VERSION ""

NS_ :

BS_:

BU_: FICM_FD Vector__XXX

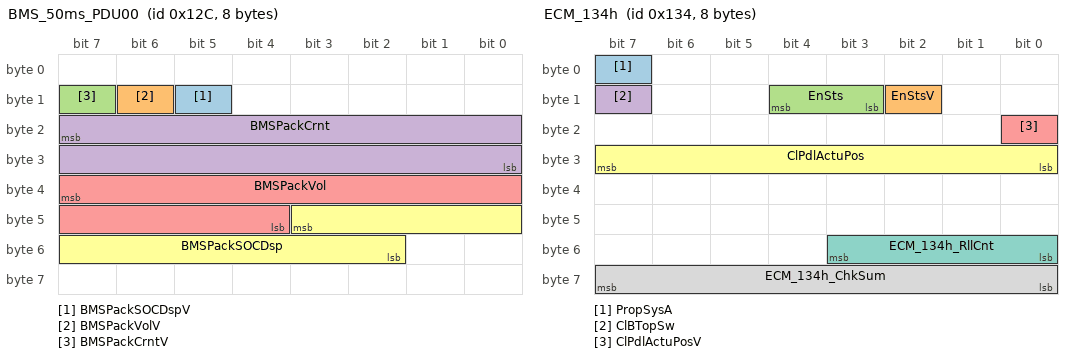
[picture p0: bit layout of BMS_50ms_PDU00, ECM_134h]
BO_ 300 BMS_50ms_PDU00: 8 Vector__XXX
 SG_ BMSPackSOCDspV : 13|1@0+ (1,0) [0|1] ""  FICM_FD
 SG_ BMSPackVolV : 14|1@0+ (1,0) [0|1] ""  FICM_FD
 SG_ BMSPackCrntV : 15|1@0+ (1,0) [0|1] ""  FICM_FD
 SG_ BMSPackCrnt : 23|16@0+ (0.05,-1000) [-1000|2276.75] "A"  FICM_FD
 SG_ BMSPackVol : 39|12@0+ (0.25,0) [0|1023.75] "V"  FICM_FD
 SG_ BMSPackSOCDsp : 43|10@0+ (0.1,0) [0|102.3] "%"  FICM_FD

BO_ 308 ECM_134h: 8 Vector__XXX
 SG_ PropSysA : 7|1@0+ (1,0) [0|1] ""  FICM_FD
 SG_ EnStsV : 10|1@0+ (1,0) [0|1] ""  FICM_FD
 SG_ EnSts : 12|2@0+ (1,0) [0|3] ""  FICM_FD
 SG_ ClBTopSw : 15|1@0+ (1,0) [0|1] ""  FICM_FD
 SG_ ClPdlActuPosV : 16|1@0+ (1,0) [0|1] ""  FICM_FD
 SG_ ClPdlActuPos : 31|8@0+ (0.4,0) [0|100] "%"  FICM_FD
 SG_ ECM_134h_RllCnt : 51|4@0+ (1,0) [0|15] ""  FICM_FD
 SG_ ECM_134h_ChkSum : 63|8@0+ (1,0) [0|255] ""  FICM_FD

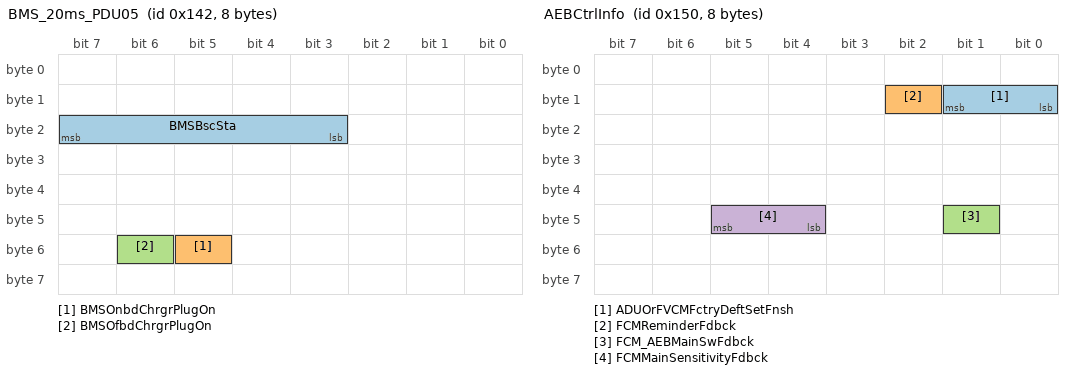
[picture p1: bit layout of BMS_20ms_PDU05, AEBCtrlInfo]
BO_ 322 BMS_20ms_PDU05: 8 Vector__XXX
 SG_ BMSBscSta : 23|5@0+ (1,0) [0|31] ""  FICM_FD
 SG_ BMSOnbdChrgrPlugOn : 53|1@0+ (1,0) [0|1] ""  FICM_FD
 SG_ BMSOfbdChrgrPlugOn : 54|1@0+ (1,0) [0|1] ""  FICM_FD

BO_ 336 AEBCtrlInfo: 8 Vector__XXX
 SG_ ADUOrFVCMFctryDeftSetFnsh : 9|2@0+ (1,0) [0|3] ""  FICM_FD
 SG_ FCMReminderFdbck : 10|1@0+ (1,0) [0|1] ""  FICM_FD
 SG_ FCM_AEBMainSwFdbck : 41|1@0+ (1,0) [0|1] ""  FICM_FD
 SG_ FCMMainSensitivityFdbck : 45|2@0+ (1,0) [0|3] ""  FICM_FD

BO_ 338 ACCCtrlInfo: 8 Vector__XXX
 SG_ ICA_ALCAMainSwFdbck : 5|1@0+ (1,0) [0|1] ""  FICM_FD

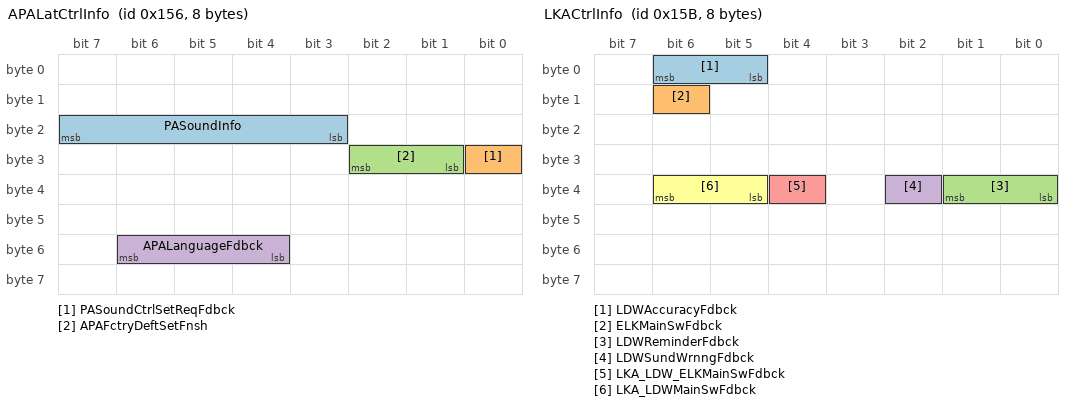
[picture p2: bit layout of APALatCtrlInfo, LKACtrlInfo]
BO_ 342 APALatCtrlInfo: 8 Vector__XXX
 SG_ PASoundInfo : 23|5@0+ (1,0) [0|31] ""  FICM_FD
 SG_ PASoundCtrlSetReqFdbck : 24|1@0+ (1,0) [0|1] ""  FICM_FD
 SG_ APAFctryDeftSetFnsh : 26|2@0+ (1,0) [0|3] ""  FICM_FD
 SG_ APALanguageFdbck : 54|3@0+ (1,0) [0|7] ""  FICM_FD

BO_ 343 APALngtCtrlInfo: 8 Vector__XXX
 SG_ RPASts : 44|3@0+ (1,0) [0|7] ""  FICM_FD
 SG_ APASts : 47|3@0+ (1,0) [0|7] ""  FICM_FD

BO_ 345 AESCtrlInfo: 8 Vector__XXX
 SG_ AESMainSwFdbck : 22|1@0+ (1,0) [0|1] ""  FICM_FD

BO_ 347 LKACtrlInfo: 8 Vector__XXX
 SG_ LDWAccuracyFdbck : 6|2@0+ (1,0) [0|3] ""  FICM_FD
 SG_ ELKMainSwFdbck : 14|1@0+ (1,0) [0|1] ""  FICM_FD
 SG_ LDWReminderFdbck : 33|2@0+ (1,0) [0|3] ""  FICM_FD
 SG_ LDWSundWrnngFdbck : 34|1@0+ (1,0) [0|1] ""  FICM_FD
 SG_ LKA_LDW_ELKMainSwFdbck : 36|1@0+ (1,0) [0|1] ""  FICM_FD
 SG_ LKA_LDWMainSwFdbck : 38|2@0+ (1,0) [0|3] ""  FICM_FD

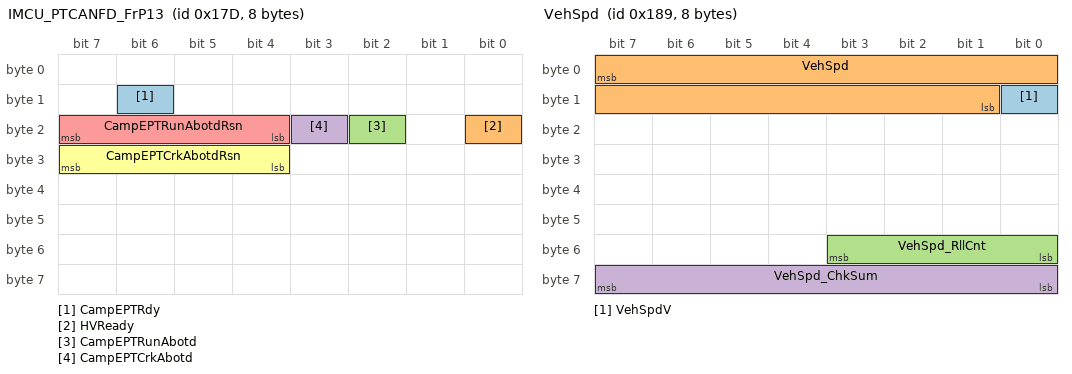
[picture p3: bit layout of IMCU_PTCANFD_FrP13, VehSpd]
BO_ 381 IMCU_PTCANFD_FrP13: 8 Vector__XXX
 SG_ CampEPTRdy : 14|1@0+ (1,0) [0|1] ""  FICM_FD
 SG_ HVReady : 16|1@0+ (1,0) [0|1] ""  FICM_FD
 SG_ CampEPTRunAbotd : 18|1@0+ (1,0) [0|1] ""  FICM_FD
 SG_ CampEPTCrkAbotd : 19|1@0+ (1,0) [0|1] ""  FICM_FD
 SG_ CampEPTRunAbotdRsn : 23|4@0+ (1,0) [0|15] ""  FICM_FD
 SG_ CampEPTCrkAbotdRsn : 31|4@0+ (1,0) [0|15] ""  FICM_FD

BO_ 393 VehSpd: 8 Vector__XXX
 SG_ VehSpdV : 8|1@0+ (1,0) [0|1] ""  FICM_FD
 SG_ VehSpd : 7|15@0+ (0.015625,0) [0|511.98] "km/h"  FICM_FD
 SG_ VehSpd_RllCnt : 51|4@0+ (1,0) [0|15] ""  FICM_FD
 SG_ VehSpd_ChkSum : 63|8@0+ (1,0) [0|255] ""  FICM_FD

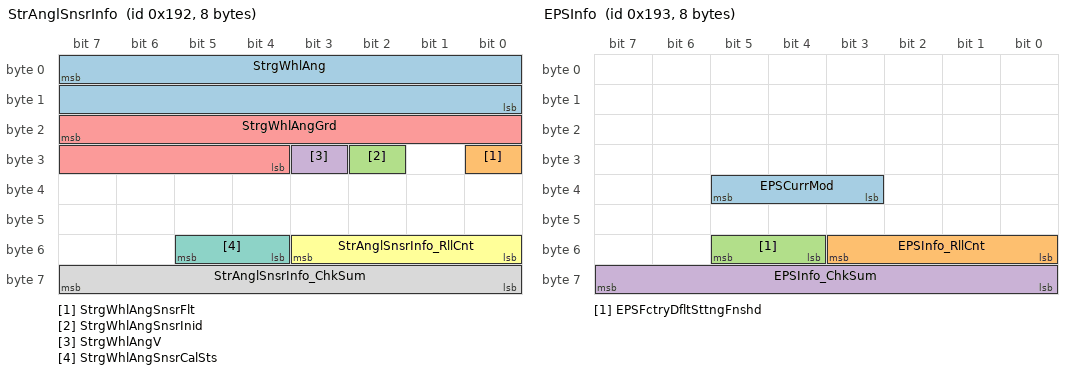
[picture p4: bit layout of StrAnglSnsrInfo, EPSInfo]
BO_ 402 StrAnglSnsrInfo: 8 Vector__XXX
 SG_ StrgWhlAng : 7|16@0+ (0.0625,-2048) [-2048|2047.9375] "deg"  FICM_FD
 SG_ StrgWhlAngSnsrFlt : 24|1@0+ (1,0) [0|1] ""  FICM_FD
 SG_ StrgWhlAngSnsrInid : 26|1@0+ (1,0) [0|1] ""  FICM_FD
 SG_ StrgWhlAngV : 27|1@0+ (1,0) [0|1] ""  FICM_FD
 SG_ StrgWhlAngGrd : 23|12@0+ (1,-2048) [-2048|2047] "deg/s"  FICM_FD
 SG_ StrAnglSnsrInfo_RllCnt : 51|4@0+ (1,0) [0|15] ""  FICM_FD
 SG_ StrgWhlAngSnsrCalSts : 53|2@0+ (1,0) [0|3] ""  FICM_FD
 SG_ StrAnglSnsrInfo_ChkSum : 63|8@0+ (1,0) [0|255] ""  FICM_FD

BO_ 403 EPSInfo: 8 Vector__XXX
 SG_ EPSCurrMod : 37|3@0+ (1,0) [0|7] ""  FICM_FD
 SG_ EPSInfo_RllCnt : 51|4@0+ (1,0) [0|15] ""  FICM_FD
 SG_ EPSFctryDfltSttngFnshd : 53|2@0+ (1,0) [0|3] ""  FICM_FD
 SG_ EPSInfo_ChkSum : 63|8@0+ (1,0) [0|255] ""  FICM_FD

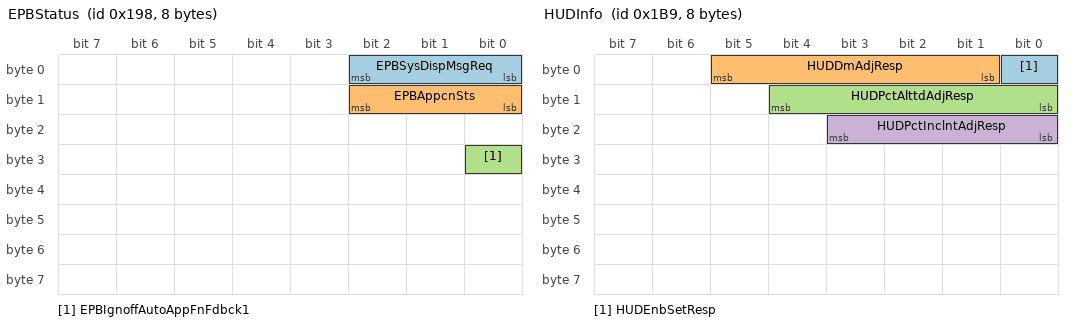
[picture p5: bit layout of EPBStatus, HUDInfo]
BO_ 408 EPBStatus: 8 Vector__XXX
 SG_ EPBSysDispMsgReq : 2|3@0+ (1,0) [0|7] ""  FICM_FD
 SG_ EPBAppcnSts : 10|3@0+ (1,0) [0|7] ""  FICM_FD
 SG_ EPBIgnoffAutoAppFnFdbck1 : 24|1@0+ (1,0) [0|1] ""  FICM_FD

BO_ 441 HUDInfo: 8 Vector__XXX
 SG_ HUDEnbSetResp : 0|1@0+ (1,0) [0|1] ""  FICM_FD
 SG_ HUDDmAdjResp : 5|5@0+ (1,0) [0|31] ""  FICM_FD
 SG_ HUDPctAlttdAdjResp : 12|5@0+ (1,0) [0|31] ""  FICM_FD
 SG_ HUDPctInclntAdjResp : 19|4@0+ (1,0) [0|15] ""  FICM_FD

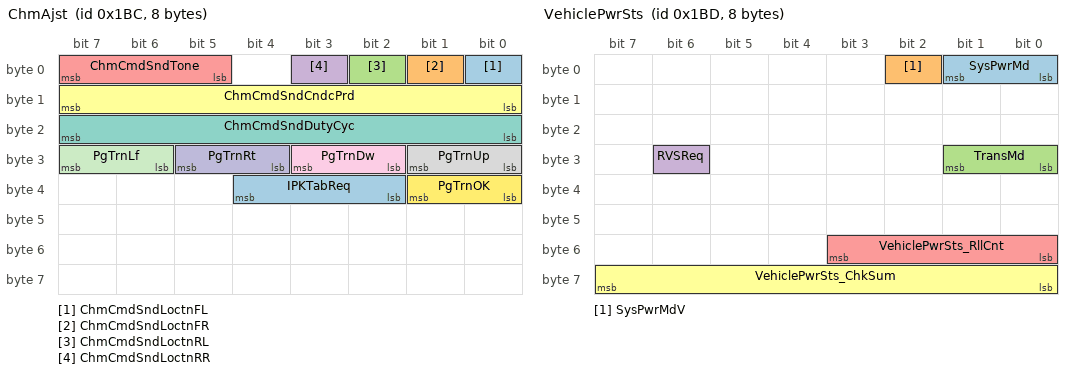
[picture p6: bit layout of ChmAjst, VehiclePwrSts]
BO_ 444 ChmAjst: 8 Vector__XXX
 SG_ ChmCmdSndLoctnFL : 0|1@0+ (1,0) [0|1] ""  FICM_FD
 SG_ ChmCmdSndLoctnFR : 1|1@0+ (1,0) [0|1] ""  FICM_FD
 SG_ ChmCmdSndLoctnRL : 2|1@0+ (1,0) [0|1] ""  FICM_FD
 SG_ ChmCmdSndLoctnRR : 3|1@0+ (1,0) [0|1] ""  FICM_FD
 SG_ ChmCmdSndTone : 7|3@0+ (1,0) [0|7] ""  FICM_FD
 SG_ ChmCmdSndCndcPrd : 15|8@0+ (10,0) [0|2550] ""  FICM_FD
 SG_ ChmCmdSndDutyCyc : 23|8@0+ (0.4,0) [0|100] "%"  FICM_FD
 SG_ PgTrnUp : 25|2@0+ (1,0) [0|3] ""  FICM_FD
 SG_ PgTrnDw : 27|2@0+ (1,0) [0|3] ""  FICM_FD
 SG_ PgTrnRt : 29|2@0+ (1,0) [0|3] ""  FICM_FD
 SG_ PgTrnLf : 31|2@0+ (1,0) [0|3] ""  FICM_FD
 SG_ PgTrnOK : 33|2@0+ (1,0) [0|3] ""  FICM_FD
 SG_ IPKTabReq : 36|3@0+ (1,0) [0|7] ""  FICM_FD

BO_ 445 VehiclePwrSts: 8 Vector__XXX
 SG_ SysPwrMd : 1|2@0+ (1,0) [0|3] ""  FICM_FD
 SG_ SysPwrMdV : 2|1@0+ (1,0) [0|1] ""  FICM_FD
 SG_ TransMd : 25|2@0+ (1,0) [0|3] ""  FICM_FD
 SG_ RVSReq : 30|1@0+ (1,0) [0|1] ""  FICM_FD
 SG_ VehiclePwrSts_RllCnt : 51|4@0+ (1,0) [0|15] ""  FICM_FD
 SG_ VehiclePwrSts_ChkSum : 63|8@0+ (1,0) [0|255] ""  FICM_FD

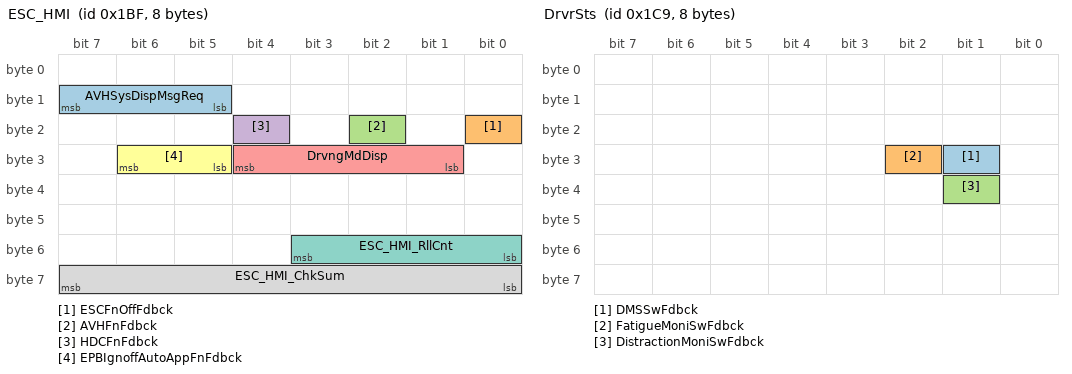
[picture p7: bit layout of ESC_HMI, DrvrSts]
BO_ 447 ESC_HMI: 8 Vector__XXX
 SG_ AVHSysDispMsgReq : 15|3@0+ (1,0) [0|7] ""  FICM_FD
 SG_ ESCFnOffFdbck : 16|1@0+ (1,0) [0|1] ""  FICM_FD
 SG_ AVHFnFdbck : 18|1@0+ (1,0) [0|1] ""  FICM_FD
 SG_ HDCFnFdbck : 20|1@0+ (1,0) [0|1] ""  FICM_FD
 SG_ DrvngMdDisp : 28|4@0+ (1,0) [0|15] ""  FICM_FD
 SG_ EPBIgnoffAutoAppFnFdbck : 30|2@0+ (1,0) [0|3] ""  FICM_FD
 SG_ ESC_HMI_RllCnt : 51|4@0+ (1,0) [0|15] ""  FICM_FD
 SG_ ESC_HMI_ChkSum : 63|8@0+ (1,0) [0|255] ""  FICM_FD

BO_ 457 DrvrSts: 8 Vector__XXX
 SG_ DMSSwFdbck : 25|1@0+ (1,0) [0|1] ""  FICM_FD
 SG_ FatigueMoniSwFdbck : 26|1@0+ (1,0) [0|1] ""  FICM_FD
 SG_ DistractionMoniSwFdbck : 33|1@0+ (1,0) [0|1] ""  FICM_FD

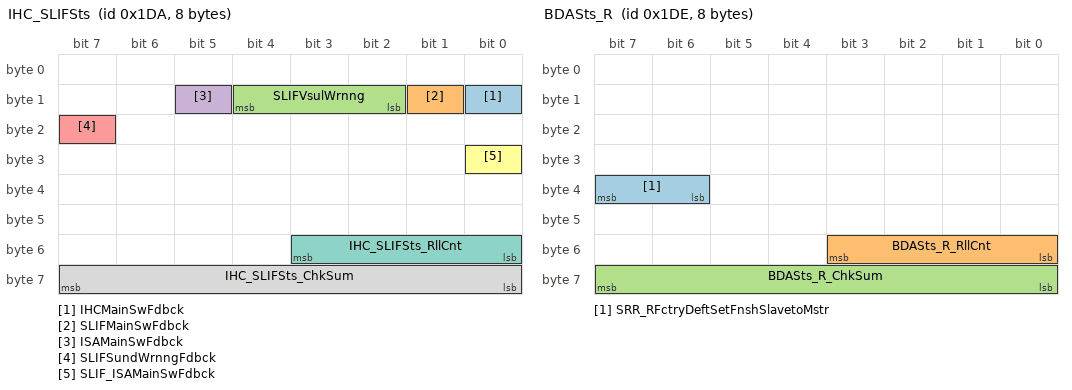
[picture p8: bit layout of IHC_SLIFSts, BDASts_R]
BO_ 474 IHC_SLIFSts: 8 Vector__XXX
 SG_ IHCMainSwFdbck : 8|1@0+ (1,0) [0|1] ""  FICM_FD
 SG_ SLIFMainSwFdbck : 9|1@0+ (1,0) [0|1] ""  FICM_FD
 SG_ SLIFVsulWrnng : 12|3@0+ (1,0) [0|7] ""  FICM_FD
 SG_ ISAMainSwFdbck : 13|1@0+ (1,0) [0|1] ""  FICM_FD
 SG_ SLIFSundWrnngFdbck : 23|1@0+ (1,0) [0|1] ""  FICM_FD
 SG_ SLIF_ISAMainSwFdbck : 24|1@0+ (1,0) [0|1] ""  FICM_FD
 SG_ IHC_SLIFSts_RllCnt : 51|4@0+ (1,0) [0|15] ""  FICM_FD
 SG_ IHC_SLIFSts_ChkSum : 63|8@0+ (1,0) [0|255] ""  FICM_FD

BO_ 476 FCTA_RCWInfo: 8 Vector__XXX
 SG_ RAEBSta : 28|3@0+ (1,0) [0|7] ""  FICM_FD

BO_ 478 BDASts_R: 8 Vector__XXX
 SG_ SRR_RFctryDeftSetFnshSlavetoMstr : 39|2@0+ (1,0) [0|3] ""  FICM_FD
 SG_ BDASts_R_RllCnt : 51|4@0+ (1,0) [0|15] ""  FICM_FD
 SG_ BDASts_R_ChkSum : 63|8@0+ (1,0) [0|255] ""  FICM_FD

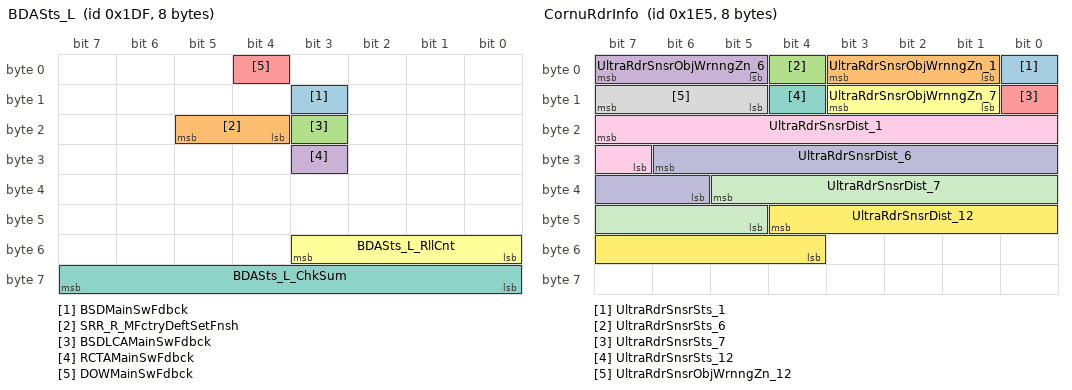
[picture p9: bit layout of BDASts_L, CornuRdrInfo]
BO_ 479 BDASts_L: 8 Vector__XXX
 SG_ BSDMainSwFdbck : 11|1@0+ (1,0) [0|1] ""  FICM_FD
 SG_ SRR_R_MFctryDeftSetFnsh : 21|2@0+ (1,0) [0|3] ""  FICM_FD
 SG_ BSDLCAMainSwFdbck : 19|1@0+ (1,0) [0|1] ""  FICM_FD
 SG_ RCTAMainSwFdbck : 27|1@0+ (1,0) [0|1] ""  FICM_FD
 SG_ DOWMainSwFdbck : 4|1@0+ (1,0) [0|1] ""  FICM_FD
 SG_ BDASts_L_RllCnt : 51|4@0+ (1,0) [0|15] ""  FICM_FD
 SG_ BDASts_L_ChkSum : 63|8@0+ (1,0) [0|255] ""  FICM_FD

BO_ 485 CornuRdrInfo: 8 Vector__XXX
 SG_ UltraRdrSnsrSts_1 : 0|1@0+ (1,0) [0|1] ""  FICM_FD
 SG_ UltraRdrSnsrObjWrnngZn_1 : 3|3@0+ (1,0) [0|7] ""  FICM_FD
 SG_ UltraRdrSnsrSts_6 : 4|1@0+ (1,0) [0|1] ""  FICM_FD
 SG_ UltraRdrSnsrObjWrnngZn_6 : 7|3@0+ (1,0) [0|7] ""  FICM_FD
 SG_ UltraRdrSnsrSts_7 : 8|1@0+ (1,0) [0|1] ""  FICM_FD
 SG_ UltraRdrSnsrObjWrnngZn_7 : 11|3@0+ (1,0) [0|7] ""  FICM_FD
 SG_ UltraRdrSnsrSts_12 : 12|1@0+ (1,0) [0|1] ""  FICM_FD
 SG_ UltraRdrSnsrObjWrnngZn_12 : 15|3@0+ (1,0) [0|7] ""  FICM_FD
 SG_ UltraRdrSnsrDist_1 : 23|9@0+ (1,0) [0|510] "cm"  FICM_FD
 SG_ UltraRdrSnsrDist_6 : 30|9@0+ (1,0) [0|510] "cm"  FICM_FD
 SG_ UltraRdrSnsrDist_7 : 37|9@0+ (1,0) [0|510] "cm"  FICM_FD
 SG_ UltraRdrSnsrDist_12 : 44|9@0+ (1,0) [0|510] "cm"  FICM_FD

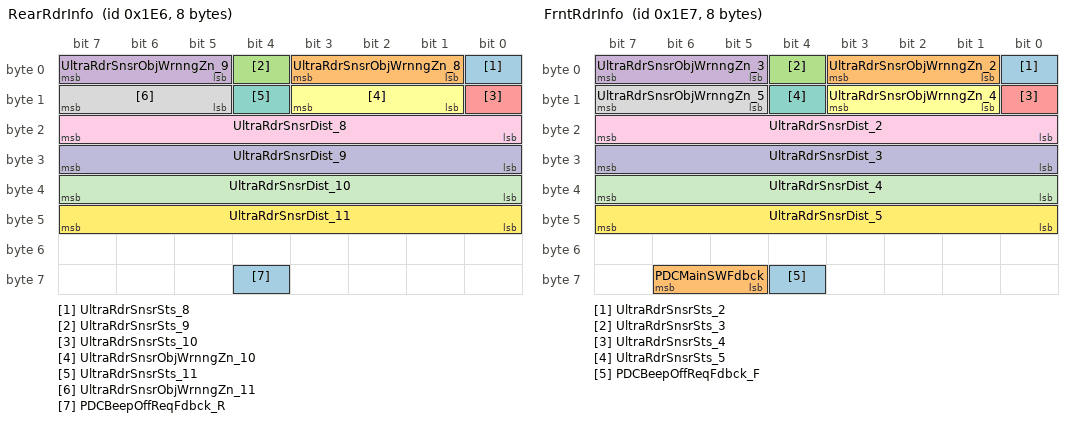
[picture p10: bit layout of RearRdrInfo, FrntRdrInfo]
BO_ 486 RearRdrInfo: 8 Vector__XXX
 SG_ UltraRdrSnsrSts_8 : 0|1@0+ (1,0) [0|1] ""  FICM_FD
 SG_ UltraRdrSnsrObjWrnngZn_8 : 3|3@0+ (1,0) [0|7] ""  FICM_FD
 SG_ UltraRdrSnsrSts_9 : 4|1@0+ (1,0) [0|1] ""  FICM_FD
 SG_ UltraRdrSnsrObjWrnngZn_9 : 7|3@0+ (1,0) [0|7] ""  FICM_FD
 SG_ UltraRdrSnsrSts_10 : 8|1@0+ (1,0) [0|1] ""  FICM_FD
 SG_ UltraRdrSnsrObjWrnngZn_10 : 11|3@0+ (1,0) [0|7] ""  FICM_FD
 SG_ UltraRdrSnsrSts_11 : 12|1@0+ (1,0) [0|1] ""  FICM_FD
 SG_ UltraRdrSnsrObjWrnngZn_11 : 15|3@0+ (1,0) [0|7] ""  FICM_FD
 SG_ UltraRdrSnsrDist_8 : 23|8@0+ (1,0) [0|254] "cm"  FICM_FD
 SG_ UltraRdrSnsrDist_9 : 31|8@0+ (1,0) [0|254] "cm"  FICM_FD
 SG_ UltraRdrSnsrDist_10 : 39|8@0+ (1,0) [0|254] "cm"  FICM_FD
 SG_ UltraRdrSnsrDist_11 : 47|8@0+ (1,0) [0|254] "cm"  FICM_FD
 SG_ PDCBeepOffReqFdbck_R : 60|1@0+ (1,0) [0|1] ""  FICM_FD

BO_ 487 FrntRdrInfo: 8 Vector__XXX
 SG_ UltraRdrSnsrSts_2 : 0|1@0+ (1,0) [0|1] ""  FICM_FD
 SG_ UltraRdrSnsrObjWrnngZn_2 : 3|3@0+ (1,0) [0|7] ""  FICM_FD
 SG_ UltraRdrSnsrSts_3 : 4|1@0+ (1,0) [0|1] ""  FICM_FD
 SG_ UltraRdrSnsrObjWrnngZn_3 : 7|3@0+ (1,0) [0|7] ""  FICM_FD
 SG_ UltraRdrSnsrSts_4 : 8|1@0+ (1,0) [0|1] ""  FICM_FD
 SG_ UltraRdrSnsrObjWrnngZn_4 : 11|3@0+ (1,0) [0|7] ""  FICM_FD
 SG_ UltraRdrSnsrSts_5 : 12|1@0+ (1,0) [0|1] ""  FICM_FD
 SG_ UltraRdrSnsrObjWrnngZn_5 : 15|3@0+ (1,0) [0|7] ""  FICM_FD
 SG_ UltraRdrSnsrDist_2 : 23|8@0+ (1,0) [0|254] "cm"  FICM_FD
 SG_ UltraRdrSnsrDist_3 : 31|8@0+ (1,0) [0|254] "cm"  FICM_FD
 SG_ UltraRdrSnsrDist_4 : 39|8@0+ (1,0) [0|254] "cm"  FICM_FD
 SG_ UltraRdrSnsrDist_5 : 47|8@0+ (1,0) [0|254] "cm"  FICM_FD
 SG_ PDCBeepOffReqFdbck_F : 60|1@0+ (1,0) [0|1] ""  FICM_FD
 SG_ PDCMainSWFdbck : 62|2@0+ (1,0) [0|3] ""  FICM_FD

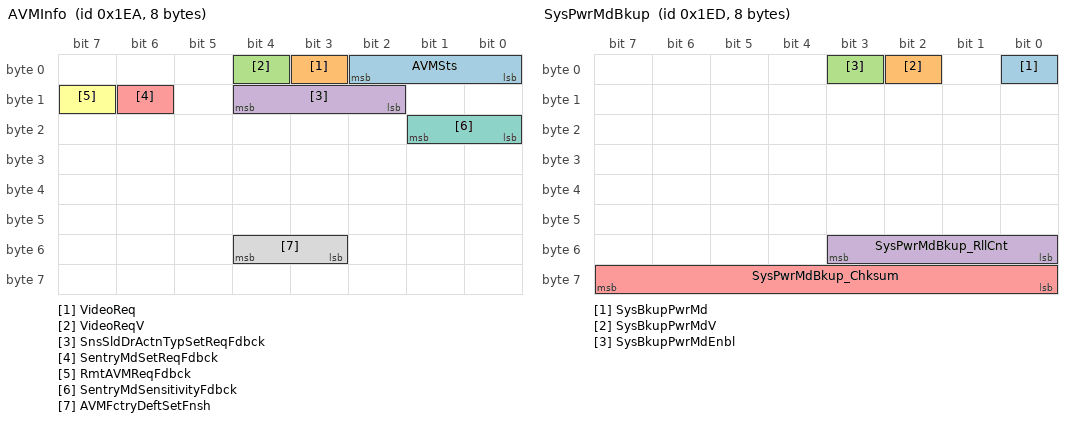
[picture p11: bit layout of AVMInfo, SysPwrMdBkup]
BO_ 490 AVMInfo: 8 FICM_FD
 SG_ AVMSts : 2|3@0+ (1,0) [0|7] ""  FICM_FD,Vector__XXX
 SG_ VideoReq : 3|1@0+ (1,0) [0|1] ""  FICM_FD,Vector__XXX
 SG_ VideoReqV : 4|1@0+ (1,0) [0|1] ""  FICM_FD,Vector__XXX
 SG_ SnsSldDrActnTypSetReqFdbck : 12|3@0+ (1,0) [0|7] ""  FICM_FD,Vector__XXX
 SG_ SentryMdSetReqFdbck : 14|1@0+ (1,0) [0|1] ""  FICM_FD,Vector__XXX
 SG_ RmtAVMReqFdbck : 15|1@0+ (1,0) [0|1] ""  FICM_FD,Vector__XXX
 SG_ SentryMdSensitivityFdbck : 17|2@0+ (1,0) [0|3] ""  FICM_FD,Vector__XXX
 SG_ AVMFctryDeftSetFnsh : 52|2@0+ (1,0) [0|3] ""  FICM_FD,Vector__XXX

BO_ 493 SysPwrMdBkup: 8 Vector__XXX
 SG_ SysBkupPwrMd : 0|1@0+ (1,0) [0|1] ""  FICM_FD
 SG_ SysBkupPwrMdV : 2|1@0+ (1,0) [0|1] ""  FICM_FD
 SG_ SysBkupPwrMdEnbl : 3|1@0+ (1,0) [0|1] ""  FICM_FD
 SG_ SysPwrMdBkup_RllCnt : 51|4@0+ (1,0) [0|15] ""  FICM_FD
 SG_ SysPwrMdBkup_Chksum : 63|8@0+ (1,0) [0|255] ""  FICM_FD

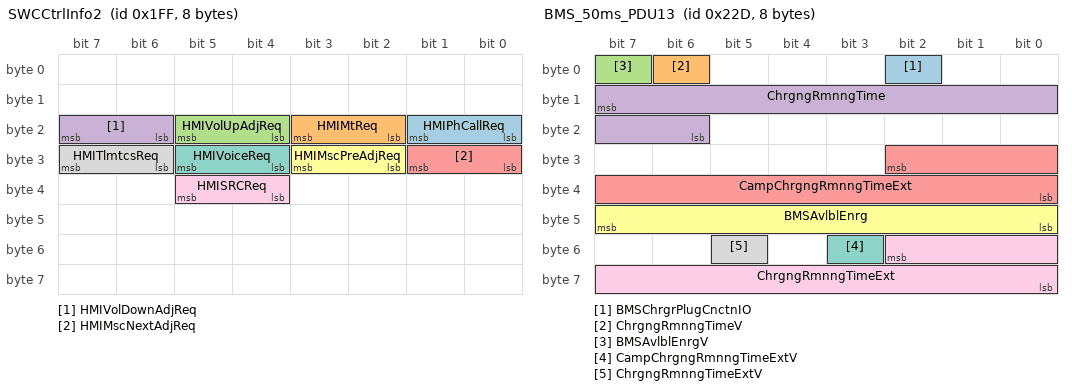
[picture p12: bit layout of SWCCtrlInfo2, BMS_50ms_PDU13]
BO_ 511 SWCCtrlInfo2: 8 Vector__XXX
 SG_ HMIPhCallReq : 17|2@0+ (1,0) [0|3] ""  FICM_FD
 SG_ HMIMtReq : 19|2@0+ (1,0) [0|3] ""  FICM_FD
 SG_ HMIVolUpAdjReq : 21|2@0+ (1,0) [0|3] ""  FICM_FD
 SG_ HMIVolDownAdjReq : 23|2@0+ (1,0) [0|3] ""  FICM_FD
 SG_ HMIMscNextAdjReq : 25|2@0+ (1,0) [0|3] ""  FICM_FD
 SG_ HMIMscPreAdjReq : 27|2@0+ (1,0) [0|3] ""  FICM_FD
 SG_ HMIVoiceReq : 29|2@0+ (1,0) [0|3] ""  FICM_FD
 SG_ HMITlmtcsReq : 31|2@0+ (1,0) [0|3] ""  FICM_FD
 SG_ HMISRCReq : 37|2@0+ (1,0) [0|3] ""  FICM_FD

BO_ 557 BMS_50ms_PDU13: 8 Vector__XXX
 SG_ BMSChrgrPlugCnctnIO : 2|1@0+ (1,0) [0|1] ""  FICM_FD
 SG_ ChrgngRmnngTimeV : 6|1@0+ (1,0) [0|1] ""  FICM_FD
 SG_ BMSAvlblEnrgV : 7|1@0+ (1,0) [0|1] ""  FICM_FD
 SG_ ChrgngRmnngTime : 15|10@0+ (1,0) [0|1023] "min"  FICM_FD
 SG_ CampChrgngRmnngTimeExt : 26|11@0+ (1,0) [0|2047] "min"  FICM_FD
 SG_ BMSAvlblEnrg : 47|8@0+ (0.4,0) [0|102] "KWH"  FICM_FD
 SG_ CampChrgngRmnngTimeExtV : 51|1@0+ (1,0) [0|1] ""  FICM_FD
 SG_ ChrgngRmnngTimeExtV : 53|1@0+ (1,0) [0|1] ""  FICM_FD
 SG_ ChrgngRmnngTimeExt : 50|11@0+ (1,0) [0|2047] "min"  FICM_FD

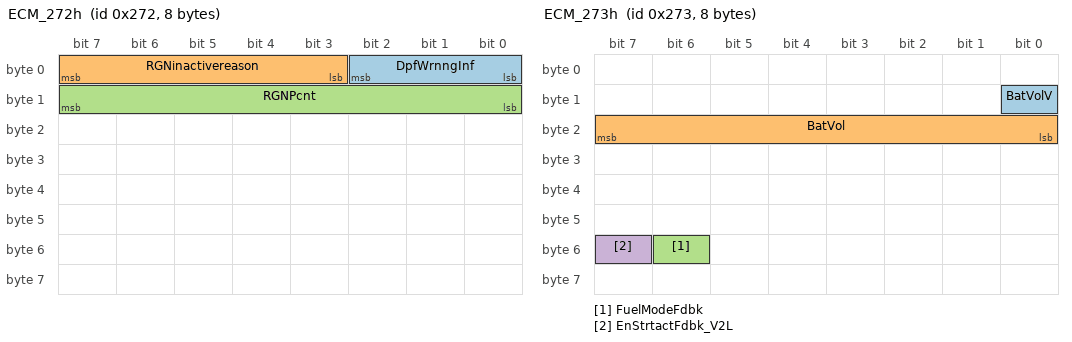
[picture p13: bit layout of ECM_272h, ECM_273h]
BO_ 626 ECM_272h: 8 Vector__XXX
 SG_ DpfWrnngInf : 2|3@0+ (1,0) [0|7] ""  FICM_FD
 SG_ RGNinactivereason : 7|5@0+ (1,0) [0|31] ""  FICM_FD
 SG_ RGNPcnt : 15|8@0+ (1,0) [0|100] "%"  FICM_FD

BO_ 627 ECM_273h: 8 Vector__XXX
 SG_ BatVolV : 8|1@0+ (1,0) [0|1] ""  FICM_FD
 SG_ BatVol : 23|8@0+ (0.1,3) [3|18.99] "V"  FICM_FD
 SG_ FuelModeFdbk : 54|1@0+ (1,0) [0|1] ""  FICM_FD
 SG_ EnStrtactFdbk_V2L : 55|1@0+ (1,0) [0|1] ""  FICM_FD

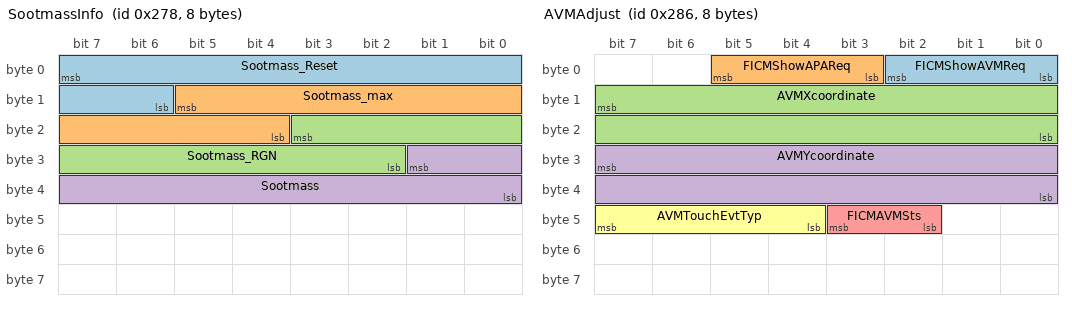
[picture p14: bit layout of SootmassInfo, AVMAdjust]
BO_ 632 SootmassInfo: 8 Vector__XXX
 SG_ Sootmass_Reset : 7|10@0+ (0.1,0) [0|100] "g"  FICM_FD
 SG_ Sootmass_max : 13|10@0+ (0.1,0) [0|100] "g"  FICM_FD
 SG_ Sootmass_RGN : 19|10@0+ (0.1,0) [0|100] "g"  FICM_FD
 SG_ Sootmass : 25|10@0+ (0.1,0) [0|100] "g"  FICM_FD

BO_ 646 AVMAdjust: 8 FICM_FD
 SG_ FICMShowAVMReq : 2|3@0+ (1,0) [0|7] ""  Vector__XXX
 SG_ FICMShowAPAReq : 5|3@0+ (1,0) [0|7] ""  Vector__XXX
 SG_ AVMXcoordinate : 15|16@0+ (1,0) [0|1920] "pixel"  Vector__XXX
 SG_ AVMYcoordinate : 31|16@0+ (1,0) [0|720] "pixel"  Vector__XXX
 SG_ FICMAVMSts : 43|2@0+ (1,0) [0|3] ""  Vector__XXX
 SG_ AVMTouchEvtTyp : 47|4@0+ (1,0) [0|15] ""  Vector__XXX

BO_ 676 AirConditionerSts: 8 Vector__XXX
 SG_ OtsdAirTemCrVal : 23|8@0+ (0.5,-40) [-40|87.5] "deg C"  FICM_FD
 SG_ OtsdAirTemCrValV : 31|1@0+ (1,0) [0|1] ""  FICM_FD

BO_ 677 FrntACInfo: 8 Vector__XXX
 SG_ HVACFrontAirVolume : 3|4@0+ (1,0) [0|15] ""  FICM_FD
 SG_ HVACFrontMode : 7|4@0+ (1,0) [0|15] ""  FICM_FD
 SG_ HVACLeftSetTemperature : 15|8@0+ (1,-40) [-40|214] "deg"  FICM_FD
 SG_ HVACRightSetTemperature : 23|8@0+ (1,-40) [-40|214] "deg"  FICM_FD
 SG_ HVACInCarTermperature : 31|8@0+ (0.5,-30) [-30|97] "℃"  FICM_FD
 SG_ HVACCycleMode : 33|2@0+ (1,0) [0|3] ""  FICM_FD
 SG_ HVACFrontDefrostStatus : 34|1@0+ (1,0) [0|1] ""  FICM_FD
 SG_ HVACRearDefrostStatus : 35|1@0+ (1,0) [0|1] ""  FICM_FD
 SG_ HVACAutoIndicationStatus : 36|1@0+ (1,0) [0|1] ""  FICM_FD
 SG_ HVACFrontPowerStatus : 37|1@0+ (1,0) [0|1] ""  FICM_FD
 SG_ HVACOnRequestIndication : 38|1@0+ (1,0) [0|1] ""  FICM_FD
 SG_ HVACSYNCDspCmd : 39|1@0+ (1,0) [0|1] ""  FICM_FD
 SG_ PTC_WRK_LEVEL : 41|2@0+ (1,0) [0|3] ""  FICM_FD
 SG_ HVACAtDefSts : 42|1@0+ (1,0) [0|1] ""  FICM_FD
 SG_ HVACQuietSetStatus : 43|1@0+ (1,0) [0|1] ""  FICM_FD
 SG_ HVACFrontACMaxStatus : 46|1@0+ (1,0) [0|1] ""  FICM_FD
 SG_ InsdAirPrtclMtrCDC : 55|8@0+ (2,0) [0|510] "ug/m3"  FICM_FD

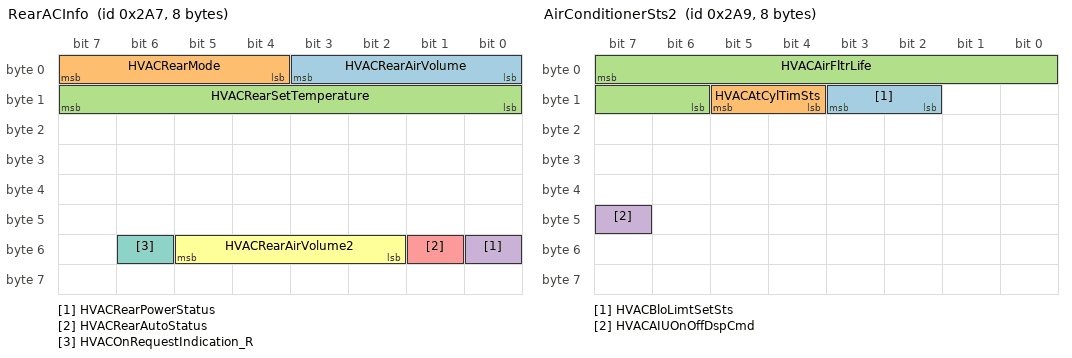
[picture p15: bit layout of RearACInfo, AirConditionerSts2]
BO_ 679 RearACInfo: 8 Vector__XXX
 SG_ HVACRearAirVolume : 3|4@0+ (1,0) [0|15] ""  FICM_FD
 SG_ HVACRearMode : 7|4@0+ (1,0) [0|15] ""  FICM_FD
 SG_ HVACRearSetTemperature : 15|8@0+ (1,-40) [-40|214] "deg"  FICM_FD
 SG_ HVACRearPowerStatus : 48|1@0+ (1,0) [0|1] ""  FICM_FD
 SG_ HVACRearAutoStatus : 49|1@0+ (1,0) [0|1] ""  FICM_FD
 SG_ HVACRearAirVolume2 : 53|4@0+ (1,0) [0|15] ""  FICM_FD
 SG_ HVACOnRequestIndication_R : 54|1@0+ (1,0) [0|1] ""  FICM_FD

BO_ 680 AirVentSts: 8 Vector__XXX
 SG_ LeftArVetLRSwingSts : 7|8@0+ (1,0) [0|100] "%"  FICM_FD
 SG_ LeftMidArVetLRSwingSts : 15|8@0+ (1,0) [0|100] "%"  FICM_FD
 SG_ RightMidArVetLRSwingSts : 23|8@0+ (1,0) [0|100] "%"  FICM_FD
 SG_ RightArVetSwingLRSts : 31|8@0+ (1,0) [0|100] "%"  FICM_FD
 SG_ LeftArVetUDSwingSts : 35|4@0+ (10,0) [0|100] "%"  FICM_FD
 SG_ LeftMidArVetUDSwingSts : 39|4@0+ (10,0) [0|100] "%"  FICM_FD
 SG_ RightMidArVetUDSwingSts : 43|4@0+ (10,0) [0|100] "%"  FICM_FD
 SG_ RightArVetSwingUDSts : 47|4@0+ (10,0) [0|100] "%"  FICM_FD
 SG_ LeftArVetFosSts : 48|1@0+ (1,0) [0|1] ""  FICM_FD
 SG_ RightArVetFosSts : 49|1@0+ (1,0) [0|1] ""  FICM_FD
 SG_ LeftArVetDistribSts : 50|1@0+ (1,0) [0|1] ""  FICM_FD
 SG_ RightArVetDistribSts : 51|1@0+ (1,0) [0|1] ""  FICM_FD
 SG_ LeftArVetSweepSts : 52|1@0+ (1,0) [0|1] ""  FICM_FD
 SG_ RightArVetSweepSts : 53|1@0+ (1,0) [0|1] ""  FICM_FD
 SG_ LeftArVetOnOffSts : 54|1@0+ (1,0) [0|1] ""  FICM_FD
 SG_ RightArVetOnOffSts : 55|1@0+ (1,0) [0|1] ""  FICM_FD
 SG_ HVACLeavVentSts : 56|1@0+ (1,0) [0|1] ""  FICM_FD

BO_ 681 AirConditionerSts2: 8 Vector__XXX
 SG_ HVACBloLimtSetSts : 11|2@0+ (1,0) [0|3] ""  FICM_FD
 SG_ HVACAtCylTimSts : 13|2@0+ (1,0) [0|3] ""  FICM_FD
 SG_ HVACAirFltrLife : 7|10@0+ (1,0) [0|1023] "h"  FICM_FD
 SG_ HVACAIUOnOffDspCmd : 47|1@0+ (1,0) [0|1] ""  FICM_FD

BO_ 682 AirConditionerSts3: 8 Vector__XXX
 SG_ OtsdAirTemRawData : 7|8@0+ (0.5,-40) [-40|87.5] "deg C"  FICM_FD

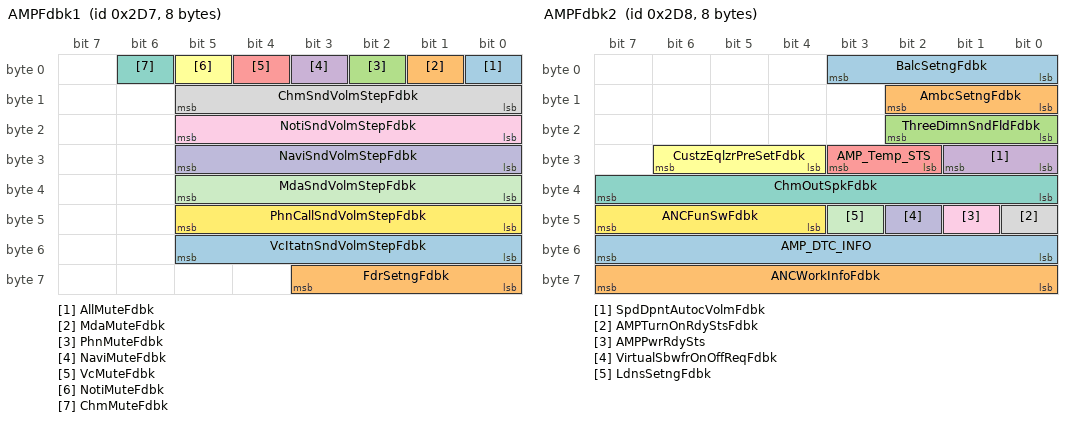
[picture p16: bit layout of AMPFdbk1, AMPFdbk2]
BO_ 727 AMPFdbk1: 8 Vector__XXX
 SG_ AllMuteFdbk : 0|1@0+ (1,0) [0|1] ""  FICM_FD
 SG_ MdaMuteFdbk : 1|1@0+ (1,0) [0|1] ""  FICM_FD
 SG_ PhnMuteFdbk : 2|1@0+ (1,0) [0|1] ""  FICM_FD
 SG_ NaviMuteFdbk : 3|1@0+ (1,0) [0|1] ""  FICM_FD
 SG_ VcMuteFdbk : 4|1@0+ (1,0) [0|1] ""  FICM_FD
 SG_ NotiMuteFdbk : 5|1@0+ (1,0) [0|1] ""  FICM_FD
 SG_ ChmMuteFdbk : 6|1@0+ (1,0) [0|1] ""  FICM_FD
 SG_ ChmSndVolmStepFdbk : 13|6@0+ (1,0) [0|63] ""  FICM_FD
 SG_ NotiSndVolmStepFdbk : 21|6@0+ (1,0) [0|63] ""  FICM_FD
 SG_ NaviSndVolmStepFdbk : 29|6@0+ (1,0) [0|63] ""  FICM_FD
 SG_ MdaSndVolmStepFdbk : 37|6@0+ (1,0) [0|63] ""  FICM_FD
 SG_ PhnCallSndVolmStepFdbk : 45|6@0+ (1,0) [0|63] ""  FICM_FD
 SG_ VcItatnSndVolmStepFdbk : 53|6@0+ (1,0) [0|63] ""  FICM_FD
 SG_ FdrSetngFdbk : 59|4@0+ (1,0) [0|15] ""  FICM_FD

BO_ 728 AMPFdbk2: 8 Vector__XXX
 SG_ BalcSetngFdbk : 3|4@0+ (1,0) [0|15] ""  FICM_FD
 SG_ AmbcSetngFdbk : 10|3@0+ (1,0) [0|7] ""  FICM_FD
 SG_ ThreeDimnSndFldFdbk : 18|3@0+ (1,0) [0|7] ""  FICM_FD
 SG_ SpdDpntAutocVolmFdbk : 25|2@0+ (1,0) [0|3] ""  FICM_FD
 SG_ AMP_Temp_STS : 27|2@0+ (1,0) [0|3] ""  FICM_FD
 SG_ CustzEqlzrPreSetFdbk : 30|3@0+ (1,0) [0|7] ""  FICM_FD
 SG_ ChmOutSpkFdbk : 39|8@0+ (1,0) [0|255] ""  FICM_FD
 SG_ AMPTurnOnRdyStsFdbk : 40|1@0+ (1,0) [0|1] ""  FICM_FD
 SG_ AMPPwrRdySts : 41|1@0+ (1,0) [0|1] ""  FICM_FD
 SG_ VirtualSbwfrOnOffReqFdbk : 42|1@0+ (1,0) [0|1] ""  FICM_FD
 SG_ LdnsSetngFdbk : 43|1@0+ (1,0) [0|1] ""  FICM_FD
 SG_ ANCFunSwFdbk : 47|4@0+ (1,0) [0|15] ""  FICM_FD
 SG_ AMP_DTC_INFO : 55|8@0+ (1,0) [0|255] ""  FICM_FD
 SG_ ANCWorkInfoFdbk : 63|8@0+ (1,0) [0|255] ""  FICM_FD

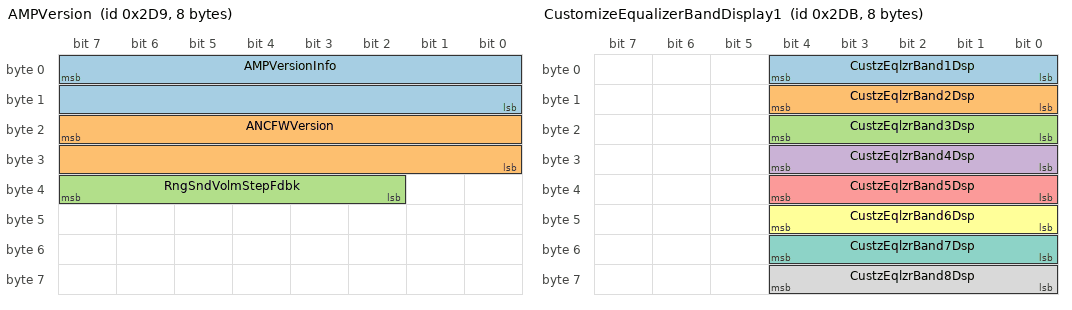
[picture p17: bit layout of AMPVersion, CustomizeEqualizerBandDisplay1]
BO_ 729 AMPVersion: 8 Vector__XXX
 SG_ AMPVersionInfo : 7|16@0+ (1,0) [0|65535] ""  FICM_FD
 SG_ ANCFWVersion : 23|16@0+ (1,0) [0|65535] ""  FICM_FD
 SG_ RngSndVolmStepFdbk : 39|6@0+ (1,0) [0|63] ""  FICM_FD

BO_ 730 AMPSoundDebug: 8 Vector__XXX
 SG_ AMPSoundDB : 7|64@0+ (1,0) [0|18446744073709551615] ""  FICM_FD

BO_ 731 CustomizeEqualizerBandDisplay1: 8 Vector__XXX
 SG_ CustzEqlzrBand1Dsp : 4|5@0+ (1,0) [0|31] ""  FICM_FD
 SG_ CustzEqlzrBand2Dsp : 12|5@0+ (1,0) [0|31] ""  FICM_FD
 SG_ CustzEqlzrBand3Dsp : 20|5@0+ (1,0) [0|31] ""  FICM_FD
 SG_ CustzEqlzrBand4Dsp : 28|5@0+ (1,0) [0|31] ""  FICM_FD
 SG_ CustzEqlzrBand5Dsp : 36|5@0+ (1,0) [0|31] ""  FICM_FD
 SG_ CustzEqlzrBand6Dsp : 44|5@0+ (1,0) [0|31] ""  FICM_FD
 SG_ CustzEqlzrBand7Dsp : 52|5@0+ (1,0) [0|31] ""  FICM_FD
 SG_ CustzEqlzrBand8Dsp : 60|5@0+ (1,0) [0|31] ""  FICM_FD

BO_ 732 AMPReq1: 8 FICM_FD
 SG_ AllMuteReq : 0|1@0+ (1,0) [0|1] ""  Vector__XXX
 SG_ MdaMuteReq : 1|1@0+ (1,0) [0|1] ""  Vector__XXX
 SG_ PhnMuteReq : 2|1@0+ (1,0) [0|1] ""  Vector__XXX
 SG_ NaviMuteReq : 3|1@0+ (1,0) [0|1] ""  Vector__XXX
 SG_ VcMuteReq : 4|1@0+ (1,0) [0|1] ""  Vector__XXX
 SG_ NotiMuteReq : 5|1@0+ (1,0) [0|1] ""  Vector__XXX
 SG_ ChmMuteReq : 6|1@0+ (1,0) [0|1] ""  Vector__XXX
 SG_ FICMAMPStatus : 7|1@0+ (1,0) [0|1] ""  Vector__XXX
 SG_ ChmSndVolmStepReqV : 8|1@0+ (1,0) [0|1] ""  Vector__XXX
 SG_ ChmSndVolmStepReq : 14|6@0+ (1,0) [0|63] "/"  Vector__XXX
 SG_ FICMAvlblSts : 15|1@0+ (1,0) [0|1] ""  Vector__XXX
 SG_ NotiSndVolmStepReqV : 16|1@0+ (1,0) [0|1] "/"  Vector__XXX
 SG_ NotiSndVolmStepReq : 22|6@0+ (1,0) [0|63] "/"  Vector__XXX
 SG_ LVDSMdaReady : 23|1@0+ (1,0) [0|1] ""  Vector__XXX
 SG_ MdaSndVolmStepReqV : 24|1@0+ (1,0) [0|1] "/"  Vector__XXX
 SG_ MdaSndVolmStepReq : 30|6@0+ (1,0) [0|63] "/"  Vector__XXX
 SG_ LVDSNavReady : 31|1@0+ (1,0) [0|1] ""  Vector__XXX
 SG_ NaviSndVolmStepReqV : 32|1@0+ (1,0) [0|1] "/"  Vector__XXX
 SG_ NaviSndVolmStepReq : 38|6@0+ (1,0) [0|63] "/"  Vector__XXX
 SG_ LVDSPhReady : 39|1@0+ (1,0) [0|1] ""  Vector__XXX
 SG_ PhnCallSndVolmStepReqV : 40|1@0+ (1,0) [0|1] "/"  Vector__XXX
 SG_ PhnCallSndVolmStepReq : 46|6@0+ (1,0) [0|63] "/"  Vector__XXX
 SG_ VcItatnSndVolmStepReqV : 48|1@0+ (1,0) [0|1] "/"  Vector__XXX
 SG_ VcItatnSndVolmStepReq : 54|6@0+ (1,0) [0|63] "/"  Vector__XXX
 SG_ FdrSetngReqV : 56|1@0+ (1,0) [0|1] "/"  Vector__XXX
 SG_ FdrSetngReq : 60|4@0+ (1,0) [0|15] "/"  Vector__XXX

BO_ 733 AMPReq2: 8 FICM_FD
 SG_ BalcSetngReqV : 0|1@0+ (1,0) [0|1] "/"  Vector__XXX
 SG_ BalcSetngReq : 4|4@0+ (1,0) [0|15] "/"  Vector__XXX
 SG_ AmbcSetngReqV : 8|1@0+ (1,0) [0|1] "/"  Vector__XXX
 SG_ AmbcSetngReq : 11|3@0+ (1,0) [0|7] "/"  Vector__XXX
 SG_ ThreeDimnSndFldSetngReqV : 16|1@0+ (1,0) [0|1] "/"  Vector__XXX
 SG_ ThreeDimnSndFldSetngReq : 19|3@0+ (1,0) [0|7] "/"  Vector__XXX
 SG_ SpdDpntAutocVolmReqV : 24|1@0+ (1,0) [0|1] "/"  Vector__XXX
 SG_ SpdDpntAutocVolmReq : 26|2@0+ (1,0) [0|3] "/"  Vector__XXX
 SG_ CustzEqlzrV : 32|1@0+ (1,0) [0|1] "/"  Vector__XXX
 SG_ CustzEqlzrPreSet : 35|3@0+ (1,0) [0|7] "/"  Vector__XXX
 SG_ ICMTurnOnRdyStsX : 40|1@0+ (1,0) [0|1] "/"  Vector__XXX
 SG_ VirtualSbwfrOnOffReq : 41|1@0+ (1,0) [0|1] "/"  Vector__XXX
 SG_ LdnsSetngSoftSw : 42|1@0+ (1,0) [0|1] "/"  Vector__XXX
 SG_ TelphoComLoctn : 45|3@0+ (1,0) [0|7] "/"  Vector__XXX
 SG_ ChmOutSpk : 55|8@0+ (1,0) [0|255] "/"  Vector__XXX
 SG_ ANCFunSwV : 56|1@0+ (1,0) [0|1] "/"  Vector__XXX
 SG_ ANCFunSw : 60|4@0+ (1,0) [0|15] "/"  Vector__XXX
 SG_ VcItatnSndLoctn : 63|3@0+ (1,0) [0|7] "/"  Vector__XXX
 SG_ FICM_MusicPlaybackSts : 47|2@0+ (1,0) [0|3] ""  Vector__XXX
 SG_ FICM_MdSts : 7|3@0+ (1,0) [0|7] ""  Vector__XXX

BO_ 734 AMPSoundDebugFbk: 8 FICM_FD
 SG_ AMPSoundFdbk : 7|64@0+ (1,0) [0|18446744073709551615] "/"  Vector__XXX

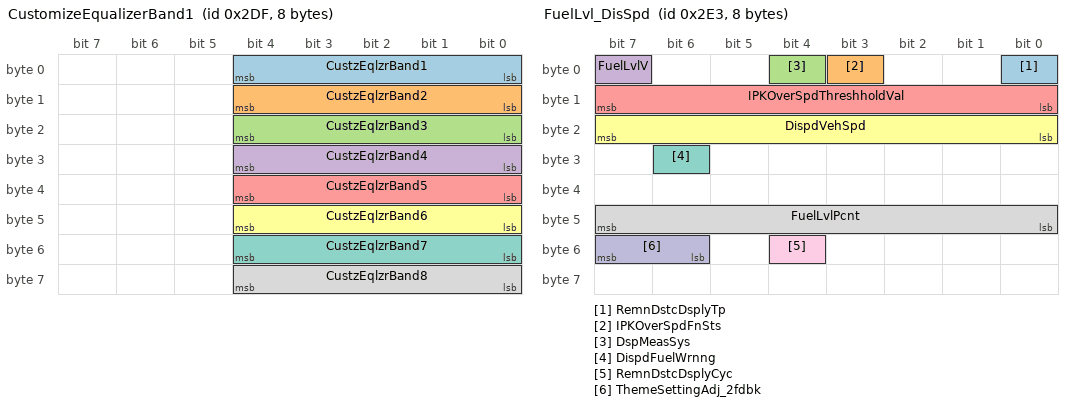
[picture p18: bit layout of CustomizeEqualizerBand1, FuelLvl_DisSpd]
BO_ 735 CustomizeEqualizerBand1: 8 FICM_FD
 SG_ CustzEqlzrBand1 : 4|5@0+ (1,0) [0|31] "/"  Vector__XXX
 SG_ CustzEqlzrBand2 : 12|5@0+ (1,0) [0|31] "/"  Vector__XXX
 SG_ CustzEqlzrBand3 : 20|5@0+ (1,0) [0|31] "/"  Vector__XXX
 SG_ CustzEqlzrBand4 : 28|5@0+ (1,0) [0|31] "/"  Vector__XXX
 SG_ CustzEqlzrBand5 : 36|5@0+ (1,0) [0|31] "/"  Vector__XXX
 SG_ CustzEqlzrBand6 : 44|5@0+ (1,0) [0|31] "/"  Vector__XXX
 SG_ CustzEqlzrBand7 : 52|5@0+ (1,0) [0|31] "/"  Vector__XXX
 SG_ CustzEqlzrBand8 : 60|5@0+ (1,0) [0|31] "/"  Vector__XXX

BO_ 737 Odometer: 8 Vector__XXX
 SG_ VehOdo : 7|24@0+ (1,0) [0|16777215] "km"  FICM_FD
 SG_ VehOdoV : 48|1@0+ (1,0) [0|1] ""  FICM_FD

BO_ 739 FuelLvl_DisSpd: 8 Vector__XXX
 SG_ RemnDstcDsplyTp : 0|1@0+ (1,0) [0|1] ""  FICM_FD
 SG_ IPKOverSpdFnSts : 3|1@0+ (1,0) [0|1] "NA"  FICM_FD
 SG_ DspMeasSys : 4|1@0+ (1,0) [0|1] ""  FICM_FD
 SG_ FuelLvlV : 7|1@0+ (1,0) [0|1] ""  FICM_FD
 SG_ IPKOverSpdThreshholdVal : 15|8@0+ (1,0) [0|255] ""  FICM_FD
 SG_ DispdVehSpd : 23|8@0+ (1,0) [0|255] "Km/h"  FICM_FD
 SG_ DispdFuelWrnng : 30|1@0+ (1,0) [0|1] ""  FICM_FD
 SG_ FuelLvlPcnt : 47|8@0+ (0.4,0) [0|100] "%"  FICM_FD
 SG_ RemnDstcDsplyCyc : 52|1@0+ (1,0) [0|1] ""  FICM_FD
 SG_ ThemeSettingAdj_2fdbk : 55|2@0+ (1,0) [0|3] ""  FICM_FD

CM_ SG_ 300 BMSPackSOCDspV "BMS输出电池包显示SOC有效位";
CM_ SG_ 300 BMSPackVolV "BMS输出电池包总压值有效位";
CM_ SG_ 300 BMSPackCrntV "BMS输出电池包电流值有效位";
CM_ SG_ 300 BMSPackCrnt "BMS输出电池包电流值
E:N*0.05-1000 A";
CM_ SG_ 300 BMSPackVol "BMS输出电池包总压值
E:N*0.25 V";
CM_ SG_ 300 BMSPackSOCDsp "BMS输出电池包显示SOC
E:N*0.1 %";

CM_ SG_ 308 PropSysA "It is an indicator of the vehicle's propulsion capability, either through electric motor, IC engine or both.";
CM_ SG_ 308 EnStsV "Validity of the Engine Status.";
CM_ SG_ 308 EnSts "It represents the actual status of the engine.";
CM_ SG_ 308 ClBTopSw "Clutch Top Switch";
CM_ SG_ 308 ClPdlActuPosV "Reserved fot the MT.";
CM_ SG_ 308 ClPdlActuPos "Reserved fot the MT.Clutch pedal position.";

CM_ SG_ 322 BMSBscSta "BMS工作状态";
CM_ SG_ 322 BMSOnbdChrgrPlugOn "BMS反馈慢充插枪信号";
CM_ SG_ 322 BMSOfbdChrgrPlugOn "快充插枪信号";

CM_ SG_ 336 FCM_AEBMainSwFdbck "FCM_AEB开关反馈";

CM_ SG_ 342 PASoundInfo "语音提示信息
Parking Assist Sound Information";
CM_ SG_ 342 PASoundCtrlSetReqFdbck "开启/关闭“语音控制泊车”个性化设置请求反馈
Parking Assist Sound Control Set Request Feedback";
CM_ SG_ 342 APAFctryDeftSetFnsh "恢复出厂设置反馈
APA Factory Default Setting Finished";
CM_ SG_ 342 APALanguageFdbck "泊车界面语言设置反馈
APALanguageFeedback";

CM_ SG_ 343 RPASts "RPA状态";
CM_ SG_ 343 APASts "APA状态";

CM_ SG_ 347 LDWAccuracyFdbck "LDW报警灵敏度设置请求反馈";
CM_ SG_ 347 LDWReminderFdbck "LDW报警方式个性化设置请求反馈";
CM_ SG_ 347 LKA_LDW_ELKMainSwFdbck "LKA_LDW_ELK开关反馈";

CM_ SG_ 381 CampEPTRdy "Camp Electric Powertrain Ready";
CM_ SG_ 381 HVReady "IMCU HV ready信号";
CM_ SG_ 381 CampEPTRunAbotd "Camp Electric Powertrain Run Aborted";
CM_ SG_ 381 CampEPTCrkAbotd "Camp Electric Powertrain Crank Aborted";
CM_ SG_ 381 CampEPTRunAbotdRsn "Camp Electric Powertrain Run Aborted Reason";
CM_ SG_ 381 CampEPTCrkAbotdRsn "Camp Electric Powertrain Crank Aborted Reason";

CM_ SG_ 393 VehSpdV "Vehicle Speed output status";
CM_ SG_ 393 VehSpd "Vehicle Speed output";
CM_ SG_ 393 VehSpd_RllCnt "Message counter";

CM_ SG_ 402 StrgWhlAng "Steering Wheel Angle";
CM_ SG_ 402 StrgWhlAngSnsrFlt "Steering Wheel Angle Sensor Fault";
CM_ SG_ 402 StrgWhlAngSnsrInid "Steering Wheel Angle Sensor Initialized";
CM_ SG_ 402 StrgWhlAngV "Steering Wheel Angle Validity";
CM_ SG_ 402 StrgWhlAngGrd "Steering Wheel Angle Gradient";
CM_ SG_ 402 StrgWhlAngSnsrCalSts "Steering Wheel Angle Sensor Calibration Status";

CM_ SG_ 403 EPSCurrMod "该报文要根据最终确定的驾驶手感种类来锁定信号数量。";
CM_ SG_ 403 EPSFctryDfltSttngFnshd "手力模式恢复出厂设置反馈";

CM_ SG_ 408 EPBSysDispMsgReq "Electric Park Brake System Display Message Request
M0 Off
M1 Press Brake Pedal to Release Park Brake
M2 Service Park Brake
M3 Park Brake Set
M4 Park Brake Released
M5 FastenSeatbelt&ClosedDriveDoor";
CM_ SG_ 408 EPBAppcnSts "Electric Park Brake Application Status";
CM_ SG_ 408 EPBIgnoffAutoAppFnFdbck1 "EPB Autoapply Status When Ignition Off";

CM_ SG_ 441 HUDEnbSetResp "HUD工作状态";
CM_ SG_ 441 HUDDmAdjResp "HUD亮度值";
CM_ SG_ 441 HUDPctAlttdAdjResp "HUD高度值";
CM_ SG_ 441 HUDPctInclntAdjResp "HUD倾斜度值";

CM_ SG_ 444 PgTrnUp "翻页信号（上）";
CM_ SG_ 444 PgTrnDw "翻页信号（下）";
CM_ SG_ 444 PgTrnRt "翻页信号（右）";
CM_ SG_ 444 PgTrnLf "翻页信号（左）";
CM_ SG_ 444 PgTrnOK "翻页信号（OK）";
CM_ SG_ 444 IPKTabReq "仪表界面显示请求";

CM_ SG_ 445 SysPwrMd "电源模式";
CM_ SG_ 445 SysPwrMdV "电源模式有效性";
CM_ SG_ 445 TransMd "运输模式状态";
CM_ SG_ 445 RVSReq "远程启动请求";

CM_ SG_ 447 AVHSysDispMsgReq "Auto Hold System Display Message Regard, to IPK";
CM_ SG_ 447 ESCFnOffFdbck "ESCFnOffFdbck";
CM_ SG_ 447 AVHFnFdbck "AVHFnFdbck";
CM_ SG_ 447 HDCFnFdbck "HDCFnFdbck";
CM_ SG_ 447 DrvngMdDisp "This signal indicates send the act of the driver mode request signal of ATM.";
CM_ SG_ 447 EPBIgnoffAutoAppFnFdbck "EPB Autoapply Status When Ignition Off";
CM_ SG_ 447 ESC_HMI_RllCnt "Message counter";

CM_ SG_ 457 DMSSwFdbck "DMS功能总开关状态显示";
CM_ SG_ 457 FatigueMoniSwFdbck "疲劳监测设置开关开/闭状态反馈";
CM_ SG_ 457 DistractionMoniSwFdbck "分心监测设置开关开/闭状态反馈";

CM_ SG_ 479 BSDMainSwFdbck "BSD、LCA、RCTA、DOW共用开关";

CM_ SG_ 485 UltraRdrSnsrSts_1 "超声波雷达探头故障状态
Ultrasonic Radar Sensor Status_2";
CM_ SG_ 485 UltraRdrSnsrObjWrnngZn_1 "目标障碍物报警区域
Ultrasonic Radar Sensor Object Warning Zone_2";
CM_ SG_ 485 UltraRdrSnsrSts_6 "超声波雷达探头故障状态（预留）
Ultrasonic Radar Sensor Status_3";
CM_ SG_ 485 UltraRdrSnsrObjWrnngZn_6 "目标障碍物报警区域（预留）
Ultrasonic Radar Sensor Object Warning Zone_3";
CM_ SG_ 485 UltraRdrSnsrSts_7 "超声波雷达探头故障状态（预留）
Ultrasonic Radar Sensor Status_4";
CM_ SG_ 485 UltraRdrSnsrObjWrnngZn_7 "目标障碍物报警区域（预留）
Ultrasonic Radar Sensor Object Warning Zone_4";
CM_ SG_ 485 UltraRdrSnsrSts_12 "超声波雷达探头故障状态
Ultrasonic Radar Sensor Status_5";
CM_ SG_ 485 UltraRdrSnsrObjWrnngZn_12 "目标障碍物报警区域
Ultrasonic Radar Sensor Object Warning Zone_5";
CM_ SG_ 485 UltraRdrSnsrDist_1 "目标障碍物距离
Ultrasonic Radar Sensor Distance_2";
CM_ SG_ 485 UltraRdrSnsrDist_6 "目标障碍物距离（预留）
Ultrasonic Radar Sensor Distance_3";
CM_ SG_ 485 UltraRdrSnsrDist_7 "目标障碍物距离（预留）
Ultrasonic Radar Sensor Distance_4";
CM_ SG_ 485 UltraRdrSnsrDist_12 "目标障碍物距离
Ultrasonic Radar Sensor Distance_5";

CM_ SG_ 486 UltraRdrSnsrSts_8 "超声波雷达探头故障状态
Ultrasonic Radar Sensor Status_8";
CM_ SG_ 486 UltraRdrSnsrObjWrnngZn_8 "目标障碍物报警区域
Ultrasonic Radar Sensor Object Warning Zone_8";
CM_ SG_ 486 UltraRdrSnsrSts_9 "超声波雷达探头故障状态
Ultrasonic Radar Sensor Status_9";
CM_ SG_ 486 UltraRdrSnsrObjWrnngZn_9 "目标障碍物报警区域
Ultrasonic Radar Sensor Object Warning Zone_9";
CM_ SG_ 486 UltraRdrSnsrSts_10 "超声波雷达探头故障状态
Ultrasonic Radar Sensor Status_10";
CM_ SG_ 486 UltraRdrSnsrObjWrnngZn_10 "目标障碍物报警区域
Ultrasonic Radar Sensor Object Warning Zone_10";
CM_ SG_ 486 UltraRdrSnsrSts_11 "超声波雷达探头故障状态
Ultrasonic Radar Sensor Status_11";
CM_ SG_ 486 UltraRdrSnsrObjWrnngZn_11 "目标障碍物报警区域
Ultrasonic Radar Sensor Object Warning Zone_11";
CM_ SG_ 486 UltraRdrSnsrDist_8 "目标障碍物距离
Ultrasonic Radar Sensor Distance_8";
CM_ SG_ 486 UltraRdrSnsrDist_9 "目标障碍物距离
Ultrasonic Radar Sensor Distance_9";
CM_ SG_ 486 UltraRdrSnsrDist_10 "目标障碍物距离
Ultrasonic Radar Sensor Distance_10";
CM_ SG_ 486 UltraRdrSnsrDist_11 "目标障碍物距离
Ultrasonic Radar Sensor Distance_11";
CM_ SG_ 486 PDCBeepOffReqFdbck_R "开启/关闭“雷达声音报警”个性化设置请求反馈
PDC Beep Off Request Feedback";

CM_ SG_ 487 UltraRdrSnsrSts_2 "超声波雷达探头故障状态
Ultrasonic Radar Sensor Status_2";
CM_ SG_ 487 UltraRdrSnsrObjWrnngZn_2 "目标障碍物报警区域
Ultrasonic Radar Sensor Object Warning Zone_2";
CM_ SG_ 487 UltraRdrSnsrSts_3 "超声波雷达探头故障状态（预留）
Ultrasonic Radar Sensor Status_3";
CM_ SG_ 487 UltraRdrSnsrObjWrnngZn_3 "目标障碍物报警区域（预留）
Ultrasonic Radar Sensor Object Warning Zone_3";
CM_ SG_ 487 UltraRdrSnsrSts_4 "超声波雷达探头故障状态（预留）
Ultrasonic Radar Sensor Status_4";
CM_ SG_ 487 UltraRdrSnsrObjWrnngZn_4 "目标障碍物报警区域（预留）
Ultrasonic Radar Sensor Object Warning Zone_4";
CM_ SG_ 487 UltraRdrSnsrSts_5 "超声波雷达探头故障状态
Ultrasonic Radar Sensor Status_5";
CM_ SG_ 487 UltraRdrSnsrObjWrnngZn_5 "目标障碍物报警区域
Ultrasonic Radar Sensor Object Warning Zone_5";
CM_ SG_ 487 UltraRdrSnsrDist_2 "目标障碍物距离
Ultrasonic Radar Sensor Distance_2";
CM_ SG_ 487 UltraRdrSnsrDist_3 "目标障碍物距离（预留）
Ultrasonic Radar Sensor Distance_3";
CM_ SG_ 487 UltraRdrSnsrDist_4 "目标障碍物距离（预留）
Ultrasonic Radar Sensor Distance_4";
CM_ SG_ 487 UltraRdrSnsrDist_5 "目标障碍物距离
Ultrasonic Radar Sensor Distance_5";
CM_ SG_ 487 PDCBeepOffReqFdbck_F "开启/关闭“雷达声音报警”个性化设置请求反馈
PDC Beep Off Request Feedback";
CM_ SG_ 487 PDCMainSWFdbck "PDC主雷达开关请求反馈";

CM_ SG_ 490 AVMSts "AVM工作状态
AVM Status";
CM_ SG_ 490 VideoReq "AVM请求显示/隐藏全景界面
Video Request";
CM_ SG_ 490 VideoReqV "AVM请求显示/隐藏全景界面有效性
Video Request Validity";
CM_ SG_ 490 SnsSldDrActnTypSetReqFdbck "摄像头识别动作类型设置请求反馈（快发周期40ms）";
CM_ SG_ 490 SentryMdSetReqFdbck "（哨兵模式-自动触发）功能开启/关闭状态反馈
Sentry Mode Set Request Feedback";
CM_ SG_ 490 RmtAVMReqFdbck "AVM反馈是否激活哨兵模式-手动触发
Remote AVM Request Feedback";
CM_ SG_ 490 SentryMdSensitivityFdbck "APA对哨兵模式灵敏度设置的反馈";
CM_ SG_ 490 AVMFctryDeftSetFnsh "恢复出厂设置反馈
FactoryDefaultSettingFinished";

CM_ SG_ 493 SysBkupPwrMd "电源模式";
CM_ SG_ 493 SysBkupPwrMdV "电源模式有效性";
CM_ SG_ 493 SysBkupPwrMdEnbl "电源模式有效性";

CM_ SG_ 511 HMIPhCallReq "接挂电话请求（长/短按）";
CM_ SG_ 511 HMIMtReq "静音功能请求";
CM_ SG_ 511 HMIVolUpAdjReq "音量增加";
CM_ SG_ 511 HMIVolDownAdjReq "音量减少";
CM_ SG_ 511 HMIMscNextAdjReq "音乐下一首";
CM_ SG_ 511 HMIMscPreAdjReq "音乐上一首";
CM_ SG_ 511 HMIVoiceReq "语音识别开关请求";
CM_ SG_ 511 HMITlmtcsReq "车联网功能开启/关闭";
CM_ SG_ 511 HMISRCReq "娱乐音源切换";

CM_ SG_ 557 BMSChrgrPlugCnctnIO "插枪点灯信号";
CM_ SG_ 557 ChrgngRmnngTimeV "充电剩余时间有效位";
CM_ SG_ 557 BMSAvlblEnrgV "电池包当前可用能量有效位";
CM_ SG_ 557 ChrgngRmnngTime "充电剩余时间";
CM_ SG_ 557 CampChrgngRmnngTimeExt "驻车补电剩余时间";
CM_ SG_ 557 BMSAvlblEnrg "电池包当前可用能量";
CM_ SG_ 557 CampChrgngRmnngTimeExtV "驻车补电剩余时间有效性";
CM_ SG_ 557 ChrgngRmnngTimeExtV "充电剩余时间有效性";
CM_ SG_ 557 ChrgngRmnngTimeExt "充电剩余时间";

CM_ SG_ 626 DpfWrnngInf "DSL使用，DPF Warning Information";
CM_ SG_ 626 RGNinactivereason "DSL使用，Regeneration Inactive Reason";
CM_ SG_ 626 RGNPcnt "DSL使用，Regeneration percent";

CM_ SG_ 627 BatVolV "Batttery Voltage Validty";
CM_ SG_ 627 BatVol "Battery voltage information is used by ECM.";
CM_ SG_ 627 FuelModeFdbk "纯燃料模式反馈信号";
CM_ SG_ 627 EnStrtactFdbk_V2L "到达放电截止电量后请求起发动机反馈信号";

CM_ SG_ 632 Sootmass_Reset "DSL使用，DPF重置成功后颗粒值";
CM_ SG_ 632 Sootmass_max "DSL使用，允许服务站再生触发最大颗粒值";
CM_ SG_ 632 Sootmass_RGN "DSL使用，触发行车再生颗粒值";
CM_ SG_ 632 Sootmass "DSL使用，大屏辅助提示信息模块输入信号";

CM_ SG_ 646 FICMAVMSts "360工作状态";
CM_ SG_ 646 AVMTouchEvtTyp "用户操作类型（AVM/APA界面）";

CM_ SG_ 677 HVACFrontDefrostStatus "前除霜状态";
CM_ SG_ 677 HVACFrontACMaxStatus "前空调反馈ACMax的开关状态";

CM_ SG_ 679 HVACRearAirVolume2 "后暖风鼓风机风量";
CM_ SG_ 679 HVACOnRequestIndication_R "后A/C指示灯状态";

CM_ SG_ 727 AllMuteFdbk "全车静音反馈
All_Mute_Feedback";
CM_ SG_ 727 MdaMuteFdbk "媒体静音反馈
Media_Mute_Feedback";
CM_ SG_ 727 PhnMuteFdbk "电话静音反馈
Phone_Mute_Feedback";
CM_ SG_ 727 NaviMuteFdbk "导航静音反馈
Navi_Mute_Feedback";
CM_ SG_ 727 VcMuteFdbk "语音静音反馈
Voice_Mute_Feedback";
CM_ SG_ 727 NotiMuteFdbk "通知静音反馈
Notification_Mute_Feedback";
CM_ SG_ 727 ChmMuteFdbk "车辆提示音静音反馈
Chimes_Mute_Feedback";
CM_ SG_ 727 ChmSndVolmStepFdbk "Chime声音音量反馈
Chime_Sound_Volume_Step_Feedback";
CM_ SG_ 727 NotiSndVolmStepFdbk "通知声音音量反馈
Notification_Sound_Volume_Step_Feedback";
CM_ SG_ 727 NaviSndVolmStepFdbk "导航声音音量反馈
Navigation_Sound_Volume_Step_Feedback";
CM_ SG_ 727 MdaSndVolmStepFdbk "媒体声音音量反馈
Media_Sound_Volume_Step_Feedback";
CM_ SG_ 727 PhnCallSndVolmStepFdbk "电话声音音量反馈
Phone_Call_Sound_Volume_Step_Feedback";
CM_ SG_ 727 VcItatnSndVolmStepFdbk "语音交互声音音量反馈
Voice_Interaction_Sound_Volume_Step_Feedback";
CM_ SG_ 727 FdrSetngFdbk "Fader设置反馈
Fader_Setting_Feedbackk
0是偏向前";

CM_ SG_ 728 BalcSetngFdbk "Balance设置反馈
Balance_Setting_Feedback
0是偏向左";
CM_ SG_ 728 AmbcSetngFdbk "环境音效设置反馈
Ambiance_Setting_Feedback";
CM_ SG_ 728 ThreeDimnSndFldFdbk "3D声场反馈
Three_Dimensions_Sound_Field_Feedback";
CM_ SG_ 728 SpdDpntAutocVolmFdbk "速度音量补偿反馈
Speed_Dependant_Automatic_Volume_Feedback";
CM_ SG_ 728 AMP_Temp_STS "功放温度状态
The_Value_Of_AMP_Temperature_Status";
CM_ SG_ 728 CustzEqlzrPreSetFdbk "自定义均衡器预设反馈
Customize_Equalizer_Pre_Set_Feedback";
CM_ SG_ 728 ChmOutSpkFdbk "车辆提示音2声道映射至4个AMP通道的ChannelMask方式。每一位代表输出的通道是否有效，1为有效，0为无效
Chime_Output_Speaker_Feedback
bit0: chime_FL => FL
bit1: chime_FL => FR
bit2: chime_FL => RL
bit3: chime_FL => RR
bit4: chime_FR => FL
bit5: chime_FR => FR
bit6: chime_FR => RL
bit7: chime_FR => RR";
CM_ SG_ 728 AMPTurnOnRdyStsFdbk "功放打开准备状态反馈
Amplifier_Turn_On_Ready_Status_Feedback";
CM_ SG_ 728 AMPPwrRdySts "功放电源状态反馈
Amplifier_Power_Ready_Status_Feedback";
CM_ SG_ 728 VirtualSbwfrOnOffReqFdbk "虚拟低音炮打开关闭反馈
Virtual_Subwoofer_On_Off_Request_Feedback";
CM_ SG_ 728 LdnsSetngFdbk "响度补偿设置反馈
Loudness_Setting_Feedback";
CM_ SG_ 728 ANCFunSwFdbk "ANC功能开关反馈
ANC_function_Switchh_Feedback";
CM_ SG_ 728 AMP_DTC_INFO "功放输出通道信息
Amplifier_Output_Channel_DTC_Information
Notes: Below is example for this signal,only one reference,need update after system define.
bit0:CH1
bit1:CH2 
bit2:CH3 
bit3:CH4
bit4:CH5
bit5:CH6
bit6:CH7";
CM_ SG_ 728 ANCWorkInfoFdbk "ANC工作信息反馈
ANC_Working_Information_feedback";

CM_ SG_ 729 AMPVersionInfo "软件版本信息
Software_Version_Information
Byte_H(Byte0): Major Version
Byte_L(Byte1): Minor Version";
CM_ SG_ 729 ANCFWVersion "ANC软件版本信息
ANC_Firmware_Version_Information
Byte_H(Byte0): Major Version
Byte_L(Byte1): Minor Version";
CM_ SG_ 729 RngSndVolmStepFdbk "电话铃声声音音量反馈
Ring_Sound_Volume_Step_Feedback";

CM_ SG_ 730 AMPSoundDB "添加一个CAN ID专门用于 DSP 音效内部调试";

CM_ SG_ 731 CustzEqlzrBand1Dsp "自定义均衡器波段1显示
Customize_Equalizer_Band_1_Display";
CM_ SG_ 731 CustzEqlzrBand2Dsp "自定义均衡器波段2显示
Customize_Equalizer_Band_2_Display";
CM_ SG_ 731 CustzEqlzrBand3Dsp "自定义均衡器波段3显示
Customize_Equalizer_Band_3_Display";
CM_ SG_ 731 CustzEqlzrBand4Dsp "自定义均衡器波段4显示
Customize_Equalizer_Band_4_Display";
CM_ SG_ 731 CustzEqlzrBand5Dsp "自定义均衡器波段5显示
Customize_Equalizer_Band_5_Display";
CM_ SG_ 731 CustzEqlzrBand6Dsp "自定义均衡器波段6显示
Customize_Equalizer_Band_6_Display";
CM_ SG_ 731 CustzEqlzrBand7Dsp "自定义均衡器波段7显示
Customize_Equalizer_Band_7_Display";
CM_ SG_ 731 CustzEqlzrBand8Dsp "自定义均衡器波段8显示
Customize_Equalizer_Band_8_Display";

CM_ SG_ 732 AllMuteReq "全车静音
All_Mute_Request";
CM_ SG_ 732 MdaMuteReq "媒体静音
Media_Mute_Request";
CM_ SG_ 732 PhnMuteReq "电话静音
Phone_Mute_Request";
CM_ SG_ 732 NaviMuteReq "导航静音
Navi_Mute_Request";
CM_ SG_ 732 VcMuteReq "语音播报静音
Voice_Mute_Request";
CM_ SG_ 732 NotiMuteReq "通知播报静音
Notification_Mute_Request";
CM_ SG_ 732 ChmMuteReq "车辆提示音静音
Chimes_Mute_Request";
CM_ SG_ 732 ChmSndVolmStepReqV "Chime音量步长请求有效性
Chime_Sound_Volume_Step_Request_Validity";
CM_ SG_ 732 ChmSndVolmStepReq "Chime音量步长请求
Chime_Sound_Volume_Step_Request";
CM_ SG_ 732 FICMAvlblSts "FICM可用状态";
CM_ SG_ 732 NotiSndVolmStepReqV "通知音量步长请求有效性
Notification_Sound_Volume_Step_Request_Validity";
CM_ SG_ 732 NotiSndVolmStepReq "通知音量步长请求
Notification_Sound_Volume_Step_Request";
CM_ SG_ 732 LVDSMdaReady "主机多媒体状态";
CM_ SG_ 732 MdaSndVolmStepReqV "媒体音量步长请求有效性
Media_Sound_Volume_Step_Request_Validity";
CM_ SG_ 732 MdaSndVolmStepReq "媒体音量步长请求
Media_Sound_Volume_Step_Request";
CM_ SG_ 732 LVDSNavReady "主机导航状态";
CM_ SG_ 732 NaviSndVolmStepReqV "导航音量步长请求有效性
Navigation_Sound_Volume_Step_Request_Validity";
CM_ SG_ 732 NaviSndVolmStepReq "导航音量步长请求
Navigation_Sound_Volume_Step_Request";
CM_ SG_ 732 LVDSPhReady "主机蓝牙电话状态";
CM_ SG_ 732 PhnCallSndVolmStepReqV "电话音量步长请求有效性
Phone_Call_Sound_Volume_Step_Request_Validity";
CM_ SG_ 732 PhnCallSndVolmStepReq "电话音量步长请求
Phone_Call_Sound_Volume_Step_Request";
CM_ SG_ 732 VcItatnSndVolmStepReqV "语音播报音量步长请求有效性
Voice_Interaction_Sound_Volume_Step_Request_Validity";
CM_ SG_ 732 VcItatnSndVolmStepReq "语音播报音量步长请求
Voice_Interaction_Sound_Volume_Step_Request";
CM_ SG_ 732 FdrSetngReqV "Fader设置请求有效性
Fader_Setting_Request_Validity";
CM_ SG_ 732 FdrSetngReq "Fader设置请求
Fader_Setting_Request
0是偏向前";

CM_ SG_ 733 BalcSetngReqV "Balance设置请求有效性
Balance_Setting_Request_Validity";
CM_ SG_ 733 BalcSetngReq "Balance设置请求
Balance_Setting_Request
0是偏向左";
CM_ SG_ 733 AmbcSetngReqV "环境音效设置请求有效性
Ambiance_Setting_Request_Validity";
CM_ SG_ 733 AmbcSetngReq "环境音效设置请求
Ambiance_Setting_Request";
CM_ SG_ 733 ThreeDimnSndFldSetngReqV "3D声场请求有效性
Three_Dimension_Sound_Field_Setting_Request_Validity";
CM_ SG_ 733 ThreeDimnSndFldSetngReq "3D声场设置请求
Three_Dimension_Sound_Field_Setting_Request";
CM_ SG_ 733 SpdDpntAutocVolmReqV "速度音量补偿请求有效性
Speed_Dependant_Automatic_Volume_Request_Validity";
CM_ SG_ 733 SpdDpntAutocVolmReq "速度音量补偿请求
Speed_Dependant_Automatic_Volume_Request";
CM_ SG_ 733 CustzEqlzrV "自定义均衡器有效性
Customize_Equalizer_Validity";
CM_ SG_ 733 CustzEqlzrPreSet "自定义均衡器预设
Customize_Equalizer_Pre_Set";
CM_ SG_ 733 ICMTurnOnRdyStsX "娱乐系统模块打开准备状态
Intelligent_Cockpit_Module_Turn_On_Ready_StatusX";
CM_ SG_ 733 VirtualSbwfrOnOffReq "虚拟低音炮打开关闭请求
Virtual_Subwoofer_On_Off_Request";
CM_ SG_ 733 LdnsSetngSoftSw "响度补偿设置软开关
Loudness_Setting_Soft_Swtich";
CM_ SG_ 733 TelphoComLoctn "电话交流位置
Telephone_Communication_Location";
CM_ SG_ 733 ChmOutSpk "车辆提示音2声道映射至4个AMP通道的ChannelMask方式。每一位代表输出的通道是否有效，1为有效，0为无效
Chime_output_Speaker
bit0: chime_FL => FL
bit1: chime_FL => FR
bit2: chime_FL => RL
bit3: chime_FL => RR
bit4: chime_FR => FL
bit5: chime_FR => FR
bit6: chime_FR => RL
bit7: chime_FR => RR";
CM_ SG_ 733 ANCFunSwV "ANC功能开关有效性
ANC_function_Switch_set_Validity";
CM_ SG_ 733 ANCFunSw "ANC功能开关设定
ANC_function_Switch_set";
CM_ SG_ 733 VcItatnSndLoctn "语音交互发声位置
Voice_Interaction_Sound_Location";
CM_ SG_ 733 FICM_MusicPlaybackSts "Music playback status in FICM";
CM_ SG_ 733 FICM_MdSts "Interaction content to IPK";

CM_ SG_ 734 AMPSoundFdbk "添加一个CAN ID专门用于 DSP 音效内部调试数据反馈使用";

CM_ SG_ 735 CustzEqlzrBand1 "自定义均衡器波段1
Customize_Equalizer_Band_1
0-12dB，";
CM_ SG_ 735 CustzEqlzrBand2 "自定义均衡器波段2
Customize_Equalizer_Band_2
0-12dB，";
CM_ SG_ 735 CustzEqlzrBand3 "自定义均衡器波段3
Customize_Equalizer_Band_3
0-12dB，";
CM_ SG_ 735 CustzEqlzrBand4 "自定义均衡器波段4
Customize_Equalizer_Band_4
0-12dB，";
CM_ SG_ 735 CustzEqlzrBand5 "自定义均衡器波段5
Customize_Equalizer_Band_5
0-12dB，";
CM_ SG_ 735 CustzEqlzrBand6 "自定义均衡器波段6
Customize_Equalizer_Band_6
0-12dB，";
CM_ SG_ 735 CustzEqlzrBand7 "自定义均衡器波段7
Customize_Equalizer_Band_7
0-12dB，";
CM_ SG_ 735 CustzEqlzrBand8 "自定义均衡器波段8
Customize_Equalizer_Band_8
0-12dB，";

CM_ SG_ 737 VehOdo "Vehicle Odometer";
CM_ SG_ 737 VehOdoV "Vehicle Odometer Validity";

CM_ SG_ 739 FuelLvlV "Fuel Level and Fuel Level Percent Validity";
CM_ SG_ 739 IPKOverSpdThreshholdVal "phys range:0-255";
CM_ SG_ 739 DispdFuelWrnng "IPKDisplayedFuelWarning";
CM_ SG_ 739 FuelLvlPcnt "Fuel Level Percent
percent of cyrrent tank level divide 'Fuel Total Capacity'.";
BA_DEF_  "DBName" STRING ;
BA_DEF_  "Baudrate" INT 0 2000000;
BA_DEF_  "NmMessageCount" INT 0 255;
BA_DEF_  "NmBaseAddress" HEX 0 2047;
BA_DEF_  "Manufacturer" STRING ;
BA_DEF_ SG_  "GenSigTimeoutValue" INT 0 65535;
BA_DEF_  "NmAsrRepeatMessageTime" INT 0 65535;
BA_DEF_  "NmAsrTimeoutTime" INT 1 65535;
BA_DEF_  "NmAsrWaitBusSleepTime" INT 0 65535;
BA_DEF_  "NmAsrMessageCount" INT 1 256;
BA_DEF_  "NmAsrCanMsgCycleTime" INT 0 65535;
BA_DEF_  "NmAsrBaseAddress" HEX 0 2047;
BA_DEF_  "ILTxTimeout" INT 0 65535;
BA_DEF_  "NmType" STRING ;
BA_DEF_  "MultiplexExtEnabled" ENUM  "no","yes";
BA_DEF_ BU_  "NmAsrNode" ENUM  "no","yes";
BA_DEF_ BU_  "NmAsrCanMsgReducedTime" INT 0 65535;
BA_DEF_ BU_  "ILUsed" ENUM  "no","yes";
BA_DEF_ BU_  "NodeLayerModules" STRING ;
BA_DEF_ BU_  "NmAsrNodeIdentifier" HEX 0 4095;
BA_DEF_ BU_  "NmStationAddress" HEX 0 255;
BA_DEF_ BU_  "NmAsrCanMsgCycleOffset" INT 0 65535;
BA_DEF_ BU_  "NmNode" ENUM  "no","yes";
BA_DEF_ BO_  "DiagState" ENUM  "no","yes";
BA_DEF_ BO_  "GenMsgNrOfRepetition" INT 0 65535;
BA_DEF_ BO_  "GenMsgSendType" ENUM  "Cyclic","NotUsed","NotUsed","NotUsed","NotUsed","NotUsed","NotUsed","IfActive","NoMsgSendType","NotUsed";
BA_DEF_ SG_  "SignalLongName" STRING ;
BA_DEF_ BO_  "VFrameFormat" ENUM  "StandardCAN","ExtendedCAN","reserved","J1939PG","reserved","reserved","reserved","reserved","reserved","reserved","reserved","reserved","reserved","reserved","StandardCAN_FD","ExtendedCAN_FD";
BA_DEF_ BO_  "NmMessage" ENUM  "no","yes";
BA_DEF_ BO_  "GenMsgDelayTime" INT 0 65535;
BA_DEF_ BO_  "GenMsgILSupport" ENUM  "no","yes";
BA_DEF_ BO_  "GenMsgStartDelayTime" INT 0 65535;
BA_DEF_ BO_  "NmAsrMessage" ENUM  "no","yes";
BA_DEF_ BO_  "DiagRequest" ENUM  "no","yes";
BA_DEF_ BO_  "DiagResponse" ENUM  "no","yes";
BA_DEF_ BO_  "GenMsgCycleTimeFast" INT 0 65535;
BA_DEF_ BO_  "GenMsgCycleTime" INT 0 30000;
BA_DEF_ SG_  "GenSigStartValue" INT 0 65535;
BA_DEF_ SG_  "GenSigInactiveValue" HEX 0 65535;
BA_DEF_ SG_  "GenSigSendType" ENUM  "Cyclic","OnWrite","OnWriteWithRepetition","OnChange","OnChangeWithRepetition","IfActive","IfActiveWithRepetition","NoSigSendType","OnChangeAndIfActive","OnChangeAndIfActiveWithRepetition";
BA_DEF_  "BusType" STRING ;
BA_DEF_REL_ BU_SG_REL_  "GenSigTimeoutTime" INT 0 65535;
BA_DEF_DEF_  "DBName" "";
BA_DEF_DEF_  "Baudrate" 500000;
BA_DEF_DEF_  "NmMessageCount" 255;
BA_DEF_DEF_  "NmBaseAddress" 1024;
BA_DEF_DEF_  "Manufacturer" "Vector";
BA_DEF_DEF_  "GenSigTimeoutValue" 0;
BA_DEF_DEF_  "NmAsrRepeatMessageTime" 1500;
BA_DEF_DEF_  "NmAsrTimeoutTime" 2000;
BA_DEF_DEF_  "NmAsrWaitBusSleepTime" 2000;
BA_DEF_DEF_  "NmAsrMessageCount" 128;
BA_DEF_DEF_  "NmAsrCanMsgCycleTime" 500;
BA_DEF_DEF_  "NmAsrBaseAddress" 1024;
BA_DEF_DEF_  "ILTxTimeout" 0;
BA_DEF_DEF_  "NmType" "NmAsr";
BA_DEF_DEF_  "MultiplexExtEnabled" "yes";
BA_DEF_DEF_  "NmAsrNode" "no";
BA_DEF_DEF_  "NmAsrCanMsgReducedTime" 320;
BA_DEF_DEF_  "ILUsed" "no";
BA_DEF_DEF_  "NodeLayerModules" " ";
BA_DEF_DEF_  "NmAsrNodeIdentifier" 50;
BA_DEF_DEF_  "NmStationAddress" 0;
BA_DEF_DEF_  "NmAsrCanMsgCycleOffset" 0;
BA_DEF_DEF_  "NmNode" "no";
BA_DEF_DEF_  "DiagState" "no";
BA_DEF_DEF_  "GenMsgNrOfRepetition" 0;
BA_DEF_DEF_  "GenMsgSendType" "NoMsgSendType";
BA_DEF_DEF_  "SignalLongName" "";
BA_DEF_DEF_  "VFrameFormat" "StandardCAN";
BA_DEF_DEF_  "NmMessage" "no";
BA_DEF_DEF_  "GenMsgDelayTime" 0;
BA_DEF_DEF_  "GenMsgILSupport" "no";
BA_DEF_DEF_  "GenMsgStartDelayTime" 0;
BA_DEF_DEF_  "NmAsrMessage" "no";
BA_DEF_DEF_  "DiagRequest" "no";
BA_DEF_DEF_  "DiagResponse" "no";
BA_DEF_DEF_  "GenMsgCycleTimeFast" 0;
BA_DEF_DEF_  "GenMsgCycleTime" 0;
BA_DEF_DEF_  "GenSigStartValue" 0;
BA_DEF_DEF_  "GenSigInactiveValue" 0;
BA_DEF_DEF_  "GenSigSendType" "NoSigSendType";
BA_DEF_DEF_  "BusType" "";
BA_DEF_DEF_REL_ "GenSigTimeoutTime" 0;

BA_ "NmMessageCount" 0;
BA_ "BusType" "CAN FD";
BA_ "Baudrate" 2000000;
BA_ "DBName" "INF_FD";

BA_ "NmStationAddress" BU_ FICM_FD 65;
BA_ "NmAsrNodeIdentifier" BU_ FICM_FD 65;
BA_ "NodeLayerModules" BU_ FICM_FD "CANoeILNLVector.dll";
BA_ "ILUsed" BU_ FICM_FD 1;
BA_ "NmAsrCanMsgReducedTime" BU_ FICM_FD 0;
BA_ "NmAsrNode" BU_ FICM_FD 1;

BA_ "GenMsgSendType" BO_ 300 0;
BA_ "GenMsgStartDelayTime" BO_ 300 10;
BA_ "GenMsgCycleTime" BO_ 300 50;
BA_ "GenMsgILSupport" BO_ 300 1;
BA_ "VFrameFormat" BO_ 300 14;

BA_ "GenSigSendType" SG_ 300 BMSPackSOCDspV 0;
BA_ "SignalLongName" SG_ 300 BMSPackSOCDspV "Battery Management System Pack State Of Charge Display Validity";

BA_ "GenSigSendType" SG_ 300 BMSPackVolV 0;
BA_ "SignalLongName" SG_ 300 BMSPackVolV "Battery Management System Pack Voltage Validity";

BA_ "GenSigSendType" SG_ 300 BMSPackCrntV 0;
BA_ "SignalLongName" SG_ 300 BMSPackCrntV "Battery Management System Pack Current Validity";

BA_ "GenSigSendType" SG_ 300 BMSPackCrnt 0;
BA_ "SignalLongName" SG_ 300 BMSPackCrnt "Battery Management System Pack Current";
BA_ "GenSigTimeoutValue" SG_ 300 BMSPackCrnt 65535;
BA_ "GenSigStartValue" SG_ 300 BMSPackCrnt 65535;

BA_ "GenSigSendType" SG_ 300 BMSPackVol 0;
BA_ "SignalLongName" SG_ 300 BMSPackVol "Battery Management System Pack Voltage";
BA_ "GenSigTimeoutValue" SG_ 300 BMSPackVol 4095;
BA_ "GenSigStartValue" SG_ 300 BMSPackVol 4095;

BA_ "GenSigSendType" SG_ 300 BMSPackSOCDsp 0;
BA_ "SignalLongName" SG_ 300 BMSPackSOCDsp "Battery Management System Pack State Of Charge Display";
BA_ "GenSigTimeoutValue" SG_ 300 BMSPackSOCDsp 1023;
BA_ "GenSigStartValue" SG_ 300 BMSPackSOCDsp 1023;

BA_ "GenMsgSendType" BO_ 308 0;
BA_ "GenMsgStartDelayTime" BO_ 308 15;
BA_ "GenMsgCycleTime" BO_ 308 20;
BA_ "GenMsgILSupport" BO_ 308 1;
BA_ "VFrameFormat" BO_ 308 14;

BA_ "GenSigSendType" SG_ 308 PropSysA 0;
BA_ "SignalLongName" SG_ 308 PropSysA "Propulsion System Active";

BA_ "GenSigSendType" SG_ 308 EnStsV 0;
BA_ "SignalLongName" SG_ 308 EnStsV "Engine Status Validity";

BA_ "GenSigSendType" SG_ 308 EnSts 0;
BA_ "SignalLongName" SG_ 308 EnSts "Engine Status";

BA_ "GenSigSendType" SG_ 308 ClBTopSw 0;
BA_ "SignalLongName" SG_ 308 ClBTopSw "ClutchTopSwitch";

BA_ "GenSigSendType" SG_ 308 ClPdlActuPosV 0;
BA_ "SignalLongName" SG_ 308 ClPdlActuPosV "Clutch Pedal Position Validity";

BA_ "GenSigSendType" SG_ 308 ClPdlActuPos 0;
BA_ "SignalLongName" SG_ 308 ClPdlActuPos "Clutch Pedal Position";

BA_ "GenSigSendType" SG_ 308 ECM_134h_RllCnt 0;
BA_ "SignalLongName" SG_ 308 ECM_134h_RllCnt "ECM_134h_RllCnt";

BA_ "GenSigSendType" SG_ 308 ECM_134h_ChkSum 0;
BA_ "SignalLongName" SG_ 308 ECM_134h_ChkSum "ECM_134h_ChkSum";

BA_ "GenMsgSendType" BO_ 322 0;
BA_ "GenMsgStartDelayTime" BO_ 322 10;
BA_ "GenMsgCycleTime" BO_ 322 20;
BA_ "GenMsgILSupport" BO_ 322 1;
BA_ "VFrameFormat" BO_ 322 14;

BA_ "GenSigSendType" SG_ 322 BMSBscSta 0;
BA_ "SignalLongName" SG_ 322 BMSBscSta "Battery Management System Basic State";

BA_ "GenSigSendType" SG_ 322 BMSOnbdChrgrPlugOn 0;
BA_ "SignalLongName" SG_ 322 BMSOnbdChrgrPlugOn "Battery Management System Onboard Charger Plug On";

BA_ "GenSigSendType" SG_ 322 BMSOfbdChrgrPlugOn 0;
BA_ "SignalLongName" SG_ 322 BMSOfbdChrgrPlugOn "Battery Management System Offboard Charger Plug On";

BA_ "GenMsgSendType" BO_ 336 0;
BA_ "GenMsgStartDelayTime" BO_ 336 10;
BA_ "GenMsgCycleTime" BO_ 336 20;
BA_ "GenMsgILSupport" BO_ 336 1;
BA_ "VFrameFormat" BO_ 336 14;

BA_ "GenSigSendType" SG_ 336 ADUOrFVCMFctryDeftSetFnsh 0;
BA_ "SignalLongName" SG_ 336 ADUOrFVCMFctryDeftSetFnsh "ADU Or FVCM Factory Default tSet Finish";

BA_ "GenSigSendType" SG_ 336 FCMReminderFdbck 0;
BA_ "SignalLongName" SG_ 336 FCMReminderFdbck "Forward Collision Mitgation Reminder Feedback";

BA_ "GenSigSendType" SG_ 336 FCM_AEBMainSwFdbck 0;
BA_ "SignalLongName" SG_ 336 FCM_AEBMainSwFdbck "Forward Collision Mitgation_ Autonomous Emergency Braking Main Switch Feedback";
BA_ "GenSigStartValue" SG_ 336 FCM_AEBMainSwFdbck 1;

BA_ "GenSigSendType" SG_ 336 FCMMainSensitivityFdbck 0;
BA_ "SignalLongName" SG_ 336 FCMMainSensitivityFdbck "Forward Collision Mitgation system Main Sensitivity Feedback";
BA_ "GenSigStartValue" SG_ 336 FCMMainSensitivityFdbck 1;

BA_ "GenMsgSendType" BO_ 338 0;
BA_ "GenMsgStartDelayTime" BO_ 338 10;
BA_ "GenMsgCycleTime" BO_ 338 20;
BA_ "GenMsgILSupport" BO_ 338 1;
BA_ "VFrameFormat" BO_ 338 14;

BA_ "GenSigSendType" SG_ 338 ICA_ALCAMainSwFdbck 0;
BA_ "SignalLongName" SG_ 338 ICA_ALCAMainSwFdbck "ICA_ALCA Main Switch Feedback";

BA_ "GenMsgSendType" BO_ 342 0;
BA_ "GenMsgStartDelayTime" BO_ 342 10;
BA_ "GenMsgCycleTime" BO_ 342 20;
BA_ "GenMsgILSupport" BO_ 342 1;
BA_ "VFrameFormat" BO_ 342 14;

BA_ "GenSigSendType" SG_ 342 PASoundInfo 0;
BA_ "SignalLongName" SG_ 342 PASoundInfo "Parking Assist Sound Information";

BA_ "GenSigSendType" SG_ 342 PASoundCtrlSetReqFdbck 0;
BA_ "SignalLongName" SG_ 342 PASoundCtrlSetReqFdbck "Parking Assist Sound Control Set Request Feedback";

BA_ "GenSigSendType" SG_ 342 APAFctryDeftSetFnsh 0;
BA_ "SignalLongName" SG_ 342 APAFctryDeftSetFnsh "APA Factory Default Setting Finished";

BA_ "GenSigSendType" SG_ 342 APALanguageFdbck 0;
BA_ "SignalLongName" SG_ 342 APALanguageFdbck "APALanguageFeedback";

BA_ "GenMsgSendType" BO_ 343 0;
BA_ "GenMsgStartDelayTime" BO_ 343 10;
BA_ "GenMsgCycleTime" BO_ 343 20;
BA_ "GenMsgILSupport" BO_ 343 1;
BA_ "VFrameFormat" BO_ 343 14;

BA_ "GenSigSendType" SG_ 343 RPASts 0;
BA_ "SignalLongName" SG_ 343 RPASts "RPA_Status";

BA_ "GenSigSendType" SG_ 343 APASts 0;
BA_ "SignalLongName" SG_ 343 APASts "APA_Status";

BA_ "GenMsgSendType" BO_ 345 0;
BA_ "GenMsgStartDelayTime" BO_ 345 10;
BA_ "GenMsgCycleTime" BO_ 345 20;
BA_ "GenMsgILSupport" BO_ 345 1;
BA_ "VFrameFormat" BO_ 345 14;

BA_ "GenSigSendType" SG_ 345 AESMainSwFdbck 0;
BA_ "SignalLongName" SG_ 345 AESMainSwFdbck "Automatic Emergency Steering Main Switch Feedback";

BA_ "GenMsgSendType" BO_ 347 0;
BA_ "GenMsgStartDelayTime" BO_ 347 10;
BA_ "GenMsgCycleTime" BO_ 347 20;
BA_ "GenMsgILSupport" BO_ 347 1;
BA_ "VFrameFormat" BO_ 347 14;

BA_ "GenSigSendType" SG_ 347 LDWAccuracyFdbck 0;
BA_ "SignalLongName" SG_ 347 LDWAccuracyFdbck "Lane Departure Warning Accuracy Feadback";
BA_ "GenSigStartValue" SG_ 347 LDWAccuracyFdbck 1;

BA_ "GenSigSendType" SG_ 347 ELKMainSwFdbck 0;
BA_ "SignalLongName" SG_ 347 ELKMainSwFdbck "Emergency Lane keeping Main Switch Feedback";
BA_ "GenSigStartValue" SG_ 347 ELKMainSwFdbck 1;

BA_ "GenSigSendType" SG_ 347 LDWReminderFdbck 0;
BA_ "SignalLongName" SG_ 347 LDWReminderFdbck "Lane Departure Warning ReminderFeadback";
BA_ "GenSigTimeoutValue" SG_ 347 LDWReminderFdbck 3;
BA_ "GenSigStartValue" SG_ 347 LDWReminderFdbck 3;

BA_ "GenSigSendType" SG_ 347 LDWSundWrnngFdbck 0;
BA_ "SignalLongName" SG_ 347 LDWSundWrnngFdbck "Lane Departure Warning Sound Warning Feedback";
BA_ "GenSigStartValue" SG_ 347 LDWSundWrnngFdbck 1;

BA_ "GenSigSendType" SG_ 347 LKA_LDW_ELKMainSwFdbck 0;
BA_ "SignalLongName" SG_ 347 LKA_LDW_ELKMainSwFdbck "Lane Keeping Assist_ Lane Departure Warning _Emergency Lane keeping Main Switch Feedback";
BA_ "GenSigStartValue" SG_ 347 LKA_LDW_ELKMainSwFdbck 1;

BA_ "GenSigSendType" SG_ 347 LKA_LDWMainSwFdbck 0;
BA_ "SignalLongName" SG_ 347 LKA_LDWMainSwFdbck "Lane Keeping Assist_ Lane Departure Warning Main Switch Feedback";
BA_ "GenSigStartValue" SG_ 347 LKA_LDWMainSwFdbck 2;

BA_ "GenMsgSendType" BO_ 381 0;
BA_ "GenMsgStartDelayTime" BO_ 381 10;
BA_ "GenMsgCycleTime" BO_ 381 20;
BA_ "GenMsgILSupport" BO_ 381 1;
BA_ "VFrameFormat" BO_ 381 14;

BA_ "GenSigSendType" SG_ 381 CampEPTRdy 0;
BA_ "SignalLongName" SG_ 381 CampEPTRdy "Camp Electric Powertrain Ready";

BA_ "GenSigSendType" SG_ 381 HVReady 0;
BA_ "SignalLongName" SG_ 381 HVReady "High voltage ready";

BA_ "GenSigSendType" SG_ 381 CampEPTRunAbotd 0;
BA_ "SignalLongName" SG_ 381 CampEPTRunAbotd "Camp Electric Powertrain Run Aborted";

BA_ "GenSigSendType" SG_ 381 CampEPTCrkAbotd 0;
BA_ "SignalLongName" SG_ 381 CampEPTCrkAbotd "Camp Electric Powertrain Crank Aborted";

BA_ "GenSigSendType" SG_ 381 CampEPTRunAbotdRsn 0;
BA_ "SignalLongName" SG_ 381 CampEPTRunAbotdRsn "Camp Electric Powertrain Run Aborted Reason";

BA_ "GenSigSendType" SG_ 381 CampEPTCrkAbotdRsn 0;
BA_ "SignalLongName" SG_ 381 CampEPTCrkAbotdRsn "Camp Electric Powertrain Crank Aborted Reason";

BA_ "GenMsgSendType" BO_ 393 0;
BA_ "GenMsgStartDelayTime" BO_ 393 15;
BA_ "GenMsgCycleTime" BO_ 393 20;
BA_ "GenMsgILSupport" BO_ 393 1;
BA_ "VFrameFormat" BO_ 393 14;

BA_ "GenSigSendType" SG_ 393 VehSpdV 0;
BA_ "SignalLongName" SG_ 393 VehSpdV "VehicleSpeed_Valid";

BA_ "GenSigSendType" SG_ 393 VehSpd 0;
BA_ "SignalLongName" SG_ 393 VehSpd "VehicleSpeed";
BA_ "GenSigStartValue" SG_ 393 VehSpd 32767;

BA_ "GenSigSendType" SG_ 393 VehSpd_RllCnt 0;
BA_ "SignalLongName" SG_ 393 VehSpd_RllCnt "VehSpd Rolling Counter";

BA_ "GenSigSendType" SG_ 393 VehSpd_ChkSum 0;
BA_ "SignalLongName" SG_ 393 VehSpd_ChkSum "VehSpd CheckSum";

BA_ "GenMsgSendType" BO_ 402 0;
BA_ "GenMsgStartDelayTime" BO_ 402 10;
BA_ "GenMsgCycleTime" BO_ 402 20;
BA_ "GenMsgILSupport" BO_ 402 1;
BA_ "VFrameFormat" BO_ 402 14;

BA_ "GenSigSendType" SG_ 402 StrgWhlAng 0;
BA_ "SignalLongName" SG_ 402 StrgWhlAng "Steering Wheel Angle";

BA_ "GenSigSendType" SG_ 402 StrgWhlAngSnsrFlt 0;
BA_ "SignalLongName" SG_ 402 StrgWhlAngSnsrFlt "Steering Wheel Angle Sensor Fault";

BA_ "GenSigSendType" SG_ 402 StrgWhlAngSnsrInid 0;
BA_ "SignalLongName" SG_ 402 StrgWhlAngSnsrInid "Steering Wheel Angle Sensor Initialized";

BA_ "GenSigSendType" SG_ 402 StrgWhlAngV 0;
BA_ "SignalLongName" SG_ 402 StrgWhlAngV "Steering Wheel Angle Validity";

BA_ "GenSigSendType" SG_ 402 StrgWhlAngGrd 0;
BA_ "SignalLongName" SG_ 402 StrgWhlAngGrd "Steering Wheel Angle Gradient";

BA_ "GenSigSendType" SG_ 402 StrAnglSnsrInfo_RllCnt 0;
BA_ "SignalLongName" SG_ 402 StrAnglSnsrInfo_RllCnt "StrAnglSnsrInfo Rolling Counter";

BA_ "GenSigSendType" SG_ 402 StrgWhlAngSnsrCalSts 0;
BA_ "SignalLongName" SG_ 402 StrgWhlAngSnsrCalSts "Steering Wheel Angle Sensor Calibration Status";

BA_ "GenSigSendType" SG_ 402 StrAnglSnsrInfo_ChkSum 0;
BA_ "SignalLongName" SG_ 402 StrAnglSnsrInfo_ChkSum "StrAnglSnsrInfo RCheckSum";

BA_ "GenMsgSendType" BO_ 403 0;
BA_ "GenMsgStartDelayTime" BO_ 403 10;
BA_ "GenMsgCycleTime" BO_ 403 20;
BA_ "GenMsgILSupport" BO_ 403 1;
BA_ "VFrameFormat" BO_ 403 14;

BA_ "GenSigSendType" SG_ 403 EPSCurrMod 0;
BA_ "SignalLongName" SG_ 403 EPSCurrMod "EPS current Mode";

BA_ "GenSigSendType" SG_ 403 EPSInfo_RllCnt 0;
BA_ "SignalLongName" SG_ 403 EPSInfo_RllCnt "EPSInfo Rolling Counter";

BA_ "GenSigSendType" SG_ 403 EPSFctryDfltSttngFnshd 0;
BA_ "SignalLongName" SG_ 403 EPSFctryDfltSttngFnshd "EPS Factory Default Setting Finished";

BA_ "GenSigSendType" SG_ 403 EPSInfo_ChkSum 0;
BA_ "SignalLongName" SG_ 403 EPSInfo_ChkSum "EPSInfo CheckSum";

BA_ "GenMsgSendType" BO_ 408 0;
BA_ "GenMsgStartDelayTime" BO_ 408 15;
BA_ "GenMsgCycleTime" BO_ 408 20;
BA_ "GenMsgILSupport" BO_ 408 1;
BA_ "VFrameFormat" BO_ 408 14;

BA_ "GenSigSendType" SG_ 408 EPBSysDispMsgReq 0;
BA_ "SignalLongName" SG_ 408 EPBSysDispMsgReq "EPBSystemDisplayMessageRequest";

BA_ "GenSigSendType" SG_ 408 EPBAppcnSts 0;
BA_ "SignalLongName" SG_ 408 EPBAppcnSts "EPBApplicationStatus";

BA_ "GenSigSendType" SG_ 408 EPBIgnoffAutoAppFnFdbck1 0;
BA_ "SignalLongName" SG_ 408 EPBIgnoffAutoAppFnFdbck1 "EPBIgnoffAutoapplyFunctionFeedback1";

BA_ "GenMsgSendType" BO_ 441 0;
BA_ "GenMsgStartDelayTime" BO_ 441 10;
BA_ "GenMsgCycleTime" BO_ 441 500;
BA_ "GenMsgILSupport" BO_ 441 1;
BA_ "GenMsgCycleTimeFast" BO_ 441 40;
BA_ "GenMsgNrOfRepetition" BO_ 441 3;
BA_ "GenMsgDelayTime" BO_ 441 20;
BA_ "VFrameFormat" BO_ 441 14;

BA_ "GenSigSendType" SG_ 441 HUDEnbSetResp 4;
BA_ "SignalLongName" SG_ 441 HUDEnbSetResp "HUD Enable Set Response";

BA_ "GenSigSendType" SG_ 441 HUDDmAdjResp 4;
BA_ "SignalLongName" SG_ 441 HUDDmAdjResp "HUD Dimming Adjust Response";
BA_ "GenSigStartValue" SG_ 441 HUDDmAdjResp 10;

BA_ "GenSigSendType" SG_ 441 HUDPctAlttdAdjResp 4;
BA_ "SignalLongName" SG_ 441 HUDPctAlttdAdjResp "HUD Picture Altitude Adjust Response";
BA_ "GenSigStartValue" SG_ 441 HUDPctAlttdAdjResp 10;

BA_ "GenSigSendType" SG_ 441 HUDPctInclntAdjResp 4;
BA_ "SignalLongName" SG_ 441 HUDPctInclntAdjResp "HUD Picture Inclination Adjust Response";
BA_ "GenSigStartValue" SG_ 441 HUDPctInclntAdjResp 3;

BA_ "GenMsgSendType" BO_ 444 0;
BA_ "GenMsgStartDelayTime" BO_ 444 15;
BA_ "GenMsgCycleTime" BO_ 444 20;
BA_ "GenMsgILSupport" BO_ 444 1;
BA_ "VFrameFormat" BO_ 444 14;

BA_ "GenSigSendType" SG_ 444 ChmCmdSndLoctnFL 0;
BA_ "SignalLongName" SG_ 444 ChmCmdSndLoctnFL "ChimeCommandSoundLocationFrontLeft";

BA_ "GenSigSendType" SG_ 444 ChmCmdSndLoctnFR 0;
BA_ "SignalLongName" SG_ 444 ChmCmdSndLoctnFR "ChimeCommandSoundLocationFrontRight";

BA_ "GenSigSendType" SG_ 444 ChmCmdSndLoctnRL 0;
BA_ "SignalLongName" SG_ 444 ChmCmdSndLoctnRL "ChimeCommandSoundLocationRearLeft";

BA_ "GenSigSendType" SG_ 444 ChmCmdSndLoctnRR 0;
BA_ "SignalLongName" SG_ 444 ChmCmdSndLoctnRR "ChimeCommandSoundLocationRearRight";

BA_ "GenSigSendType" SG_ 444 ChmCmdSndTone 0;
BA_ "SignalLongName" SG_ 444 ChmCmdSndTone "ChimeCommandSoundTone";

BA_ "GenSigSendType" SG_ 444 ChmCmdSndCndcPrd 0;
BA_ "SignalLongName" SG_ 444 ChmCmdSndCndcPrd "ChimeCommandSoundLocationFrontLeftCandencePeriod";

BA_ "GenSigSendType" SG_ 444 ChmCmdSndDutyCyc 0;
BA_ "SignalLongName" SG_ 444 ChmCmdSndDutyCyc "ChimeCommandSoundDutyCycle";

BA_ "GenSigSendType" SG_ 444 PgTrnUp 0;
BA_ "SignalLongName" SG_ 444 PgTrnUp "PageTurnUp";

BA_ "GenSigSendType" SG_ 444 PgTrnDw 0;
BA_ "SignalLongName" SG_ 444 PgTrnDw "PageTurnDown";

BA_ "GenSigSendType" SG_ 444 PgTrnRt 0;
BA_ "SignalLongName" SG_ 444 PgTrnRt "PageTurnRight";

BA_ "GenSigSendType" SG_ 444 PgTrnLf 0;
BA_ "SignalLongName" SG_ 444 PgTrnLf "PageTurnLeft";

BA_ "GenSigSendType" SG_ 444 PgTrnOK 0;
BA_ "SignalLongName" SG_ 444 PgTrnOK "PageTurnOK";

BA_ "GenSigSendType" SG_ 444 IPKTabReq 0;
BA_ "SignalLongName" SG_ 444 IPKTabReq "IPK Tab Request";

BA_ "GenMsgSendType" BO_ 445 0;
BA_ "GenMsgStartDelayTime" BO_ 445 10;
BA_ "GenMsgCycleTime" BO_ 445 50;
BA_ "GenMsgILSupport" BO_ 445 1;
BA_ "VFrameFormat" BO_ 445 14;

BA_ "GenSigSendType" SG_ 445 SysPwrMd 0;
BA_ "SignalLongName" SG_ 445 SysPwrMd "System Power Mode";

BA_ "GenSigSendType" SG_ 445 SysPwrMdV 0;
BA_ "SignalLongName" SG_ 445 SysPwrMdV "System Power Mode Validity";

BA_ "GenSigSendType" SG_ 445 TransMd 0;
BA_ "SignalLongName" SG_ 445 TransMd "Transportation Mode";

BA_ "GenSigSendType" SG_ 445 RVSReq 0;
BA_ "SignalLongName" SG_ 445 RVSReq "Remote Vehicle Start Request";

BA_ "GenSigSendType" SG_ 445 VehiclePwrSts_RllCnt 0;
BA_ "SignalLongName" SG_ 445 VehiclePwrSts_RllCnt "VehiclePwrSts Rolling Counter";

BA_ "GenSigSendType" SG_ 445 VehiclePwrSts_ChkSum 0;
BA_ "SignalLongName" SG_ 445 VehiclePwrSts_ChkSum "VehiclePwrSts CheckSum";

BA_ "GenMsgSendType" BO_ 447 0;
BA_ "GenMsgStartDelayTime" BO_ 447 15;
BA_ "GenMsgCycleTime" BO_ 447 20;
BA_ "GenMsgILSupport" BO_ 447 1;
BA_ "VFrameFormat" BO_ 447 14;

BA_ "GenSigSendType" SG_ 447 AVHSysDispMsgReq 0;
BA_ "SignalLongName" SG_ 447 AVHSysDispMsgReq "AutoHoldSystemDisplayMessageRequest";

BA_ "GenSigSendType" SG_ 447 ESCFnOffFdbck 0;
BA_ "SignalLongName" SG_ 447 ESCFnOffFdbck "ESCFunctionOffFeedback";

BA_ "GenSigSendType" SG_ 447 AVHFnFdbck 0;
BA_ "SignalLongName" SG_ 447 AVHFnFdbck "AVHFunctionFeedback";

BA_ "GenSigSendType" SG_ 447 HDCFnFdbck 0;
BA_ "SignalLongName" SG_ 447 HDCFnFdbck "HDCFunctionFeedback";

BA_ "GenSigSendType" SG_ 447 DrvngMdDisp 0;
BA_ "SignalLongName" SG_ 447 DrvngMdDisp "DrivingModeDisplay";
BA_ "GenSigStartValue" SG_ 447 DrvngMdDisp 15;

BA_ "GenSigSendType" SG_ 447 EPBIgnoffAutoAppFnFdbck 0;
BA_ "SignalLongName" SG_ 447 EPBIgnoffAutoAppFnFdbck "EPBIgnoffAutoapplyFunctionFeedback";

BA_ "GenSigSendType" SG_ 447 ESC_HMI_RllCnt 0;
BA_ "SignalLongName" SG_ 447 ESC_HMI_RllCnt "HMI Counter";

BA_ "GenSigSendType" SG_ 447 ESC_HMI_ChkSum 0;
BA_ "SignalLongName" SG_ 447 ESC_HMI_ChkSum "HMICheckSum";

BA_ "GenMsgSendType" BO_ 457 0;
BA_ "GenMsgStartDelayTime" BO_ 457 20;
BA_ "GenMsgCycleTime" BO_ 457 50;
BA_ "GenMsgILSupport" BO_ 457 1;
BA_ "VFrameFormat" BO_ 457 14;

BA_ "GenSigSendType" SG_ 457 DMSSwFdbck 0;
BA_ "SignalLongName" SG_ 457 DMSSwFdbck "DMS Switch Feedback";

BA_ "GenSigSendType" SG_ 457 FatigueMoniSwFdbck 0;
BA_ "SignalLongName" SG_ 457 FatigueMoniSwFdbck "Fatigue Monitoring Setting Switch Feedback";

BA_ "GenSigSendType" SG_ 457 DistractionMoniSwFdbck 0;
BA_ "SignalLongName" SG_ 457 DistractionMoniSwFdbck "Distraction Monitoring Setting Switch Feedback";

BA_ "GenMsgSendType" BO_ 474 0;
BA_ "GenMsgStartDelayTime" BO_ 474 15;
BA_ "GenMsgCycleTime" BO_ 474 50;
BA_ "GenMsgILSupport" BO_ 474 1;
BA_ "VFrameFormat" BO_ 474 14;

BA_ "GenSigSendType" SG_ 474 IHCMainSwFdbck 0;
BA_ "SignalLongName" SG_ 474 IHCMainSwFdbck "Intelligence Headlamp Control Main Switch Feedback";

BA_ "GenSigSendType" SG_ 474 SLIFMainSwFdbck 0;
BA_ "SignalLongName" SG_ 474 SLIFMainSwFdbck "Speed Limit Information Function Main Switch Feedback";
BA_ "GenSigStartValue" SG_ 474 SLIFMainSwFdbck 1;

BA_ "GenSigSendType" SG_ 474 SLIFVsulWrnng 0;
BA_ "SignalLongName" SG_ 474 SLIFVsulWrnng "Speed Limit Information Function Visual Warning";

BA_ "GenSigSendType" SG_ 474 ISAMainSwFdbck 0;
BA_ "SignalLongName" SG_ 474 ISAMainSwFdbck "Intelligent Speed Assistance Main Switch Feedback";
BA_ "GenSigStartValue" SG_ 474 ISAMainSwFdbck 1;

BA_ "GenSigSendType" SG_ 474 SLIFSundWrnngFdbck 0;
BA_ "SignalLongName" SG_ 474 SLIFSundWrnngFdbck "Speed Limit Information Function Warning Feedback";

BA_ "GenSigSendType" SG_ 474 SLIF_ISAMainSwFdbck 0;
BA_ "SignalLongName" SG_ 474 SLIF_ISAMainSwFdbck "Speed Limit Information Function_Intelligent Speed Assistance Main Switch Feedback";

BA_ "GenSigSendType" SG_ 474 IHC_SLIFSts_RllCnt 0;
BA_ "SignalLongName" SG_ 474 IHC_SLIFSts_RllCnt "IHC_SLIFSts Rolling Counter";

BA_ "GenSigSendType" SG_ 474 IHC_SLIFSts_ChkSum 0;
BA_ "SignalLongName" SG_ 474 IHC_SLIFSts_ChkSum "IHC_SLIFSts Check Sum";

BA_ "GenMsgSendType" BO_ 476 0;
BA_ "GenMsgStartDelayTime" BO_ 476 15;
BA_ "GenMsgCycleTime" BO_ 476 50;
BA_ "GenMsgILSupport" BO_ 476 1;
BA_ "VFrameFormat" BO_ 476 14;

BA_ "GenSigSendType" SG_ 476 RAEBSta 0;
BA_ "SignalLongName" SG_ 476 RAEBSta "Rear Autonomous Emergency Braking";
BA_ "GenSigStartValue" SG_ 476 RAEBSta 2;

BA_ "GenMsgSendType" BO_ 478 0;
BA_ "GenMsgStartDelayTime" BO_ 478 15;
BA_ "GenMsgCycleTime" BO_ 478 50;
BA_ "GenMsgILSupport" BO_ 478 1;
BA_ "VFrameFormat" BO_ 478 14;

BA_ "GenSigSendType" SG_ 478 SRR_RFctryDeftSetFnshSlavetoMstr 0;
BA_ "SignalLongName" SG_ 478 SRR_RFctryDeftSetFnshSlavetoMstr "SRR_R Factory Default tSet Finish Slave to Master";

BA_ "GenSigSendType" SG_ 478 BDASts_R_RllCnt 0;
BA_ "SignalLongName" SG_ 478 BDASts_R_RllCnt "BDASts_R Rolling Counter";

BA_ "GenSigSendType" SG_ 478 BDASts_R_ChkSum 0;
BA_ "SignalLongName" SG_ 478 BDASts_R_ChkSum "BDASts_R Check Sum";

BA_ "GenMsgSendType" BO_ 479 0;
BA_ "GenMsgStartDelayTime" BO_ 479 15;
BA_ "GenMsgCycleTime" BO_ 479 50;
BA_ "GenMsgILSupport" BO_ 479 1;
BA_ "VFrameFormat" BO_ 479 14;

BA_ "GenSigSendType" SG_ 479 BSDMainSwFdbck 0;
BA_ "SignalLongName" SG_ 479 BSDMainSwFdbck "Blind Spot Detect Main Switch Feedback";

BA_ "GenSigSendType" SG_ 479 SRR_R_MFctryDeftSetFnsh 0;
BA_ "SignalLongName" SG_ 479 SRR_R_MFctryDeftSetFnsh "SRR_R_M Factory Default tSet Finish";

BA_ "GenSigSendType" SG_ 479 BSDLCAMainSwFdbck 0;

BA_ "GenSigSendType" SG_ 479 RCTAMainSwFdbck 0;

BA_ "GenSigSendType" SG_ 479 DOWMainSwFdbck 0;

BA_ "GenSigSendType" SG_ 479 BDASts_L_RllCnt 0;
BA_ "SignalLongName" SG_ 479 BDASts_L_RllCnt "BDASts_L Rolling Counter";

BA_ "GenSigSendType" SG_ 479 BDASts_L_ChkSum 0;
BA_ "SignalLongName" SG_ 479 BDASts_L_ChkSum "BDASts_L Check Sum";

BA_ "GenMsgSendType" BO_ 485 0;
BA_ "GenMsgStartDelayTime" BO_ 485 15;
BA_ "GenMsgCycleTime" BO_ 485 50;
BA_ "GenMsgILSupport" BO_ 485 1;
BA_ "VFrameFormat" BO_ 485 14;

BA_ "GenSigSendType" SG_ 485 UltraRdrSnsrSts_1 0;
BA_ "SignalLongName" SG_ 485 UltraRdrSnsrSts_1 "Ultrasonic Radar Sensor Status_1";

BA_ "GenSigSendType" SG_ 485 UltraRdrSnsrObjWrnngZn_1 0;
BA_ "SignalLongName" SG_ 485 UltraRdrSnsrObjWrnngZn_1 "Ultrasonic Radar Sensor Object Warning Zone_1";

BA_ "GenSigSendType" SG_ 485 UltraRdrSnsrSts_6 0;
BA_ "SignalLongName" SG_ 485 UltraRdrSnsrSts_6 "Ultrasonic Radar Sensor Status_6";

BA_ "GenSigSendType" SG_ 485 UltraRdrSnsrObjWrnngZn_6 0;
BA_ "SignalLongName" SG_ 485 UltraRdrSnsrObjWrnngZn_6 "Ultrasonic Radar Sensor Object Warning Zone_6";

BA_ "GenSigSendType" SG_ 485 UltraRdrSnsrSts_7 0;
BA_ "SignalLongName" SG_ 485 UltraRdrSnsrSts_7 "Ultrasonic Radar Sensor Status_7";

BA_ "GenSigSendType" SG_ 485 UltraRdrSnsrObjWrnngZn_7 0;
BA_ "SignalLongName" SG_ 485 UltraRdrSnsrObjWrnngZn_7 "Ultrasonic Radar Sensor Object Warning Zone_7";

BA_ "GenSigSendType" SG_ 485 UltraRdrSnsrSts_12 0;
BA_ "SignalLongName" SG_ 485 UltraRdrSnsrSts_12 "Ultrasonic Radar Sensor Status_12";

BA_ "GenSigSendType" SG_ 485 UltraRdrSnsrObjWrnngZn_12 0;
BA_ "SignalLongName" SG_ 485 UltraRdrSnsrObjWrnngZn_12 "Ultrasonic Radar Sensor Object Warning Zone_12";

BA_ "GenSigSendType" SG_ 485 UltraRdrSnsrDist_1 0;
BA_ "SignalLongName" SG_ 485 UltraRdrSnsrDist_1 "Ultrasonic Radar Sensor Distance_1";
BA_ "GenSigStartValue" SG_ 485 UltraRdrSnsrDist_1 510;

BA_ "GenSigSendType" SG_ 485 UltraRdrSnsrDist_6 0;
BA_ "SignalLongName" SG_ 485 UltraRdrSnsrDist_6 "Ultrasonic Radar Sensor Distance_6";
BA_ "GenSigStartValue" SG_ 485 UltraRdrSnsrDist_6 510;

BA_ "GenSigSendType" SG_ 485 UltraRdrSnsrDist_7 0;
BA_ "SignalLongName" SG_ 485 UltraRdrSnsrDist_7 "Ultrasonic Radar Sensor Distance_7";
BA_ "GenSigStartValue" SG_ 485 UltraRdrSnsrDist_7 510;

BA_ "GenSigSendType" SG_ 485 UltraRdrSnsrDist_12 0;
BA_ "SignalLongName" SG_ 485 UltraRdrSnsrDist_12 "Ultrasonic Radar Sensor Distance_12";
BA_ "GenSigStartValue" SG_ 485 UltraRdrSnsrDist_12 510;

BA_ "GenMsgSendType" BO_ 486 0;
BA_ "GenMsgStartDelayTime" BO_ 486 10;
BA_ "GenMsgCycleTime" BO_ 486 50;
BA_ "GenMsgILSupport" BO_ 486 1;
BA_ "VFrameFormat" BO_ 486 14;

BA_ "GenSigSendType" SG_ 486 UltraRdrSnsrSts_8 0;
BA_ "SignalLongName" SG_ 486 UltraRdrSnsrSts_8 "Ultrasonic Radar Sensor Status_8";

BA_ "GenSigSendType" SG_ 486 UltraRdrSnsrObjWrnngZn_8 0;
BA_ "SignalLongName" SG_ 486 UltraRdrSnsrObjWrnngZn_8 "Ultrasonic Radar Sensor Object Warning Zone_8";

BA_ "GenSigSendType" SG_ 486 UltraRdrSnsrSts_9 0;
BA_ "SignalLongName" SG_ 486 UltraRdrSnsrSts_9 "Ultrasonic Radar Sensor Status_9";

BA_ "GenSigSendType" SG_ 486 UltraRdrSnsrObjWrnngZn_9 0;
BA_ "SignalLongName" SG_ 486 UltraRdrSnsrObjWrnngZn_9 "Ultrasonic Radar Sensor Object Warning Zone_9";

BA_ "GenSigSendType" SG_ 486 UltraRdrSnsrSts_10 0;
BA_ "SignalLongName" SG_ 486 UltraRdrSnsrSts_10 "Ultrasonic Radar Sensor Status_10";

BA_ "GenSigSendType" SG_ 486 UltraRdrSnsrObjWrnngZn_10 0;
BA_ "SignalLongName" SG_ 486 UltraRdrSnsrObjWrnngZn_10 "Ultrasonic Radar Sensor Object Warning Zone_10";

BA_ "GenSigSendType" SG_ 486 UltraRdrSnsrSts_11 0;
BA_ "SignalLongName" SG_ 486 UltraRdrSnsrSts_11 "Ultrasonic Radar Sensor Status_11";

BA_ "GenSigSendType" SG_ 486 UltraRdrSnsrObjWrnngZn_11 0;
BA_ "SignalLongName" SG_ 486 UltraRdrSnsrObjWrnngZn_11 "Ultrasonic Radar Sensor Object Warning Zone_11";

BA_ "GenSigSendType" SG_ 486 UltraRdrSnsrDist_8 0;
BA_ "SignalLongName" SG_ 486 UltraRdrSnsrDist_8 "Ultrasonic Radar Sensor Distance_8";
BA_ "GenSigStartValue" SG_ 486 UltraRdrSnsrDist_8 254;

BA_ "GenSigSendType" SG_ 486 UltraRdrSnsrDist_9 0;
BA_ "SignalLongName" SG_ 486 UltraRdrSnsrDist_9 "Ultrasonic Radar Sensor Distance_9";
BA_ "GenSigStartValue" SG_ 486 UltraRdrSnsrDist_9 254;

BA_ "GenSigSendType" SG_ 486 UltraRdrSnsrDist_10 0;
BA_ "SignalLongName" SG_ 486 UltraRdrSnsrDist_10 "Ultrasonic Radar Sensor Distance_10";
BA_ "GenSigStartValue" SG_ 486 UltraRdrSnsrDist_10 254;

BA_ "GenSigSendType" SG_ 486 UltraRdrSnsrDist_11 0;
BA_ "SignalLongName" SG_ 486 UltraRdrSnsrDist_11 "Ultrasonic Radar Sensor Distance_11";
BA_ "GenSigStartValue" SG_ 486 UltraRdrSnsrDist_11 254;

BA_ "GenSigSendType" SG_ 486 PDCBeepOffReqFdbck_R 0;
BA_ "SignalLongName" SG_ 486 PDCBeepOffReqFdbck_R "PDC Beep Off Request Feedback_Rear";

BA_ "GenMsgSendType" BO_ 487 0;
BA_ "GenMsgStartDelayTime" BO_ 487 10;
BA_ "GenMsgCycleTime" BO_ 487 50;
BA_ "GenMsgILSupport" BO_ 487 1;
BA_ "VFrameFormat" BO_ 487 14;

BA_ "GenSigSendType" SG_ 487 UltraRdrSnsrSts_2 0;
BA_ "SignalLongName" SG_ 487 UltraRdrSnsrSts_2 "Ultrasonic Radar Sensor Status_2";

BA_ "GenSigSendType" SG_ 487 UltraRdrSnsrObjWrnngZn_2 0;
BA_ "SignalLongName" SG_ 487 UltraRdrSnsrObjWrnngZn_2 "Ultrasonic Radar Sensor Object Warning Zone_2";

BA_ "GenSigSendType" SG_ 487 UltraRdrSnsrSts_3 0;
BA_ "SignalLongName" SG_ 487 UltraRdrSnsrSts_3 "Ultrasonic Radar Sensor Status_3";

BA_ "GenSigSendType" SG_ 487 UltraRdrSnsrObjWrnngZn_3 0;
BA_ "SignalLongName" SG_ 487 UltraRdrSnsrObjWrnngZn_3 "Ultrasonic Radar Sensor Object Warning Zone_3";

BA_ "GenSigSendType" SG_ 487 UltraRdrSnsrSts_4 0;
BA_ "SignalLongName" SG_ 487 UltraRdrSnsrSts_4 "Ultrasonic Radar Sensor Status_4";

BA_ "GenSigSendType" SG_ 487 UltraRdrSnsrObjWrnngZn_4 0;
BA_ "SignalLongName" SG_ 487 UltraRdrSnsrObjWrnngZn_4 "Ultrasonic Radar Sensor Object Warning Zone_4";

BA_ "GenSigSendType" SG_ 487 UltraRdrSnsrSts_5 0;
BA_ "SignalLongName" SG_ 487 UltraRdrSnsrSts_5 "Ultrasonic Radar Sensor Status_5";

BA_ "GenSigSendType" SG_ 487 UltraRdrSnsrObjWrnngZn_5 0;
BA_ "SignalLongName" SG_ 487 UltraRdrSnsrObjWrnngZn_5 "Ultrasonic Radar Sensor Object Warning Zone_5";

BA_ "GenSigSendType" SG_ 487 UltraRdrSnsrDist_2 0;
BA_ "SignalLongName" SG_ 487 UltraRdrSnsrDist_2 "Ultrasonic Radar Sensor Distance_2";
BA_ "GenSigStartValue" SG_ 487 UltraRdrSnsrDist_2 254;

BA_ "GenSigSendType" SG_ 487 UltraRdrSnsrDist_3 0;
BA_ "SignalLongName" SG_ 487 UltraRdrSnsrDist_3 "Ultrasonic Radar Sensor Distance_3";
BA_ "GenSigStartValue" SG_ 487 UltraRdrSnsrDist_3 254;

BA_ "GenSigSendType" SG_ 487 UltraRdrSnsrDist_4 0;
BA_ "SignalLongName" SG_ 487 UltraRdrSnsrDist_4 "Ultrasonic Radar Sensor Distance_4";
BA_ "GenSigStartValue" SG_ 487 UltraRdrSnsrDist_4 254;

BA_ "GenSigSendType" SG_ 487 UltraRdrSnsrDist_5 0;
BA_ "SignalLongName" SG_ 487 UltraRdrSnsrDist_5 "Ultrasonic Radar Sensor Distance_5";
BA_ "GenSigStartValue" SG_ 487 UltraRdrSnsrDist_5 254;

BA_ "GenSigSendType" SG_ 487 PDCBeepOffReqFdbck_F 0;
BA_ "SignalLongName" SG_ 487 PDCBeepOffReqFdbck_F "PDC Beep Off Request Feedback_Front";

BA_ "GenSigSendType" SG_ 487 PDCMainSWFdbck 0;
BA_ "SignalLongName" SG_ 487 PDCMainSWFdbck "PDC Main Switch Feedback";

BA_ "GenMsgSendType" BO_ 490 0;
BA_ "GenMsgStartDelayTime" BO_ 490 15;
BA_ "GenMsgCycleTime" BO_ 490 50;
BA_ "GenMsgILSupport" BO_ 490 1;
BA_ "GenMsgDelayTime" BO_ 490 20;
BA_ "VFrameFormat" BO_ 490 14;

BA_ "GenSigSendType" SG_ 490 AVMSts 0;
BA_ "SignalLongName" SG_ 490 AVMSts "AVMStatus";

BA_ "GenSigSendType" SG_ 490 VideoReq 0;
BA_ "SignalLongName" SG_ 490 VideoReq "AVMVideoRequest";

BA_ "GenSigSendType" SG_ 490 VideoReqV 0;
BA_ "SignalLongName" SG_ 490 VideoReqV "VideoRequestValidly";

BA_ "GenSigSendType" SG_ 490 SnsSldDrActnTypSetReqFdbck 0;
BA_ "SignalLongName" SG_ 490 SnsSldDrActnTypSetReqFdbck "Sensing Sliding Door Action Type Set Request Feedback";

BA_ "GenSigSendType" SG_ 490 SentryMdSetReqFdbck 0;
BA_ "SignalLongName" SG_ 490 SentryMdSetReqFdbck "Sentry Mode Set Request Feedback";

BA_ "GenSigSendType" SG_ 490 RmtAVMReqFdbck 0;
BA_ "SignalLongName" SG_ 490 RmtAVMReqFdbck "Remote AVM Request Feedback";

BA_ "GenSigSendType" SG_ 490 SentryMdSensitivityFdbck 0;
BA_ "SignalLongName" SG_ 490 SentryMdSensitivityFdbck "SentryModeSensitivityFeedback";

BA_ "GenSigSendType" SG_ 490 AVMFctryDeftSetFnsh 0;
BA_ "SignalLongName" SG_ 490 AVMFctryDeftSetFnsh "AVMFactoryDefaultSettingFinished";

BA_ "GenMsgSendType" BO_ 493 0;
BA_ "GenMsgStartDelayTime" BO_ 493 10;
BA_ "GenMsgCycleTime" BO_ 493 50;
BA_ "GenMsgILSupport" BO_ 493 1;
BA_ "VFrameFormat" BO_ 493 14;

BA_ "GenSigSendType" SG_ 493 SysBkupPwrMd 0;
BA_ "SignalLongName" SG_ 493 SysBkupPwrMd "System backup Power Mode";

BA_ "GenSigSendType" SG_ 493 SysBkupPwrMdV 0;
BA_ "SignalLongName" SG_ 493 SysBkupPwrMdV "System backup Power Mode Validity";

BA_ "GenSigSendType" SG_ 493 SysBkupPwrMdEnbl 0;
BA_ "SignalLongName" SG_ 493 SysBkupPwrMdEnbl "System backup Power Mode Enable";

BA_ "GenSigSendType" SG_ 493 SysPwrMdBkup_RllCnt 0;
BA_ "SignalLongName" SG_ 493 SysPwrMdBkup_RllCnt "SysPwrMdBkup Rolling Counter";

BA_ "GenSigSendType" SG_ 493 SysPwrMdBkup_Chksum 0;
BA_ "SignalLongName" SG_ 493 SysPwrMdBkup_Chksum "SysPwrMdBkup Checksum";

BA_ "GenMsgSendType" BO_ 511 0;
BA_ "GenMsgStartDelayTime" BO_ 511 20;
BA_ "GenMsgCycleTime" BO_ 511 50;
BA_ "GenMsgILSupport" BO_ 511 1;
BA_ "VFrameFormat" BO_ 511 14;

BA_ "GenSigSendType" SG_ 511 HMIPhCallReq 0;
BA_ "SignalLongName" SG_ 511 HMIPhCallReq "HMIPhoneCallRequest";

BA_ "GenSigSendType" SG_ 511 HMIMtReq 0;
BA_ "SignalLongName" SG_ 511 HMIMtReq "HMIMuteRequest";

BA_ "GenSigSendType" SG_ 511 HMIVolUpAdjReq 0;
BA_ "SignalLongName" SG_ 511 HMIVolUpAdjReq "HMIVolumeUpAdjustmentRequest";

BA_ "GenSigSendType" SG_ 511 HMIVolDownAdjReq 0;
BA_ "SignalLongName" SG_ 511 HMIVolDownAdjReq "HMIVolumeDownAdjustmentRequest";

BA_ "GenSigSendType" SG_ 511 HMIMscNextAdjReq 0;
BA_ "SignalLongName" SG_ 511 HMIMscNextAdjReq "HMIMusicNextAdjustmentRequest";

BA_ "GenSigSendType" SG_ 511 HMIMscPreAdjReq 0;
BA_ "SignalLongName" SG_ 511 HMIMscPreAdjReq "HMIMusicPreAdjustmentReques";

BA_ "GenSigSendType" SG_ 511 HMIVoiceReq 0;
BA_ "SignalLongName" SG_ 511 HMIVoiceReq "HMIVoiceRequest";

BA_ "GenSigSendType" SG_ 511 HMITlmtcsReq 0;
BA_ "SignalLongName" SG_ 511 HMITlmtcsReq "HMITelematicsRequest";

BA_ "GenSigSendType" SG_ 511 HMISRCReq 0;
BA_ "SignalLongName" SG_ 511 HMISRCReq "HMISRCRequest";

BA_ "GenMsgSendType" BO_ 557 0;
BA_ "GenMsgStartDelayTime" BO_ 557 10;
BA_ "GenMsgCycleTime" BO_ 557 100;
BA_ "GenMsgILSupport" BO_ 557 1;
BA_ "VFrameFormat" BO_ 557 14;

BA_ "GenSigSendType" SG_ 557 BMSChrgrPlugCnctnIO 0;
BA_ "SignalLongName" SG_ 557 BMSChrgrPlugCnctnIO "Battery Management System Charger Plug Connection Indication On";
BA_ "GenSigTimeoutValue" SG_ 557 BMSChrgrPlugCnctnIO 1;
BA_ "GenSigStartValue" SG_ 557 BMSChrgrPlugCnctnIO 1;

BA_ "GenSigSendType" SG_ 557 ChrgngRmnngTimeV 0;
BA_ "SignalLongName" SG_ 557 ChrgngRmnngTimeV "Charging Remaining Time Validity";

BA_ "GenSigSendType" SG_ 557 BMSAvlblEnrgV 0;
BA_ "SignalLongName" SG_ 557 BMSAvlblEnrgV "Battery Management System Available Energy Validity";
BA_ "GenSigTimeoutValue" SG_ 557 BMSAvlblEnrgV 1;
BA_ "GenSigStartValue" SG_ 557 BMSAvlblEnrgV 1;

BA_ "GenSigSendType" SG_ 557 ChrgngRmnngTime 0;
BA_ "SignalLongName" SG_ 557 ChrgngRmnngTime "Charging Remaining Time";
BA_ "GenSigTimeoutValue" SG_ 557 ChrgngRmnngTime 1023;
BA_ "GenSigStartValue" SG_ 557 ChrgngRmnngTime 1023;

BA_ "GenSigSendType" SG_ 557 CampChrgngRmnngTimeExt 0;
BA_ "SignalLongName" SG_ 557 CampChrgngRmnngTimeExt "Camp Charging Remaining Time Extence";
BA_ "GenSigTimeoutValue" SG_ 557 CampChrgngRmnngTimeExt 2047;
BA_ "GenSigStartValue" SG_ 557 CampChrgngRmnngTimeExt 2047;

BA_ "GenSigSendType" SG_ 557 BMSAvlblEnrg 0;
BA_ "SignalLongName" SG_ 557 BMSAvlblEnrg "Battery Management System Available Energy";
BA_ "GenSigTimeoutValue" SG_ 557 BMSAvlblEnrg 255;
BA_ "GenSigStartValue" SG_ 557 BMSAvlblEnrg 255;

BA_ "GenSigSendType" SG_ 557 CampChrgngRmnngTimeExtV 0;
BA_ "SignalLongName" SG_ 557 CampChrgngRmnngTimeExtV "Camp Charging Remaining Time Extence Validity";

BA_ "GenSigSendType" SG_ 557 ChrgngRmnngTimeExtV 0;
BA_ "SignalLongName" SG_ 557 ChrgngRmnngTimeExtV "Charging_Remaining_Time Extend Validity";
BA_ "GenSigTimeoutValue" SG_ 557 ChrgngRmnngTimeExtV 1;
BA_ "GenSigStartValue" SG_ 557 ChrgngRmnngTimeExtV 1;

BA_ "GenSigSendType" SG_ 557 ChrgngRmnngTimeExt 0;
BA_ "SignalLongName" SG_ 557 ChrgngRmnngTimeExt "Charging_Remaining_Time Extend";
BA_ "GenSigTimeoutValue" SG_ 557 ChrgngRmnngTimeExt 2047;
BA_ "GenSigStartValue" SG_ 557 ChrgngRmnngTimeExt 2047;

BA_ "GenMsgSendType" BO_ 626 0;
BA_ "GenMsgStartDelayTime" BO_ 626 15;
BA_ "GenMsgCycleTime" BO_ 626 100;
BA_ "GenMsgILSupport" BO_ 626 1;
BA_ "VFrameFormat" BO_ 626 14;

BA_ "GenSigSendType" SG_ 626 DpfWrnngInf 0;
BA_ "SignalLongName" SG_ 626 DpfWrnngInf "DPF Warning Information";

BA_ "GenSigSendType" SG_ 626 RGNinactivereason 0;
BA_ "SignalLongName" SG_ 626 RGNinactivereason "RGN Inactive Reason";

BA_ "GenSigSendType" SG_ 626 RGNPcnt 0;
BA_ "SignalLongName" SG_ 626 RGNPcnt "RGN percent";

BA_ "GenMsgSendType" BO_ 627 0;
BA_ "GenMsgStartDelayTime" BO_ 627 15;
BA_ "GenMsgCycleTime" BO_ 627 100;
BA_ "GenMsgILSupport" BO_ 627 1;
BA_ "VFrameFormat" BO_ 627 14;

BA_ "GenSigSendType" SG_ 627 BatVolV 0;
BA_ "SignalLongName" SG_ 627 BatVolV "Batttery Voltage Validty";

BA_ "GenSigSendType" SG_ 627 BatVol 0;
BA_ "SignalLongName" SG_ 627 BatVol "Batttery Voltage";

BA_ "GenSigSendType" SG_ 627 FuelModeFdbk 0;
BA_ "SignalLongName" SG_ 627 FuelModeFdbk "FuelModeFeedBack";

BA_ "GenSigSendType" SG_ 627 EnStrtactFdbk_V2L 0;
BA_ "SignalLongName" SG_ 627 EnStrtactFdbk_V2L "Engine Start Active Feedback_V2L";

BA_ "GenMsgSendType" BO_ 632 0;
BA_ "GenMsgStartDelayTime" BO_ 632 20;
BA_ "GenMsgCycleTime" BO_ 632 100;
BA_ "GenMsgILSupport" BO_ 632 1;
BA_ "VFrameFormat" BO_ 632 14;

BA_ "GenSigSendType" SG_ 632 Sootmass_Reset 0;
BA_ "SignalLongName" SG_ 632 Sootmass_Reset "Sootmass_Reset";

BA_ "GenSigSendType" SG_ 632 Sootmass_max 0;
BA_ "SignalLongName" SG_ 632 Sootmass_max "Sootmass_max";

BA_ "GenSigSendType" SG_ 632 Sootmass_RGN 0;
BA_ "SignalLongName" SG_ 632 Sootmass_RGN "Sootmass_RGN";

BA_ "GenSigSendType" SG_ 632 Sootmass 0;
BA_ "SignalLongName" SG_ 632 Sootmass "Sootmass";

BA_ "GenMsgSendType" BO_ 646 0;
BA_ "GenMsgStartDelayTime" BO_ 646 20;
BA_ "GenMsgCycleTime" BO_ 646 100;
BA_ "GenMsgILSupport" BO_ 646 1;
BA_ "VFrameFormat" BO_ 646 14;

BA_ "GenSigSendType" SG_ 646 FICMShowAVMReq 0;
BA_ "SignalLongName" SG_ 646 FICMShowAVMReq "FICM Show AVM Request";

BA_ "GenSigSendType" SG_ 646 FICMShowAPAReq 0;
BA_ "SignalLongName" SG_ 646 FICMShowAPAReq "FICM Show APA Request";

BA_ "GenSigSendType" SG_ 646 AVMXcoordinate 0;
BA_ "SignalLongName" SG_ 646 AVMXcoordinate "AVM X coordinate";

BA_ "GenSigSendType" SG_ 646 AVMYcoordinate 0;
BA_ "SignalLongName" SG_ 646 AVMYcoordinate "AVM Y coordinate";

BA_ "GenSigSendType" SG_ 646 FICMAVMSts 0;
BA_ "SignalLongName" SG_ 646 FICMAVMSts "FICM Around View Monitor Status";

BA_ "GenSigSendType" SG_ 646 AVMTouchEvtTyp 0;
BA_ "SignalLongName" SG_ 646 AVMTouchEvtTyp "AVM Touch Event Type";
BA_ "GenSigStartValue" SG_ 646 AVMTouchEvtTyp 1;

BA_ "GenMsgSendType" BO_ 676 0;
BA_ "GenMsgStartDelayTime" BO_ 676 10;
BA_ "GenMsgCycleTime" BO_ 676 100;
BA_ "GenMsgILSupport" BO_ 676 1;
BA_ "VFrameFormat" BO_ 676 14;

BA_ "GenSigSendType" SG_ 676 OtsdAirTemCrVal 0;
BA_ "SignalLongName" SG_ 676 OtsdAirTemCrVal "Outside Air Temperature Corrected Value";

BA_ "GenSigSendType" SG_ 676 OtsdAirTemCrValV 0;
BA_ "SignalLongName" SG_ 676 OtsdAirTemCrValV "Outside Air Temperature Corrected Value Validity";

BA_ "GenMsgSendType" BO_ 677 0;
BA_ "GenMsgStartDelayTime" BO_ 677 10;
BA_ "GenMsgCycleTime" BO_ 677 100;
BA_ "GenMsgILSupport" BO_ 677 1;
BA_ "VFrameFormat" BO_ 677 14;

BA_ "GenSigSendType" SG_ 677 HVACFrontAirVolume 0;
BA_ "SignalLongName" SG_ 677 HVACFrontAirVolume "HVAC Front Air Volume level";

BA_ "GenSigSendType" SG_ 677 HVACFrontMode 0;
BA_ "SignalLongName" SG_ 677 HVACFrontMode "HVAC Front Air Mode";

BA_ "GenSigSendType" SG_ 677 HVACLeftSetTemperature 0;
BA_ "SignalLongName" SG_ 677 HVACLeftSetTemperature "HVAC Left Set Temperature";

BA_ "GenSigSendType" SG_ 677 HVACRightSetTemperature 0;
BA_ "SignalLongName" SG_ 677 HVACRightSetTemperature "HVACRightSetTemperature";

BA_ "GenSigSendType" SG_ 677 HVACInCarTermperature 0;
BA_ "SignalLongName" SG_ 677 HVACInCarTermperature "HVAC InCar Termperature";

BA_ "GenSigSendType" SG_ 677 HVACCycleMode 0;
BA_ "SignalLongName" SG_ 677 HVACCycleMode "HVAC Cycle Mode";

BA_ "GenSigSendType" SG_ 677 HVACFrontDefrostStatus 0;
BA_ "SignalLongName" SG_ 677 HVACFrontDefrostStatus "HVAC Front Defrost Status";

BA_ "GenSigSendType" SG_ 677 HVACRearDefrostStatus 0;
BA_ "SignalLongName" SG_ 677 HVACRearDefrostStatus "HVAC Rear Defrost Status";

BA_ "GenSigSendType" SG_ 677 HVACAutoIndicationStatus 0;
BA_ "SignalLongName" SG_ 677 HVACAutoIndicationStatus "HVAC Auto Indication Status";

BA_ "GenSigSendType" SG_ 677 HVACFrontPowerStatus 0;
BA_ "SignalLongName" SG_ 677 HVACFrontPowerStatus "HVAC Front Power Status";

BA_ "GenSigSendType" SG_ 677 HVACOnRequestIndication 0;
BA_ "SignalLongName" SG_ 677 HVACOnRequestIndication "HVAC AC On Request Indication";

BA_ "GenSigSendType" SG_ 677 HVACSYNCDspCmd 0;
BA_ "SignalLongName" SG_ 677 HVACSYNCDspCmd "HVAC SYNC Dsplay Command";

BA_ "GenSigSendType" SG_ 677 PTC_WRK_LEVEL 0;
BA_ "SignalLongName" SG_ 677 PTC_WRK_LEVEL "PTC_WRK_LEVEL";

BA_ "GenSigSendType" SG_ 677 HVACAtDefSts 0;
BA_ "SignalLongName" SG_ 677 HVACAtDefSts "HVAC Auto Defrost Status";

BA_ "GenSigSendType" SG_ 677 HVACQuietSetStatus 0;
BA_ "SignalLongName" SG_ 677 HVACQuietSetStatus "HVAC Quiet Set Status";

BA_ "GenSigSendType" SG_ 677 HVACFrontACMaxStatus 0;
BA_ "SignalLongName" SG_ 677 HVACFrontACMaxStatus "HVAC Front AC Max Status";

BA_ "GenSigSendType" SG_ 677 InsdAirPrtclMtrCDC 0;
BA_ "SignalLongName" SG_ 677 InsdAirPrtclMtrCDC "Inside Air Particulate Matter Concentration Display Command";

BA_ "GenMsgSendType" BO_ 679 0;
BA_ "GenMsgStartDelayTime" BO_ 679 10;
BA_ "GenMsgCycleTime" BO_ 679 100;
BA_ "GenMsgILSupport" BO_ 679 1;
BA_ "VFrameFormat" BO_ 679 14;

BA_ "GenSigSendType" SG_ 679 HVACRearAirVolume 0;
BA_ "SignalLongName" SG_ 679 HVACRearAirVolume "HVACRearAirVolume";

BA_ "GenSigSendType" SG_ 679 HVACRearMode 0;
BA_ "SignalLongName" SG_ 679 HVACRearMode "HVACRearMode";

BA_ "GenSigSendType" SG_ 679 HVACRearSetTemperature 0;
BA_ "SignalLongName" SG_ 679 HVACRearSetTemperature "HVACRearSetTemperature";

BA_ "GenSigSendType" SG_ 679 HVACRearPowerStatus 0;
BA_ "SignalLongName" SG_ 679 HVACRearPowerStatus "HVAC Rear Power Status";

BA_ "GenSigSendType" SG_ 679 HVACRearAutoStatus 0;
BA_ "SignalLongName" SG_ 679 HVACRearAutoStatus "HVACRearAutoStatus";

BA_ "GenSigSendType" SG_ 679 HVACRearAirVolume2 0;
BA_ "SignalLongName" SG_ 679 HVACRearAirVolume2 "HVACRearAirVolume2";

BA_ "GenSigSendType" SG_ 679 HVACOnRequestIndication_R 0;
BA_ "SignalLongName" SG_ 679 HVACOnRequestIndication_R "HVACOnRequest Indication_R";

BA_ "GenMsgSendType" BO_ 680 0;
BA_ "GenMsgStartDelayTime" BO_ 680 20;
BA_ "GenMsgCycleTime" BO_ 680 100;
BA_ "GenMsgILSupport" BO_ 680 1;
BA_ "VFrameFormat" BO_ 680 14;

BA_ "GenSigSendType" SG_ 680 LeftArVetLRSwingSts 0;
BA_ "SignalLongName" SG_ 680 LeftArVetLRSwingSts "Left Air Vent Left Right Swing Status";

BA_ "GenSigSendType" SG_ 680 LeftMidArVetLRSwingSts 0;
BA_ "SignalLongName" SG_ 680 LeftMidArVetLRSwingSts "Left Middle Air Vent Left Right Swing Status";

BA_ "GenSigSendType" SG_ 680 RightMidArVetLRSwingSts 0;
BA_ "SignalLongName" SG_ 680 RightMidArVetLRSwingSts "Right Middle Air Vent Left Right Swing Status";

BA_ "GenSigSendType" SG_ 680 RightArVetSwingLRSts 0;
BA_ "SignalLongName" SG_ 680 RightArVetSwingLRSts "Right Air Vent Left Right Swing Status";

BA_ "GenSigSendType" SG_ 680 LeftArVetUDSwingSts 0;
BA_ "SignalLongName" SG_ 680 LeftArVetUDSwingSts "Left Air Vent Up Down Swing Status";

BA_ "GenSigSendType" SG_ 680 LeftMidArVetUDSwingSts 0;
BA_ "SignalLongName" SG_ 680 LeftMidArVetUDSwingSts "Left Middle Air Vent Up Down Swing Status";

BA_ "GenSigSendType" SG_ 680 RightMidArVetUDSwingSts 0;
BA_ "SignalLongName" SG_ 680 RightMidArVetUDSwingSts "Right Middle Air Vent Up Down Swing Status";

BA_ "GenSigSendType" SG_ 680 RightArVetSwingUDSts 0;
BA_ "SignalLongName" SG_ 680 RightArVetSwingUDSts "Right Air Vent Up Down Swing Status";

BA_ "GenSigSendType" SG_ 680 LeftArVetFosSts 0;
BA_ "SignalLongName" SG_ 680 LeftArVetFosSts "Left Air Vent Focus Status";

BA_ "GenSigSendType" SG_ 680 RightArVetFosSts 0;
BA_ "SignalLongName" SG_ 680 RightArVetFosSts "Right Air Vent Focus Status";

BA_ "GenSigSendType" SG_ 680 LeftArVetDistribSts 0;
BA_ "SignalLongName" SG_ 680 LeftArVetDistribSts "Left Air Vent Distribute Status";

BA_ "GenSigSendType" SG_ 680 RightArVetDistribSts 0;
BA_ "SignalLongName" SG_ 680 RightArVetDistribSts "Right Air Vent Distribute Status";

BA_ "GenSigSendType" SG_ 680 LeftArVetSweepSts 0;
BA_ "SignalLongName" SG_ 680 LeftArVetSweepSts "Left Air Vent Sweep Status";

BA_ "GenSigSendType" SG_ 680 RightArVetSweepSts 0;
BA_ "SignalLongName" SG_ 680 RightArVetSweepSts "Right Air Vent Sweep Status";

BA_ "GenSigSendType" SG_ 680 LeftArVetOnOffSts 0;
BA_ "SignalLongName" SG_ 680 LeftArVetOnOffSts "Left Air Vent On Off Status";

BA_ "GenSigSendType" SG_ 680 RightArVetOnOffSts 0;
BA_ "SignalLongName" SG_ 680 RightArVetOnOffSts "Right Air Vent On Off Status";

BA_ "GenSigSendType" SG_ 680 HVACLeavVentSts 0;
BA_ "SignalLongName" SG_ 680 HVACLeavVentSts "HVAC Leave Vent Status";

BA_ "GenMsgSendType" BO_ 681 0;
BA_ "GenMsgStartDelayTime" BO_ 681 20;
BA_ "GenMsgCycleTime" BO_ 681 100;
BA_ "GenMsgILSupport" BO_ 681 1;
BA_ "VFrameFormat" BO_ 681 14;

BA_ "GenSigSendType" SG_ 681 HVACBloLimtSetSts 0;
BA_ "SignalLongName" SG_ 681 HVACBloLimtSetSts "HVAC Blower Limit Set Status";

BA_ "GenSigSendType" SG_ 681 HVACAtCylTimSts 0;
BA_ "SignalLongName" SG_ 681 HVACAtCylTimSts "HVAC Auto Cycle Time Status";

BA_ "GenSigSendType" SG_ 681 HVACAirFltrLife 0;
BA_ "SignalLongName" SG_ 681 HVACAirFltrLife "HVAC Air Filter Life";
BA_ "GenSigTimeoutValue" SG_ 681 HVACAirFltrLife 600;
BA_ "GenSigStartValue" SG_ 681 HVACAirFltrLife 600;

BA_ "GenSigSendType" SG_ 681 HVACAIUOnOffDspCmd 0;
BA_ "SignalLongName" SG_ 681 HVACAIUOnOffDspCmd "HVAC AIU OnOff Display Command";

BA_ "GenMsgSendType" BO_ 682 0;
BA_ "GenMsgStartDelayTime" BO_ 682 20;
BA_ "GenMsgCycleTime" BO_ 682 100;
BA_ "GenMsgILSupport" BO_ 682 1;
BA_ "VFrameFormat" BO_ 682 14;

BA_ "GenSigSendType" SG_ 682 OtsdAirTemRawData 0;
BA_ "SignalLongName" SG_ 682 OtsdAirTemRawData "Outside Air Temperature RAW Date";

BA_ "GenMsgSendType" BO_ 727 0;
BA_ "GenMsgStartDelayTime" BO_ 727 30;
BA_ "GenMsgCycleTime" BO_ 727 100;
BA_ "GenMsgILSupport" BO_ 727 1;
BA_ "GenMsgDelayTime" BO_ 727 20;
BA_ "VFrameFormat" BO_ 727 14;

BA_ "GenSigSendType" SG_ 727 AllMuteFdbk 0;
BA_ "SignalLongName" SG_ 727 AllMuteFdbk "All_Mute_Feedback";
BA_ "GenSigStartValue" SG_ 727 AllMuteFdbk 1;

BA_ "GenSigSendType" SG_ 727 MdaMuteFdbk 0;
BA_ "SignalLongName" SG_ 727 MdaMuteFdbk "Media_Mute_Feedback";

BA_ "GenSigSendType" SG_ 727 PhnMuteFdbk 0;
BA_ "SignalLongName" SG_ 727 PhnMuteFdbk "Phone_Mute_Feedback";

BA_ "GenSigSendType" SG_ 727 NaviMuteFdbk 0;
BA_ "SignalLongName" SG_ 727 NaviMuteFdbk "Navi_Mute_Feedback";

BA_ "GenSigSendType" SG_ 727 VcMuteFdbk 0;
BA_ "SignalLongName" SG_ 727 VcMuteFdbk "Voice_Mute_Feedback";

BA_ "GenSigSendType" SG_ 727 NotiMuteFdbk 0;
BA_ "SignalLongName" SG_ 727 NotiMuteFdbk "Notification_Mute_Feedback";

BA_ "GenSigSendType" SG_ 727 ChmMuteFdbk 0;
BA_ "SignalLongName" SG_ 727 ChmMuteFdbk "Chimes_Mute_Feedback";

BA_ "GenSigSendType" SG_ 727 ChmSndVolmStepFdbk 0;
BA_ "SignalLongName" SG_ 727 ChmSndVolmStepFdbk "Chime_Sound_Volume_Step_Feedback";
BA_ "GenSigStartValue" SG_ 727 ChmSndVolmStepFdbk 16;

BA_ "GenSigSendType" SG_ 727 NotiSndVolmStepFdbk 0;
BA_ "SignalLongName" SG_ 727 NotiSndVolmStepFdbk "Notification_Sound_Volume_Step_Feedback";
BA_ "GenSigStartValue" SG_ 727 NotiSndVolmStepFdbk 16;

BA_ "GenSigSendType" SG_ 727 NaviSndVolmStepFdbk 0;
BA_ "SignalLongName" SG_ 727 NaviSndVolmStepFdbk "Navigation_Sound_Volume_Step_Feedback";
BA_ "GenSigStartValue" SG_ 727 NaviSndVolmStepFdbk 16;

BA_ "GenSigSendType" SG_ 727 MdaSndVolmStepFdbk 0;
BA_ "SignalLongName" SG_ 727 MdaSndVolmStepFdbk "Media_Sound_Volume_Step_Feedback";
BA_ "GenSigStartValue" SG_ 727 MdaSndVolmStepFdbk 16;

BA_ "GenSigSendType" SG_ 727 PhnCallSndVolmStepFdbk 0;
BA_ "SignalLongName" SG_ 727 PhnCallSndVolmStepFdbk "Phone_Call_Sound_Volume_Step_Feedback";
BA_ "GenSigStartValue" SG_ 727 PhnCallSndVolmStepFdbk 16;

BA_ "GenSigSendType" SG_ 727 VcItatnSndVolmStepFdbk 0;
BA_ "SignalLongName" SG_ 727 VcItatnSndVolmStepFdbk "Voice_Interaction_Sound_Volume_Step_Feedback";
BA_ "GenSigStartValue" SG_ 727 VcItatnSndVolmStepFdbk 16;

BA_ "GenSigSendType" SG_ 727 FdrSetngFdbk 0;
BA_ "SignalLongName" SG_ 727 FdrSetngFdbk "Fader_Setting_Feedback";
BA_ "GenSigTimeoutValue" SG_ 727 FdrSetngFdbk 7;
BA_ "GenSigStartValue" SG_ 727 FdrSetngFdbk 7;

BA_ "GenMsgSendType" BO_ 728 0;
BA_ "GenMsgStartDelayTime" BO_ 728 30;
BA_ "GenMsgCycleTime" BO_ 728 100;
BA_ "GenMsgILSupport" BO_ 728 1;
BA_ "GenMsgDelayTime" BO_ 728 20;
BA_ "VFrameFormat" BO_ 728 14;

BA_ "GenSigSendType" SG_ 728 BalcSetngFdbk 0;
BA_ "SignalLongName" SG_ 728 BalcSetngFdbk "Balance_Setting_Feedback";
BA_ "GenSigTimeoutValue" SG_ 728 BalcSetngFdbk 7;
BA_ "GenSigStartValue" SG_ 728 BalcSetngFdbk 7;

BA_ "GenSigSendType" SG_ 728 AmbcSetngFdbk 0;
BA_ "SignalLongName" SG_ 728 AmbcSetngFdbk "Ambiance_Setting_Feedback";

BA_ "GenSigSendType" SG_ 728 ThreeDimnSndFldFdbk 0;
BA_ "SignalLongName" SG_ 728 ThreeDimnSndFldFdbk "Three_Dimensions_Sound_Field_Feedback";
BA_ "GenSigStartValue" SG_ 728 ThreeDimnSndFldFdbk 1;

BA_ "GenSigSendType" SG_ 728 SpdDpntAutocVolmFdbk 0;
BA_ "SignalLongName" SG_ 728 SpdDpntAutocVolmFdbk "Speed_Dependant_Automatic_Volume_Feedback";
BA_ "GenSigStartValue" SG_ 728 SpdDpntAutocVolmFdbk 2;

BA_ "GenSigSendType" SG_ 728 AMP_Temp_STS 0;
BA_ "SignalLongName" SG_ 728 AMP_Temp_STS "The_Value_Of_AMP_Temperature_Status";

BA_ "GenSigSendType" SG_ 728 CustzEqlzrPreSetFdbk 0;
BA_ "SignalLongName" SG_ 728 CustzEqlzrPreSetFdbk "Customize_Equalizer_Pre_Set_Feedback";

BA_ "GenSigSendType" SG_ 728 ChmOutSpkFdbk 0;
BA_ "SignalLongName" SG_ 728 ChmOutSpkFdbk "Chime_Output_Speaker_Feedback";
BA_ "GenSigTimeoutValue" SG_ 728 ChmOutSpkFdbk 33;
BA_ "GenSigStartValue" SG_ 728 ChmOutSpkFdbk 33;

BA_ "GenSigSendType" SG_ 728 AMPTurnOnRdyStsFdbk 0;
BA_ "SignalLongName" SG_ 728 AMPTurnOnRdyStsFdbk "Amplifier_Turn_On_Ready_Status_Feedback";

BA_ "GenSigSendType" SG_ 728 AMPPwrRdySts 0;
BA_ "SignalLongName" SG_ 728 AMPPwrRdySts "Amplifier_Power_Ready_Status_Feedback";

BA_ "GenSigSendType" SG_ 728 VirtualSbwfrOnOffReqFdbk 0;
BA_ "SignalLongName" SG_ 728 VirtualSbwfrOnOffReqFdbk "Virtual_Subwoofer_On_Off_Request_Feedback";

BA_ "GenSigSendType" SG_ 728 LdnsSetngFdbk 0;
BA_ "SignalLongName" SG_ 728 LdnsSetngFdbk "Loudness_Setting_Feedback";

BA_ "GenSigSendType" SG_ 728 ANCFunSwFdbk 0;
BA_ "SignalLongName" SG_ 728 ANCFunSwFdbk "ANC_function_Switchh_Feedback";

BA_ "GenSigSendType" SG_ 728 AMP_DTC_INFO 0;
BA_ "SignalLongName" SG_ 728 AMP_DTC_INFO "Amplifier_Output_Channel_DTC_Information";

BA_ "GenSigSendType" SG_ 728 ANCWorkInfoFdbk 0;
BA_ "SignalLongName" SG_ 728 ANCWorkInfoFdbk "ANC_Working_Information_feedback";

BA_ "GenMsgSendType" BO_ 729 0;
BA_ "GenMsgStartDelayTime" BO_ 729 30;
BA_ "GenMsgCycleTime" BO_ 729 100;
BA_ "GenMsgILSupport" BO_ 729 1;
BA_ "GenMsgDelayTime" BO_ 729 20;
BA_ "VFrameFormat" BO_ 729 14;

BA_ "GenSigSendType" SG_ 729 AMPVersionInfo 0;
BA_ "SignalLongName" SG_ 729 AMPVersionInfo "Software_Version_Information";

BA_ "GenSigSendType" SG_ 729 ANCFWVersion 0;
BA_ "SignalLongName" SG_ 729 ANCFWVersion "ANC_Firmware_Version_Information";

BA_ "GenSigSendType" SG_ 729 RngSndVolmStepFdbk 0;
BA_ "SignalLongName" SG_ 729 RngSndVolmStepFdbk "Ring_Sound_Volume_Step_Feedback";
BA_ "GenSigTimeoutValue" SG_ 729 RngSndVolmStepFdbk 16;
BA_ "GenSigStartValue" SG_ 729 RngSndVolmStepFdbk 16;

BA_ "GenMsgSendType" BO_ 730 0;
BA_ "GenMsgStartDelayTime" BO_ 730 30;
BA_ "GenMsgCycleTime" BO_ 730 100;
BA_ "GenMsgILSupport" BO_ 730 1;
BA_ "GenMsgCycleTimeFast" BO_ 730 40;
BA_ "GenMsgNrOfRepetition" BO_ 730 3;
BA_ "GenMsgDelayTime" BO_ 730 20;
BA_ "VFrameFormat" BO_ 730 14;

BA_ "GenSigSendType" SG_ 730 AMPSoundDB 2;
BA_ "SignalLongName" SG_ 730 AMPSoundDB "AMP_Sound_Debugging";

BA_ "GenMsgSendType" BO_ 731 0;
BA_ "GenMsgStartDelayTime" BO_ 731 30;
BA_ "GenMsgCycleTime" BO_ 731 100;
BA_ "GenMsgILSupport" BO_ 731 1;
BA_ "GenMsgDelayTime" BO_ 731 20;
BA_ "VFrameFormat" BO_ 731 14;

BA_ "GenSigSendType" SG_ 731 CustzEqlzrBand1Dsp 0;
BA_ "SignalLongName" SG_ 731 CustzEqlzrBand1Dsp "Customize_Equalizer_Band_1_Display";
BA_ "GenSigTimeoutValue" SG_ 731 CustzEqlzrBand1Dsp 12;
BA_ "GenSigStartValue" SG_ 731 CustzEqlzrBand1Dsp 12;

BA_ "GenSigSendType" SG_ 731 CustzEqlzrBand2Dsp 0;
BA_ "SignalLongName" SG_ 731 CustzEqlzrBand2Dsp "Customize_Equalizer_Band_2_Display";
BA_ "GenSigTimeoutValue" SG_ 731 CustzEqlzrBand2Dsp 12;
BA_ "GenSigStartValue" SG_ 731 CustzEqlzrBand2Dsp 12;

BA_ "GenSigSendType" SG_ 731 CustzEqlzrBand3Dsp 0;
BA_ "SignalLongName" SG_ 731 CustzEqlzrBand3Dsp "Customize_Equalizer_Band_3_Display";
BA_ "GenSigTimeoutValue" SG_ 731 CustzEqlzrBand3Dsp 12;
BA_ "GenSigStartValue" SG_ 731 CustzEqlzrBand3Dsp 12;

BA_ "GenSigSendType" SG_ 731 CustzEqlzrBand4Dsp 0;
BA_ "SignalLongName" SG_ 731 CustzEqlzrBand4Dsp "Customize_Equalizer_Band_4_Display";
BA_ "GenSigTimeoutValue" SG_ 731 CustzEqlzrBand4Dsp 12;
BA_ "GenSigStartValue" SG_ 731 CustzEqlzrBand4Dsp 12;

BA_ "GenSigSendType" SG_ 731 CustzEqlzrBand5Dsp 0;
BA_ "SignalLongName" SG_ 731 CustzEqlzrBand5Dsp "Customize_Equalizer_Band_5_Display";
BA_ "GenSigTimeoutValue" SG_ 731 CustzEqlzrBand5Dsp 12;
BA_ "GenSigStartValue" SG_ 731 CustzEqlzrBand5Dsp 12;

BA_ "GenSigSendType" SG_ 731 CustzEqlzrBand6Dsp 0;
BA_ "SignalLongName" SG_ 731 CustzEqlzrBand6Dsp "Customize_Equalizer_Band_6_Display";
BA_ "GenSigTimeoutValue" SG_ 731 CustzEqlzrBand6Dsp 12;
BA_ "GenSigStartValue" SG_ 731 CustzEqlzrBand6Dsp 12;

BA_ "GenSigSendType" SG_ 731 CustzEqlzrBand7Dsp 0;
BA_ "SignalLongName" SG_ 731 CustzEqlzrBand7Dsp "Customize_Equalizer_Band_7_Display";
BA_ "GenSigTimeoutValue" SG_ 731 CustzEqlzrBand7Dsp 12;
BA_ "GenSigStartValue" SG_ 731 CustzEqlzrBand7Dsp 12;

BA_ "GenSigSendType" SG_ 731 CustzEqlzrBand8Dsp 0;
BA_ "SignalLongName" SG_ 731 CustzEqlzrBand8Dsp "Customize_Equalizer_Band_8_Display";
BA_ "GenSigTimeoutValue" SG_ 731 CustzEqlzrBand8Dsp 12;
BA_ "GenSigStartValue" SG_ 731 CustzEqlzrBand8Dsp 12;

BA_ "GenMsgSendType" BO_ 732 0;
BA_ "GenMsgStartDelayTime" BO_ 732 30;
BA_ "GenMsgCycleTime" BO_ 732 100;
BA_ "GenMsgILSupport" BO_ 732 1;
BA_ "GenMsgDelayTime" BO_ 732 20;
BA_ "VFrameFormat" BO_ 732 14;

BA_ "GenSigSendType" SG_ 732 AllMuteReq 0;
BA_ "SignalLongName" SG_ 732 AllMuteReq "All_Mute_Request";
BA_ "GenSigStartValue" SG_ 732 AllMuteReq 1;

BA_ "GenSigSendType" SG_ 732 MdaMuteReq 0;
BA_ "SignalLongName" SG_ 732 MdaMuteReq "Media_Mute_Request";

BA_ "GenSigSendType" SG_ 732 PhnMuteReq 0;
BA_ "SignalLongName" SG_ 732 PhnMuteReq "Phone_Mute_Request";

BA_ "GenSigSendType" SG_ 732 NaviMuteReq 0;
BA_ "SignalLongName" SG_ 732 NaviMuteReq "Navi_Mute_Request";

BA_ "GenSigSendType" SG_ 732 VcMuteReq 0;
BA_ "SignalLongName" SG_ 732 VcMuteReq "Voice_Mute_Request";

BA_ "GenSigSendType" SG_ 732 NotiMuteReq 0;
BA_ "SignalLongName" SG_ 732 NotiMuteReq "Notification_Mute_Request";

BA_ "GenSigSendType" SG_ 732 ChmMuteReq 0;
BA_ "SignalLongName" SG_ 732 ChmMuteReq "Chimes_Mute_Request";

BA_ "GenSigSendType" SG_ 732 FICMAMPStatus 0;
BA_ "SignalLongName" SG_ 732 FICMAMPStatus "FICMAMPStatus";

BA_ "GenSigSendType" SG_ 732 ChmSndVolmStepReqV 0;
BA_ "SignalLongName" SG_ 732 ChmSndVolmStepReqV "Chime_Sound_Volume_Step_Request_Validity";
BA_ "GenSigStartValue" SG_ 732 ChmSndVolmStepReqV 1;

BA_ "GenSigSendType" SG_ 732 ChmSndVolmStepReq 0;
BA_ "SignalLongName" SG_ 732 ChmSndVolmStepReq "Chime_Sound_Volume_Step_Request";
BA_ "GenSigStartValue" SG_ 732 ChmSndVolmStepReq 16;

BA_ "GenSigSendType" SG_ 732 FICMAvlblSts 0;
BA_ "SignalLongName" SG_ 732 FICMAvlblSts "FICM Available Status";

BA_ "GenSigSendType" SG_ 732 NotiSndVolmStepReqV 0;
BA_ "SignalLongName" SG_ 732 NotiSndVolmStepReqV "Notification_Sound_Volume_Step_Request_Validity";
BA_ "GenSigStartValue" SG_ 732 NotiSndVolmStepReqV 1;

BA_ "GenSigSendType" SG_ 732 NotiSndVolmStepReq 0;
BA_ "SignalLongName" SG_ 732 NotiSndVolmStepReq "Notification_Sound_Volume_Step_Request";
BA_ "GenSigStartValue" SG_ 732 NotiSndVolmStepReq 16;

BA_ "GenSigSendType" SG_ 732 LVDSMdaReady 0;
BA_ "SignalLongName" SG_ 732 LVDSMdaReady "LVDS Media Ready";

BA_ "GenSigSendType" SG_ 732 MdaSndVolmStepReqV 0;
BA_ "SignalLongName" SG_ 732 MdaSndVolmStepReqV "Media_Sound_Volume_Step_Request_Validity";
BA_ "GenSigStartValue" SG_ 732 MdaSndVolmStepReqV 1;

BA_ "GenSigSendType" SG_ 732 MdaSndVolmStepReq 0;
BA_ "SignalLongName" SG_ 732 MdaSndVolmStepReq "Media_Sound_Volume_Step_Request";
BA_ "GenSigStartValue" SG_ 732 MdaSndVolmStepReq 16;

BA_ "GenSigSendType" SG_ 732 LVDSNavReady 0;
BA_ "SignalLongName" SG_ 732 LVDSNavReady "LVDS Navigation Ready";

BA_ "GenSigSendType" SG_ 732 NaviSndVolmStepReqV 0;
BA_ "SignalLongName" SG_ 732 NaviSndVolmStepReqV "Navigation_Sound_Volume_Step_Request_Validity";
BA_ "GenSigStartValue" SG_ 732 NaviSndVolmStepReqV 1;

BA_ "GenSigSendType" SG_ 732 NaviSndVolmStepReq 0;
BA_ "SignalLongName" SG_ 732 NaviSndVolmStepReq "Navigation_Sound_Volume_Step_Request";
BA_ "GenSigStartValue" SG_ 732 NaviSndVolmStepReq 16;

BA_ "GenSigSendType" SG_ 732 LVDSPhReady 0;
BA_ "SignalLongName" SG_ 732 LVDSPhReady "LVDS Phone Ready";

BA_ "GenSigSendType" SG_ 732 PhnCallSndVolmStepReqV 0;
BA_ "SignalLongName" SG_ 732 PhnCallSndVolmStepReqV "Phone_Call_Sound_Volume_Step_Request_Validity";
BA_ "GenSigStartValue" SG_ 732 PhnCallSndVolmStepReqV 1;

BA_ "GenSigSendType" SG_ 732 PhnCallSndVolmStepReq 0;
BA_ "SignalLongName" SG_ 732 PhnCallSndVolmStepReq "Phone_Call_Sound_Volume_Step_Request";
BA_ "GenSigStartValue" SG_ 732 PhnCallSndVolmStepReq 16;

BA_ "GenSigSendType" SG_ 732 VcItatnSndVolmStepReqV 0;
BA_ "SignalLongName" SG_ 732 VcItatnSndVolmStepReqV "Voice_Interaction_Sound_Volume_Step_Request_Validity";
BA_ "GenSigStartValue" SG_ 732 VcItatnSndVolmStepReqV 1;

BA_ "GenSigSendType" SG_ 732 VcItatnSndVolmStepReq 0;
BA_ "SignalLongName" SG_ 732 VcItatnSndVolmStepReq "Voice_Interaction_Sound_Volume_Step_Request";
BA_ "GenSigStartValue" SG_ 732 VcItatnSndVolmStepReq 16;

BA_ "GenSigSendType" SG_ 732 FdrSetngReqV 0;
BA_ "SignalLongName" SG_ 732 FdrSetngReqV "Fader_Setting_Request_Validity";
BA_ "GenSigStartValue" SG_ 732 FdrSetngReqV 1;

BA_ "GenSigSendType" SG_ 732 FdrSetngReq 0;
BA_ "SignalLongName" SG_ 732 FdrSetngReq "Fader_Setting_Request";
BA_ "GenSigTimeoutValue" SG_ 732 FdrSetngReq 7;
BA_ "GenSigStartValue" SG_ 732 FdrSetngReq 7;

BA_ "GenMsgSendType" BO_ 733 0;
BA_ "GenMsgStartDelayTime" BO_ 733 30;
BA_ "GenMsgCycleTime" BO_ 733 100;
BA_ "GenMsgILSupport" BO_ 733 1;
BA_ "GenMsgDelayTime" BO_ 733 20;
BA_ "VFrameFormat" BO_ 733 14;

BA_ "GenSigSendType" SG_ 733 BalcSetngReqV 0;
BA_ "SignalLongName" SG_ 733 BalcSetngReqV "Balance_Setting_Request_Validity";
BA_ "GenSigStartValue" SG_ 733 BalcSetngReqV 1;

BA_ "GenSigSendType" SG_ 733 BalcSetngReq 0;
BA_ "SignalLongName" SG_ 733 BalcSetngReq "Balance_Setting_Request";
BA_ "GenSigTimeoutValue" SG_ 733 BalcSetngReq 7;
BA_ "GenSigStartValue" SG_ 733 BalcSetngReq 7;

BA_ "GenSigSendType" SG_ 733 AmbcSetngReqV 0;
BA_ "SignalLongName" SG_ 733 AmbcSetngReqV "Ambiance_Setting_Request_Validity";
BA_ "GenSigStartValue" SG_ 733 AmbcSetngReqV 1;

BA_ "GenSigSendType" SG_ 733 AmbcSetngReq 0;
BA_ "SignalLongName" SG_ 733 AmbcSetngReq "Ambiance_Setting_Request";

BA_ "GenSigSendType" SG_ 733 ThreeDimnSndFldSetngReqV 0;
BA_ "SignalLongName" SG_ 733 ThreeDimnSndFldSetngReqV "Three_Dimension_Sound_Field_Setting_Request_Validity";
BA_ "GenSigStartValue" SG_ 733 ThreeDimnSndFldSetngReqV 1;

BA_ "GenSigSendType" SG_ 733 ThreeDimnSndFldSetngReq 0;
BA_ "SignalLongName" SG_ 733 ThreeDimnSndFldSetngReq "Three_Dimension_Sound_Field_Setting_Request";
BA_ "GenSigStartValue" SG_ 733 ThreeDimnSndFldSetngReq 1;

BA_ "GenSigSendType" SG_ 733 SpdDpntAutocVolmReqV 0;
BA_ "SignalLongName" SG_ 733 SpdDpntAutocVolmReqV "Speed_Dependant_Automatic_Volume_Request_Validity";
BA_ "GenSigStartValue" SG_ 733 SpdDpntAutocVolmReqV 1;

BA_ "GenSigSendType" SG_ 733 SpdDpntAutocVolmReq 0;
BA_ "SignalLongName" SG_ 733 SpdDpntAutocVolmReq "Speed_Dependant_Automatic_Volume_Request";
BA_ "GenSigStartValue" SG_ 733 SpdDpntAutocVolmReq 2;

BA_ "GenSigSendType" SG_ 733 CustzEqlzrV 0;
BA_ "SignalLongName" SG_ 733 CustzEqlzrV "Customize_Equalizer_Validity";
BA_ "GenSigStartValue" SG_ 733 CustzEqlzrV 1;

BA_ "GenSigSendType" SG_ 733 CustzEqlzrPreSet 0;
BA_ "SignalLongName" SG_ 733 CustzEqlzrPreSet "Customize_Equalizer_Pre_Set";

BA_ "GenSigSendType" SG_ 733 ICMTurnOnRdyStsX 0;
BA_ "SignalLongName" SG_ 733 ICMTurnOnRdyStsX "Intelligent_Cockpit_Module_Turn_On_Ready_StatusX";

BA_ "GenSigSendType" SG_ 733 VirtualSbwfrOnOffReq 0;
BA_ "SignalLongName" SG_ 733 VirtualSbwfrOnOffReq "Virtual_Subwoofer_On_Off_Request";

BA_ "GenSigSendType" SG_ 733 LdnsSetngSoftSw 0;
BA_ "SignalLongName" SG_ 733 LdnsSetngSoftSw "Loudness_Setting_Soft_Swtich";

BA_ "GenSigSendType" SG_ 733 TelphoComLoctn 0;
BA_ "SignalLongName" SG_ 733 TelphoComLoctn "Telephone_Communication_Location";

BA_ "GenSigSendType" SG_ 733 ChmOutSpk 0;
BA_ "SignalLongName" SG_ 733 ChmOutSpk "chime_output_speaker";
BA_ "GenSigTimeoutValue" SG_ 733 ChmOutSpk 33;
BA_ "GenSigStartValue" SG_ 733 ChmOutSpk 33;

BA_ "GenSigSendType" SG_ 733 ANCFunSwV 0;
BA_ "SignalLongName" SG_ 733 ANCFunSwV "ANC function Switch Validity";

BA_ "GenSigSendType" SG_ 733 ANCFunSw 0;
BA_ "SignalLongName" SG_ 733 ANCFunSw "ANC function Switch";

BA_ "GenSigSendType" SG_ 733 VcItatnSndLoctn 0;
BA_ "SignalLongName" SG_ 733 VcItatnSndLoctn "Voice_Interaction_Sound_Location";

BA_ "GenSigSendType" SG_ 733 FICM_MusicPlaybackSts 0;
BA_ "SignalLongName" SG_ 733 FICM_MusicPlaybackSts "FICM Music Playback Status";

BA_ "GenSigSendType" SG_ 733 FICM_MdSts 0;
BA_ "SignalLongName" SG_ 733 FICM_MdSts "FICM Mode Status";

BA_ "GenMsgSendType" BO_ 734 0;
BA_ "GenMsgStartDelayTime" BO_ 734 30;
BA_ "GenMsgCycleTime" BO_ 734 100;
BA_ "GenMsgILSupport" BO_ 734 1;
BA_ "GenMsgCycleTimeFast" BO_ 734 40;
BA_ "GenMsgNrOfRepetition" BO_ 734 3;
BA_ "GenMsgDelayTime" BO_ 734 20;
BA_ "VFrameFormat" BO_ 734 14;

BA_ "GenSigSendType" SG_ 734 AMPSoundFdbk 2;
BA_ "SignalLongName" SG_ 734 AMPSoundFdbk "AMP_Sound_Debugging_Feedback";

BA_ "GenMsgSendType" BO_ 735 0;
BA_ "GenMsgStartDelayTime" BO_ 735 30;
BA_ "GenMsgCycleTime" BO_ 735 100;
BA_ "GenMsgILSupport" BO_ 735 1;
BA_ "GenMsgDelayTime" BO_ 735 20;
BA_ "VFrameFormat" BO_ 735 14;

BA_ "GenSigSendType" SG_ 735 CustzEqlzrBand1 0;
BA_ "SignalLongName" SG_ 735 CustzEqlzrBand1 "Customize_Equalizer_Band_1";
BA_ "GenSigTimeoutValue" SG_ 735 CustzEqlzrBand1 12;
BA_ "GenSigStartValue" SG_ 735 CustzEqlzrBand1 12;

BA_ "GenSigSendType" SG_ 735 CustzEqlzrBand2 0;
BA_ "SignalLongName" SG_ 735 CustzEqlzrBand2 "Customize_Equalizer_Band_2";
BA_ "GenSigTimeoutValue" SG_ 735 CustzEqlzrBand2 12;
BA_ "GenSigStartValue" SG_ 735 CustzEqlzrBand2 12;

BA_ "GenSigSendType" SG_ 735 CustzEqlzrBand3 0;
BA_ "SignalLongName" SG_ 735 CustzEqlzrBand3 "Customize_Equalizer_Band_3";
BA_ "GenSigTimeoutValue" SG_ 735 CustzEqlzrBand3 12;
BA_ "GenSigStartValue" SG_ 735 CustzEqlzrBand3 12;

BA_ "GenSigSendType" SG_ 735 CustzEqlzrBand4 0;
BA_ "SignalLongName" SG_ 735 CustzEqlzrBand4 "Customize_Equalizer_Band_4";
BA_ "GenSigTimeoutValue" SG_ 735 CustzEqlzrBand4 12;
BA_ "GenSigStartValue" SG_ 735 CustzEqlzrBand4 12;

BA_ "GenSigSendType" SG_ 735 CustzEqlzrBand5 0;
BA_ "SignalLongName" SG_ 735 CustzEqlzrBand5 "Customize_Equalizer_Band_5";
BA_ "GenSigTimeoutValue" SG_ 735 CustzEqlzrBand5 12;
BA_ "GenSigStartValue" SG_ 735 CustzEqlzrBand5 12;

BA_ "GenSigSendType" SG_ 735 CustzEqlzrBand6 0;
BA_ "SignalLongName" SG_ 735 CustzEqlzrBand6 "Customize_Equalizer_Band_6";
BA_ "GenSigTimeoutValue" SG_ 735 CustzEqlzrBand6 12;
BA_ "GenSigStartValue" SG_ 735 CustzEqlzrBand6 12;

BA_ "GenSigSendType" SG_ 735 CustzEqlzrBand7 0;
BA_ "SignalLongName" SG_ 735 CustzEqlzrBand7 "Customize_Equalizer_Band_7";
BA_ "GenSigTimeoutValue" SG_ 735 CustzEqlzrBand7 12;
BA_ "GenSigStartValue" SG_ 735 CustzEqlzrBand7 12;

BA_ "GenSigSendType" SG_ 735 CustzEqlzrBand8 0;
BA_ "SignalLongName" SG_ 735 CustzEqlzrBand8 "Customize_Equalizer_Band_8";
BA_ "GenSigTimeoutValue" SG_ 735 CustzEqlzrBand8 12;
BA_ "GenSigStartValue" SG_ 735 CustzEqlzrBand8 12;

BA_ "GenMsgSendType" BO_ 737 0;
BA_ "GenMsgStartDelayTime" BO_ 737 10;
BA_ "GenMsgCycleTime" BO_ 737 100;
BA_ "GenMsgILSupport" BO_ 737 1;
BA_ "VFrameFormat" BO_ 737 14;

BA_ "GenSigSendType" SG_ 737 VehOdo 0;
BA_ "SignalLongName" SG_ 737 VehOdo "Vehicle Odometer";

BA_ "GenSigSendType" SG_ 737 VehOdoV 0;
BA_ "SignalLongName" SG_ 737 VehOdoV "Vehicle Odometer Validity";

BA_ "GenMsgSendType" BO_ 739 0;
BA_ "GenMsgStartDelayTime" BO_ 739 10;
BA_ "GenMsgCycleTime" BO_ 739 100;
BA_ "GenMsgILSupport" BO_ 739 1;
BA_ "VFrameFormat" BO_ 739 14;

BA_ "GenSigSendType" SG_ 739 RemnDstcDsplyTp 0;
BA_ "SignalLongName" SG_ 739 RemnDstcDsplyTp "RemainDistanceDispalyType";

BA_ "GenSigSendType" SG_ 739 IPKOverSpdFnSts 0;
BA_ "SignalLongName" SG_ 739 IPKOverSpdFnSts "IPKOverSpeedFunctionStatus";

BA_ "GenSigSendType" SG_ 739 DspMeasSys 0;
BA_ "SignalLongName" SG_ 739 DspMeasSys "DisplayMeasureSystemUnit";

BA_ "GenSigSendType" SG_ 739 FuelLvlV 0;
BA_ "SignalLongName" SG_ 739 FuelLvlV "Fuel Level and Fuel Level Percent Validity";

BA_ "GenSigSendType" SG_ 739 IPKOverSpdThreshholdVal 0;
BA_ "SignalLongName" SG_ 739 IPKOverSpdThreshholdVal "IPKOverSpeedThresholdValue";

BA_ "GenSigSendType" SG_ 739 DispdVehSpd 0;
BA_ "SignalLongName" SG_ 739 DispdVehSpd "DisplayeddVehicleSpeed";

BA_ "GenSigSendType" SG_ 739 DispdFuelWrnng 0;
BA_ "SignalLongName" SG_ 739 DispdFuelWrnng "Displayed Fuel Warning";

BA_ "GenSigSendType" SG_ 739 FuelLvlPcnt 0;
BA_ "SignalLongName" SG_ 739 FuelLvlPcnt "Fuel Level Percent";

BA_ "GenSigSendType" SG_ 739 RemnDstcDsplyCyc 0;
BA_ "SignalLongName" SG_ 739 RemnDstcDsplyCyc "Remain Distance Dispaly Cycle";

BA_ "GenSigSendType" SG_ 739 ThemeSettingAdj_2fdbk 0;
BA_ "SignalLongName" SG_ 739 ThemeSettingAdj_2fdbk "ThemeSettingAdjust_2 feedback";
BA_REL_ "GenSigTimeoutTime" BU_SG_REL_ FICM_FD SG_ 300 BMSPackSOCDspV 500;
BA_REL_ "GenSigTimeoutTime" BU_SG_REL_ FICM_FD SG_ 300 BMSPackVolV 500;
BA_REL_ "GenSigTimeoutTime" BU_SG_REL_ FICM_FD SG_ 300 BMSPackCrntV 500;
BA_REL_ "GenSigTimeoutTime" BU_SG_REL_ FICM_FD SG_ 300 BMSPackCrnt 500;
BA_REL_ "GenSigTimeoutTime" BU_SG_REL_ FICM_FD SG_ 300 BMSPackVol 500;
BA_REL_ "GenSigTimeoutTime" BU_SG_REL_ FICM_FD SG_ 300 BMSPackSOCDsp 500;
BA_REL_ "GenSigTimeoutTime" BU_SG_REL_ FICM_FD SG_ 308 PropSysA 250;
BA_REL_ "GenSigTimeoutTime" BU_SG_REL_ FICM_FD SG_ 308 EnStsV 250;
BA_REL_ "GenSigTimeoutTime" BU_SG_REL_ FICM_FD SG_ 308 EnSts 250;
BA_REL_ "GenSigTimeoutTime" BU_SG_REL_ FICM_FD SG_ 308 ClBTopSw 250;
BA_REL_ "GenSigTimeoutTime" BU_SG_REL_ FICM_FD SG_ 308 ClPdlActuPosV 250;
BA_REL_ "GenSigTimeoutTime" BU_SG_REL_ FICM_FD SG_ 308 ClPdlActuPos 250;
BA_REL_ "GenSigTimeoutTime" BU_SG_REL_ FICM_FD SG_ 308 ECM_134h_RllCnt 250;
BA_REL_ "GenSigTimeoutTime" BU_SG_REL_ FICM_FD SG_ 308 ECM_134h_ChkSum 250;
BA_REL_ "GenSigTimeoutTime" BU_SG_REL_ FICM_FD SG_ 322 BMSBscSta 250;
BA_REL_ "GenSigTimeoutTime" BU_SG_REL_ FICM_FD SG_ 322 BMSOnbdChrgrPlugOn 250;
BA_REL_ "GenSigTimeoutTime" BU_SG_REL_ FICM_FD SG_ 322 BMSOfbdChrgrPlugOn 250;
BA_REL_ "GenSigTimeoutTime" BU_SG_REL_ FICM_FD SG_ 336 ADUOrFVCMFctryDeftSetFnsh 250;
BA_REL_ "GenSigTimeoutTime" BU_SG_REL_ FICM_FD SG_ 336 FCMReminderFdbck 250;
BA_REL_ "GenSigTimeoutTime" BU_SG_REL_ FICM_FD SG_ 336 FCM_AEBMainSwFdbck 250;
BA_REL_ "GenSigTimeoutTime" BU_SG_REL_ FICM_FD SG_ 336 FCMMainSensitivityFdbck 250;
BA_REL_ "GenSigTimeoutTime" BU_SG_REL_ FICM_FD SG_ 338 ICA_ALCAMainSwFdbck 250;
BA_REL_ "GenSigTimeoutTime" BU_SG_REL_ FICM_FD SG_ 342 PASoundInfo 250;
BA_REL_ "GenSigTimeoutTime" BU_SG_REL_ FICM_FD SG_ 342 PASoundCtrlSetReqFdbck 250;
BA_REL_ "GenSigTimeoutTime" BU_SG_REL_ FICM_FD SG_ 342 APAFctryDeftSetFnsh 250;
BA_REL_ "GenSigTimeoutTime" BU_SG_REL_ FICM_FD SG_ 342 APALanguageFdbck 250;
BA_REL_ "GenSigTimeoutTime" BU_SG_REL_ FICM_FD SG_ 343 RPASts 250;
BA_REL_ "GenSigTimeoutTime" BU_SG_REL_ FICM_FD SG_ 343 APASts 250;
BA_REL_ "GenSigTimeoutTime" BU_SG_REL_ FICM_FD SG_ 345 AESMainSwFdbck 250;
BA_REL_ "GenSigTimeoutTime" BU_SG_REL_ FICM_FD SG_ 347 LDWAccuracyFdbck 250;
BA_REL_ "GenSigTimeoutTime" BU_SG_REL_ FICM_FD SG_ 347 ELKMainSwFdbck 250;
BA_REL_ "GenSigTimeoutTime" BU_SG_REL_ FICM_FD SG_ 347 LDWReminderFdbck 250;
BA_REL_ "GenSigTimeoutTime" BU_SG_REL_ FICM_FD SG_ 347 LDWSundWrnngFdbck 250;
BA_REL_ "GenSigTimeoutTime" BU_SG_REL_ FICM_FD SG_ 347 LKA_LDW_ELKMainSwFdbck 250;
BA_REL_ "GenSigTimeoutTime" BU_SG_REL_ FICM_FD SG_ 347 LKA_LDWMainSwFdbck 250;
BA_REL_ "GenSigTimeoutTime" BU_SG_REL_ FICM_FD SG_ 381 CampEPTRdy 250;
BA_REL_ "GenSigTimeoutTime" BU_SG_REL_ FICM_FD SG_ 381 HVReady 250;
BA_REL_ "GenSigTimeoutTime" BU_SG_REL_ FICM_FD SG_ 381 CampEPTRunAbotd 250;
BA_REL_ "GenSigTimeoutTime" BU_SG_REL_ FICM_FD SG_ 381 CampEPTCrkAbotd 250;
BA_REL_ "GenSigTimeoutTime" BU_SG_REL_ FICM_FD SG_ 381 CampEPTRunAbotdRsn 250;
BA_REL_ "GenSigTimeoutTime" BU_SG_REL_ FICM_FD SG_ 381 CampEPTCrkAbotdRsn 250;
BA_REL_ "GenSigTimeoutTime" BU_SG_REL_ FICM_FD SG_ 393 VehSpdV 250;
BA_REL_ "GenSigTimeoutTime" BU_SG_REL_ FICM_FD SG_ 393 VehSpd 250;
BA_REL_ "GenSigTimeoutTime" BU_SG_REL_ FICM_FD SG_ 393 VehSpd_RllCnt 250;
BA_REL_ "GenSigTimeoutTime" BU_SG_REL_ FICM_FD SG_ 393 VehSpd_ChkSum 250;
BA_REL_ "GenSigTimeoutTime" BU_SG_REL_ FICM_FD SG_ 402 StrgWhlAng 250;
BA_REL_ "GenSigTimeoutTime" BU_SG_REL_ FICM_FD SG_ 402 StrgWhlAngSnsrFlt 250;
BA_REL_ "GenSigTimeoutTime" BU_SG_REL_ FICM_FD SG_ 402 StrgWhlAngSnsrInid 250;
BA_REL_ "GenSigTimeoutTime" BU_SG_REL_ FICM_FD SG_ 402 StrgWhlAngV 250;
BA_REL_ "GenSigTimeoutTime" BU_SG_REL_ FICM_FD SG_ 402 StrgWhlAngGrd 250;
BA_REL_ "GenSigTimeoutTime" BU_SG_REL_ FICM_FD SG_ 402 StrAnglSnsrInfo_RllCnt 250;
BA_REL_ "GenSigTimeoutTime" BU_SG_REL_ FICM_FD SG_ 402 StrgWhlAngSnsrCalSts 250;
BA_REL_ "GenSigTimeoutTime" BU_SG_REL_ FICM_FD SG_ 402 StrAnglSnsrInfo_ChkSum 250;
BA_REL_ "GenSigTimeoutTime" BU_SG_REL_ FICM_FD SG_ 403 EPSCurrMod 250;
BA_REL_ "GenSigTimeoutTime" BU_SG_REL_ FICM_FD SG_ 403 EPSInfo_RllCnt 250;
BA_REL_ "GenSigTimeoutTime" BU_SG_REL_ FICM_FD SG_ 403 EPSFctryDfltSttngFnshd 250;
BA_REL_ "GenSigTimeoutTime" BU_SG_REL_ FICM_FD SG_ 403 EPSInfo_ChkSum 250;
BA_REL_ "GenSigTimeoutTime" BU_SG_REL_ FICM_FD SG_ 408 EPBSysDispMsgReq 250;
BA_REL_ "GenSigTimeoutTime" BU_SG_REL_ FICM_FD SG_ 408 EPBAppcnSts 250;
BA_REL_ "GenSigTimeoutTime" BU_SG_REL_ FICM_FD SG_ 408 EPBIgnoffAutoAppFnFdbck1 250;
BA_REL_ "GenSigTimeoutTime" BU_SG_REL_ FICM_FD SG_ 441 HUDEnbSetResp 5000;
BA_REL_ "GenSigTimeoutTime" BU_SG_REL_ FICM_FD SG_ 441 HUDDmAdjResp 5000;
BA_REL_ "GenSigTimeoutTime" BU_SG_REL_ FICM_FD SG_ 441 HUDPctAlttdAdjResp 5000;
BA_REL_ "GenSigTimeoutTime" BU_SG_REL_ FICM_FD SG_ 441 HUDPctInclntAdjResp 5000;
BA_REL_ "GenSigTimeoutTime" BU_SG_REL_ FICM_FD SG_ 444 ChmCmdSndLoctnFL 250;
BA_REL_ "GenSigTimeoutTime" BU_SG_REL_ FICM_FD SG_ 444 ChmCmdSndLoctnFR 250;
BA_REL_ "GenSigTimeoutTime" BU_SG_REL_ FICM_FD SG_ 444 ChmCmdSndLoctnRL 250;
BA_REL_ "GenSigTimeoutTime" BU_SG_REL_ FICM_FD SG_ 444 ChmCmdSndLoctnRR 250;
BA_REL_ "GenSigTimeoutTime" BU_SG_REL_ FICM_FD SG_ 444 ChmCmdSndTone 250;
BA_REL_ "GenSigTimeoutTime" BU_SG_REL_ FICM_FD SG_ 444 ChmCmdSndCndcPrd 250;
BA_REL_ "GenSigTimeoutTime" BU_SG_REL_ FICM_FD SG_ 444 ChmCmdSndDutyCyc 250;
BA_REL_ "GenSigTimeoutTime" BU_SG_REL_ FICM_FD SG_ 444 PgTrnUp 250;
BA_REL_ "GenSigTimeoutTime" BU_SG_REL_ FICM_FD SG_ 444 PgTrnDw 250;
BA_REL_ "GenSigTimeoutTime" BU_SG_REL_ FICM_FD SG_ 444 PgTrnRt 250;
BA_REL_ "GenSigTimeoutTime" BU_SG_REL_ FICM_FD SG_ 444 PgTrnLf 250;
BA_REL_ "GenSigTimeoutTime" BU_SG_REL_ FICM_FD SG_ 444 PgTrnOK 250;
BA_REL_ "GenSigTimeoutTime" BU_SG_REL_ FICM_FD SG_ 444 IPKTabReq 250;
BA_REL_ "GenSigTimeoutTime" BU_SG_REL_ FICM_FD SG_ 445 SysPwrMd 500;
BA_REL_ "GenSigTimeoutTime" BU_SG_REL_ FICM_FD SG_ 445 SysPwrMdV 500;
BA_REL_ "GenSigTimeoutTime" BU_SG_REL_ FICM_FD SG_ 445 TransMd 500;
BA_REL_ "GenSigTimeoutTime" BU_SG_REL_ FICM_FD SG_ 445 RVSReq 500;
BA_REL_ "GenSigTimeoutTime" BU_SG_REL_ FICM_FD SG_ 445 VehiclePwrSts_RllCnt 500;
BA_REL_ "GenSigTimeoutTime" BU_SG_REL_ FICM_FD SG_ 445 VehiclePwrSts_ChkSum 500;
BA_REL_ "GenSigTimeoutTime" BU_SG_REL_ FICM_FD SG_ 447 AVHSysDispMsgReq 250;
BA_REL_ "GenSigTimeoutTime" BU_SG_REL_ FICM_FD SG_ 447 ESCFnOffFdbck 250;
BA_REL_ "GenSigTimeoutTime" BU_SG_REL_ FICM_FD SG_ 447 AVHFnFdbck 250;
BA_REL_ "GenSigTimeoutTime" BU_SG_REL_ FICM_FD SG_ 447 HDCFnFdbck 250;
BA_REL_ "GenSigTimeoutTime" BU_SG_REL_ FICM_FD SG_ 447 DrvngMdDisp 250;
BA_REL_ "GenSigTimeoutTime" BU_SG_REL_ FICM_FD SG_ 447 EPBIgnoffAutoAppFnFdbck 250;
BA_REL_ "GenSigTimeoutTime" BU_SG_REL_ FICM_FD SG_ 447 ESC_HMI_RllCnt 250;
BA_REL_ "GenSigTimeoutTime" BU_SG_REL_ FICM_FD SG_ 447 ESC_HMI_ChkSum 250;
BA_REL_ "GenSigTimeoutTime" BU_SG_REL_ FICM_FD SG_ 457 DMSSwFdbck 500;
BA_REL_ "GenSigTimeoutTime" BU_SG_REL_ FICM_FD SG_ 457 FatigueMoniSwFdbck 500;
BA_REL_ "GenSigTimeoutTime" BU_SG_REL_ FICM_FD SG_ 457 DistractionMoniSwFdbck 500;
BA_REL_ "GenSigTimeoutTime" BU_SG_REL_ FICM_FD SG_ 474 IHCMainSwFdbck 500;
BA_REL_ "GenSigTimeoutTime" BU_SG_REL_ FICM_FD SG_ 474 SLIFMainSwFdbck 500;
BA_REL_ "GenSigTimeoutTime" BU_SG_REL_ FICM_FD SG_ 474 SLIFVsulWrnng 500;
BA_REL_ "GenSigTimeoutTime" BU_SG_REL_ FICM_FD SG_ 474 ISAMainSwFdbck 500;
BA_REL_ "GenSigTimeoutTime" BU_SG_REL_ FICM_FD SG_ 474 SLIFSundWrnngFdbck 500;
BA_REL_ "GenSigTimeoutTime" BU_SG_REL_ FICM_FD SG_ 474 SLIF_ISAMainSwFdbck 500;
BA_REL_ "GenSigTimeoutTime" BU_SG_REL_ FICM_FD SG_ 474 IHC_SLIFSts_RllCnt 500;
BA_REL_ "GenSigTimeoutTime" BU_SG_REL_ FICM_FD SG_ 474 IHC_SLIFSts_ChkSum 500;
BA_REL_ "GenSigTimeoutTime" BU_SG_REL_ FICM_FD SG_ 476 RAEBSta 500;
BA_REL_ "GenSigTimeoutTime" BU_SG_REL_ FICM_FD SG_ 478 SRR_RFctryDeftSetFnshSlavetoMstr 500;
BA_REL_ "GenSigTimeoutTime" BU_SG_REL_ FICM_FD SG_ 478 BDASts_R_RllCnt 500;
BA_REL_ "GenSigTimeoutTime" BU_SG_REL_ FICM_FD SG_ 478 BDASts_R_ChkSum 500;
BA_REL_ "GenSigTimeoutTime" BU_SG_REL_ FICM_FD SG_ 479 BSDMainSwFdbck 500;
BA_REL_ "GenSigTimeoutTime" BU_SG_REL_ FICM_FD SG_ 479 SRR_R_MFctryDeftSetFnsh 500;
BA_REL_ "GenSigTimeoutTime" BU_SG_REL_ FICM_FD SG_ 479 BSDLCAMainSwFdbck 500;
BA_REL_ "GenSigTimeoutTime" BU_SG_REL_ FICM_FD SG_ 479 RCTAMainSwFdbck 500;
BA_REL_ "GenSigTimeoutTime" BU_SG_REL_ FICM_FD SG_ 479 DOWMainSwFdbck 500;
BA_REL_ "GenSigTimeoutTime" BU_SG_REL_ FICM_FD SG_ 479 BDASts_L_RllCnt 500;
BA_REL_ "GenSigTimeoutTime" BU_SG_REL_ FICM_FD SG_ 479 BDASts_L_ChkSum 500;
BA_REL_ "GenSigTimeoutTime" BU_SG_REL_ FICM_FD SG_ 485 UltraRdrSnsrSts_1 500;
BA_REL_ "GenSigTimeoutTime" BU_SG_REL_ FICM_FD SG_ 485 UltraRdrSnsrObjWrnngZn_1 500;
BA_REL_ "GenSigTimeoutTime" BU_SG_REL_ FICM_FD SG_ 485 UltraRdrSnsrSts_6 500;
BA_REL_ "GenSigTimeoutTime" BU_SG_REL_ FICM_FD SG_ 485 UltraRdrSnsrObjWrnngZn_6 500;
BA_REL_ "GenSigTimeoutTime" BU_SG_REL_ FICM_FD SG_ 485 UltraRdrSnsrSts_7 500;
BA_REL_ "GenSigTimeoutTime" BU_SG_REL_ FICM_FD SG_ 485 UltraRdrSnsrObjWrnngZn_7 500;
BA_REL_ "GenSigTimeoutTime" BU_SG_REL_ FICM_FD SG_ 485 UltraRdrSnsrSts_12 500;
BA_REL_ "GenSigTimeoutTime" BU_SG_REL_ FICM_FD SG_ 485 UltraRdrSnsrObjWrnngZn_12 500;
BA_REL_ "GenSigTimeoutTime" BU_SG_REL_ FICM_FD SG_ 485 UltraRdrSnsrDist_1 500;
BA_REL_ "GenSigTimeoutTime" BU_SG_REL_ FICM_FD SG_ 485 UltraRdrSnsrDist_6 500;
BA_REL_ "GenSigTimeoutTime" BU_SG_REL_ FICM_FD SG_ 485 UltraRdrSnsrDist_7 500;
BA_REL_ "GenSigTimeoutTime" BU_SG_REL_ FICM_FD SG_ 485 UltraRdrSnsrDist_12 500;
BA_REL_ "GenSigTimeoutTime" BU_SG_REL_ FICM_FD SG_ 486 UltraRdrSnsrSts_8 500;
BA_REL_ "GenSigTimeoutTime" BU_SG_REL_ FICM_FD SG_ 486 UltraRdrSnsrObjWrnngZn_8 500;
BA_REL_ "GenSigTimeoutTime" BU_SG_REL_ FICM_FD SG_ 486 UltraRdrSnsrSts_9 500;
BA_REL_ "GenSigTimeoutTime" BU_SG_REL_ FICM_FD SG_ 486 UltraRdrSnsrObjWrnngZn_9 500;
BA_REL_ "GenSigTimeoutTime" BU_SG_REL_ FICM_FD SG_ 486 UltraRdrSnsrSts_10 500;
BA_REL_ "GenSigTimeoutTime" BU_SG_REL_ FICM_FD SG_ 486 UltraRdrSnsrObjWrnngZn_10 500;
BA_REL_ "GenSigTimeoutTime" BU_SG_REL_ FICM_FD SG_ 486 UltraRdrSnsrSts_11 500;
BA_REL_ "GenSigTimeoutTime" BU_SG_REL_ FICM_FD SG_ 486 UltraRdrSnsrObjWrnngZn_11 500;
BA_REL_ "GenSigTimeoutTime" BU_SG_REL_ FICM_FD SG_ 486 UltraRdrSnsrDist_8 500;
BA_REL_ "GenSigTimeoutTime" BU_SG_REL_ FICM_FD SG_ 486 UltraRdrSnsrDist_9 500;
BA_REL_ "GenSigTimeoutTime" BU_SG_REL_ FICM_FD SG_ 486 UltraRdrSnsrDist_10 500;
BA_REL_ "GenSigTimeoutTime" BU_SG_REL_ FICM_FD SG_ 486 UltraRdrSnsrDist_11 500;
BA_REL_ "GenSigTimeoutTime" BU_SG_REL_ FICM_FD SG_ 486 PDCBeepOffReqFdbck_R 500;
BA_REL_ "GenSigTimeoutTime" BU_SG_REL_ FICM_FD SG_ 487 UltraRdrSnsrSts_2 500;
BA_REL_ "GenSigTimeoutTime" BU_SG_REL_ FICM_FD SG_ 487 UltraRdrSnsrObjWrnngZn_2 500;
BA_REL_ "GenSigTimeoutTime" BU_SG_REL_ FICM_FD SG_ 487 UltraRdrSnsrSts_3 500;
BA_REL_ "GenSigTimeoutTime" BU_SG_REL_ FICM_FD SG_ 487 UltraRdrSnsrObjWrnngZn_3 500;
BA_REL_ "GenSigTimeoutTime" BU_SG_REL_ FICM_FD SG_ 487 UltraRdrSnsrSts_4 500;
BA_REL_ "GenSigTimeoutTime" BU_SG_REL_ FICM_FD SG_ 487 UltraRdrSnsrObjWrnngZn_4 500;
BA_REL_ "GenSigTimeoutTime" BU_SG_REL_ FICM_FD SG_ 487 UltraRdrSnsrSts_5 500;
BA_REL_ "GenSigTimeoutTime" BU_SG_REL_ FICM_FD SG_ 487 UltraRdrSnsrObjWrnngZn_5 500;
BA_REL_ "GenSigTimeoutTime" BU_SG_REL_ FICM_FD SG_ 487 UltraRdrSnsrDist_2 500;
BA_REL_ "GenSigTimeoutTime" BU_SG_REL_ FICM_FD SG_ 487 UltraRdrSnsrDist_3 500;
BA_REL_ "GenSigTimeoutTime" BU_SG_REL_ FICM_FD SG_ 487 UltraRdrSnsrDist_4 500;
BA_REL_ "GenSigTimeoutTime" BU_SG_REL_ FICM_FD SG_ 487 UltraRdrSnsrDist_5 500;
BA_REL_ "GenSigTimeoutTime" BU_SG_REL_ FICM_FD SG_ 487 PDCBeepOffReqFdbck_F 500;
BA_REL_ "GenSigTimeoutTime" BU_SG_REL_ FICM_FD SG_ 487 PDCMainSWFdbck 500;
BA_REL_ "GenSigTimeoutTime" BU_SG_REL_ FICM_FD SG_ 490 AVMSts 500;
BA_REL_ "GenSigTimeoutTime" BU_SG_REL_ FICM_FD SG_ 490 VideoReq 500;
BA_REL_ "GenSigTimeoutTime" BU_SG_REL_ FICM_FD SG_ 490 VideoReqV 500;
BA_REL_ "GenSigTimeoutTime" BU_SG_REL_ FICM_FD SG_ 490 SnsSldDrActnTypSetReqFdbck 500;
BA_REL_ "GenSigTimeoutTime" BU_SG_REL_ FICM_FD SG_ 490 SentryMdSetReqFdbck 500;
BA_REL_ "GenSigTimeoutTime" BU_SG_REL_ FICM_FD SG_ 490 RmtAVMReqFdbck 500;
BA_REL_ "GenSigTimeoutTime" BU_SG_REL_ FICM_FD SG_ 490 SentryMdSensitivityFdbck 500;
BA_REL_ "GenSigTimeoutTime" BU_SG_REL_ FICM_FD SG_ 490 AVMFctryDeftSetFnsh 500;
BA_REL_ "GenSigTimeoutTime" BU_SG_REL_ FICM_FD SG_ 493 SysBkupPwrMd 500;
BA_REL_ "GenSigTimeoutTime" BU_SG_REL_ FICM_FD SG_ 493 SysBkupPwrMdV 500;
BA_REL_ "GenSigTimeoutTime" BU_SG_REL_ FICM_FD SG_ 493 SysBkupPwrMdEnbl 500;
BA_REL_ "GenSigTimeoutTime" BU_SG_REL_ FICM_FD SG_ 493 SysPwrMdBkup_RllCnt 500;
BA_REL_ "GenSigTimeoutTime" BU_SG_REL_ FICM_FD SG_ 493 SysPwrMdBkup_Chksum 500;
BA_REL_ "GenSigTimeoutTime" BU_SG_REL_ FICM_FD SG_ 511 HMIPhCallReq 500;
BA_REL_ "GenSigTimeoutTime" BU_SG_REL_ FICM_FD SG_ 511 HMIMtReq 500;
BA_REL_ "GenSigTimeoutTime" BU_SG_REL_ FICM_FD SG_ 511 HMIVolUpAdjReq 500;
BA_REL_ "GenSigTimeoutTime" BU_SG_REL_ FICM_FD SG_ 511 HMIVolDownAdjReq 500;
BA_REL_ "GenSigTimeoutTime" BU_SG_REL_ FICM_FD SG_ 511 HMIMscNextAdjReq 500;
BA_REL_ "GenSigTimeoutTime" BU_SG_REL_ FICM_FD SG_ 511 HMIMscPreAdjReq 500;
BA_REL_ "GenSigTimeoutTime" BU_SG_REL_ FICM_FD SG_ 511 HMIVoiceReq 500;
BA_REL_ "GenSigTimeoutTime" BU_SG_REL_ FICM_FD SG_ 511 HMITlmtcsReq 500;
BA_REL_ "GenSigTimeoutTime" BU_SG_REL_ FICM_FD SG_ 511 HMISRCReq 500;
BA_REL_ "GenSigTimeoutTime" BU_SG_REL_ FICM_FD SG_ 557 BMSChrgrPlugCnctnIO 1000;
BA_REL_ "GenSigTimeoutTime" BU_SG_REL_ FICM_FD SG_ 557 ChrgngRmnngTimeV 1000;
BA_REL_ "GenSigTimeoutTime" BU_SG_REL_ FICM_FD SG_ 557 BMSAvlblEnrgV 1000;
BA_REL_ "GenSigTimeoutTime" BU_SG_REL_ FICM_FD SG_ 557 ChrgngRmnngTime 1000;
BA_REL_ "GenSigTimeoutTime" BU_SG_REL_ FICM_FD SG_ 557 CampChrgngRmnngTimeExt 1000;
BA_REL_ "GenSigTimeoutTime" BU_SG_REL_ FICM_FD SG_ 557 BMSAvlblEnrg 1000;
BA_REL_ "GenSigTimeoutTime" BU_SG_REL_ FICM_FD SG_ 557 CampChrgngRmnngTimeExtV 1000;
BA_REL_ "GenSigTimeoutTime" BU_SG_REL_ FICM_FD SG_ 557 ChrgngRmnngTimeExtV 1000;
BA_REL_ "GenSigTimeoutTime" BU_SG_REL_ FICM_FD SG_ 557 ChrgngRmnngTimeExt 1000;
BA_REL_ "GenSigTimeoutTime" BU_SG_REL_ FICM_FD SG_ 626 DpfWrnngInf 1000;
BA_REL_ "GenSigTimeoutTime" BU_SG_REL_ FICM_FD SG_ 626 RGNinactivereason 1000;
BA_REL_ "GenSigTimeoutTime" BU_SG_REL_ FICM_FD SG_ 626 RGNPcnt 1000;
BA_REL_ "GenSigTimeoutTime" BU_SG_REL_ FICM_FD SG_ 627 BatVolV 1000;
BA_REL_ "GenSigTimeoutTime" BU_SG_REL_ FICM_FD SG_ 627 BatVol 1000;
BA_REL_ "GenSigTimeoutTime" BU_SG_REL_ FICM_FD SG_ 627 FuelModeFdbk 1000;
BA_REL_ "GenSigTimeoutTime" BU_SG_REL_ FICM_FD SG_ 627 EnStrtactFdbk_V2L 1000;
BA_REL_ "GenSigTimeoutTime" BU_SG_REL_ FICM_FD SG_ 632 Sootmass_Reset 1000;
BA_REL_ "GenSigTimeoutTime" BU_SG_REL_ FICM_FD SG_ 632 Sootmass_max 1000;
BA_REL_ "GenSigTimeoutTime" BU_SG_REL_ FICM_FD SG_ 632 Sootmass_RGN 1000;
BA_REL_ "GenSigTimeoutTime" BU_SG_REL_ FICM_FD SG_ 632 Sootmass 1000;
BA_REL_ "GenSigTimeoutTime" BU_SG_REL_ FICM_FD SG_ 676 OtsdAirTemCrVal 1000;
BA_REL_ "GenSigTimeoutTime" BU_SG_REL_ FICM_FD SG_ 676 OtsdAirTemCrValV 1000;
BA_REL_ "GenSigTimeoutTime" BU_SG_REL_ FICM_FD SG_ 677 HVACFrontAirVolume 1000;
BA_REL_ "GenSigTimeoutTime" BU_SG_REL_ FICM_FD SG_ 677 HVACFrontMode 1000;
BA_REL_ "GenSigTimeoutTime" BU_SG_REL_ FICM_FD SG_ 677 HVACLeftSetTemperature 1000;
BA_REL_ "GenSigTimeoutTime" BU_SG_REL_ FICM_FD SG_ 677 HVACRightSetTemperature 1000;
BA_REL_ "GenSigTimeoutTime" BU_SG_REL_ FICM_FD SG_ 677 HVACInCarTermperature 1000;
BA_REL_ "GenSigTimeoutTime" BU_SG_REL_ FICM_FD SG_ 677 HVACCycleMode 1000;
BA_REL_ "GenSigTimeoutTime" BU_SG_REL_ FICM_FD SG_ 677 HVACFrontDefrostStatus 1000;
BA_REL_ "GenSigTimeoutTime" BU_SG_REL_ FICM_FD SG_ 677 HVACRearDefrostStatus 1000;
BA_REL_ "GenSigTimeoutTime" BU_SG_REL_ FICM_FD SG_ 677 HVACAutoIndicationStatus 1000;
BA_REL_ "GenSigTimeoutTime" BU_SG_REL_ FICM_FD SG_ 677 HVACFrontPowerStatus 1000;
BA_REL_ "GenSigTimeoutTime" BU_SG_REL_ FICM_FD SG_ 677 HVACOnRequestIndication 1000;
BA_REL_ "GenSigTimeoutTime" BU_SG_REL_ FICM_FD SG_ 677 HVACSYNCDspCmd 1000;
BA_REL_ "GenSigTimeoutTime" BU_SG_REL_ FICM_FD SG_ 677 PTC_WRK_LEVEL 1000;
BA_REL_ "GenSigTimeoutTime" BU_SG_REL_ FICM_FD SG_ 677 HVACAtDefSts 1000;
BA_REL_ "GenSigTimeoutTime" BU_SG_REL_ FICM_FD SG_ 677 HVACQuietSetStatus 1000;
BA_REL_ "GenSigTimeoutTime" BU_SG_REL_ FICM_FD SG_ 677 HVACFrontACMaxStatus 1000;
BA_REL_ "GenSigTimeoutTime" BU_SG_REL_ FICM_FD SG_ 677 InsdAirPrtclMtrCDC 1000;
BA_REL_ "GenSigTimeoutTime" BU_SG_REL_ FICM_FD SG_ 679 HVACRearAirVolume 1000;
BA_REL_ "GenSigTimeoutTime" BU_SG_REL_ FICM_FD SG_ 679 HVACRearMode 1000;
BA_REL_ "GenSigTimeoutTime" BU_SG_REL_ FICM_FD SG_ 679 HVACRearSetTemperature 1000;
BA_REL_ "GenSigTimeoutTime" BU_SG_REL_ FICM_FD SG_ 679 HVACRearPowerStatus 1000;
BA_REL_ "GenSigTimeoutTime" BU_SG_REL_ FICM_FD SG_ 679 HVACRearAutoStatus 1000;
BA_REL_ "GenSigTimeoutTime" BU_SG_REL_ FICM_FD SG_ 679 HVACRearAirVolume2 1000;
BA_REL_ "GenSigTimeoutTime" BU_SG_REL_ FICM_FD SG_ 679 HVACOnRequestIndication_R 1000;
BA_REL_ "GenSigTimeoutTime" BU_SG_REL_ FICM_FD SG_ 680 LeftArVetLRSwingSts 1000;
BA_REL_ "GenSigTimeoutTime" BU_SG_REL_ FICM_FD SG_ 680 LeftMidArVetLRSwingSts 1000;
BA_REL_ "GenSigTimeoutTime" BU_SG_REL_ FICM_FD SG_ 680 RightMidArVetLRSwingSts 1000;
BA_REL_ "GenSigTimeoutTime" BU_SG_REL_ FICM_FD SG_ 680 RightArVetSwingLRSts 1000;
BA_REL_ "GenSigTimeoutTime" BU_SG_REL_ FICM_FD SG_ 680 LeftArVetUDSwingSts 1000;
BA_REL_ "GenSigTimeoutTime" BU_SG_REL_ FICM_FD SG_ 680 LeftMidArVetUDSwingSts 1000;
BA_REL_ "GenSigTimeoutTime" BU_SG_REL_ FICM_FD SG_ 680 RightMidArVetUDSwingSts 1000;
BA_REL_ "GenSigTimeoutTime" BU_SG_REL_ FICM_FD SG_ 680 RightArVetSwingUDSts 1000;
BA_REL_ "GenSigTimeoutTime" BU_SG_REL_ FICM_FD SG_ 680 LeftArVetFosSts 1000;
BA_REL_ "GenSigTimeoutTime" BU_SG_REL_ FICM_FD SG_ 680 RightArVetFosSts 1000;
BA_REL_ "GenSigTimeoutTime" BU_SG_REL_ FICM_FD SG_ 680 LeftArVetDistribSts 1000;
BA_REL_ "GenSigTimeoutTime" BU_SG_REL_ FICM_FD SG_ 680 RightArVetDistribSts 1000;
BA_REL_ "GenSigTimeoutTime" BU_SG_REL_ FICM_FD SG_ 680 LeftArVetSweepSts 1000;
BA_REL_ "GenSigTimeoutTime" BU_SG_REL_ FICM_FD SG_ 680 RightArVetSweepSts 1000;
BA_REL_ "GenSigTimeoutTime" BU_SG_REL_ FICM_FD SG_ 680 LeftArVetOnOffSts 1000;
BA_REL_ "GenSigTimeoutTime" BU_SG_REL_ FICM_FD SG_ 680 RightArVetOnOffSts 1000;
BA_REL_ "GenSigTimeoutTime" BU_SG_REL_ FICM_FD SG_ 680 HVACLeavVentSts 1000;
BA_REL_ "GenSigTimeoutTime" BU_SG_REL_ FICM_FD SG_ 681 HVACBloLimtSetSts 1000;
BA_REL_ "GenSigTimeoutTime" BU_SG_REL_ FICM_FD SG_ 681 HVACAtCylTimSts 1000;
BA_REL_ "GenSigTimeoutTime" BU_SG_REL_ FICM_FD SG_ 681 HVACAirFltrLife 1000;
BA_REL_ "GenSigTimeoutTime" BU_SG_REL_ FICM_FD SG_ 681 HVACAIUOnOffDspCmd 1000;
BA_REL_ "GenSigTimeoutTime" BU_SG_REL_ FICM_FD SG_ 682 OtsdAirTemRawData 1000;
BA_REL_ "GenSigTimeoutTime" BU_SG_REL_ FICM_FD SG_ 727 AllMuteFdbk 1000;
BA_REL_ "GenSigTimeoutTime" BU_SG_REL_ FICM_FD SG_ 727 MdaMuteFdbk 1000;
BA_REL_ "GenSigTimeoutTime" BU_SG_REL_ FICM_FD SG_ 727 PhnMuteFdbk 1000;
BA_REL_ "GenSigTimeoutTime" BU_SG_REL_ FICM_FD SG_ 727 NaviMuteFdbk 1000;
BA_REL_ "GenSigTimeoutTime" BU_SG_REL_ FICM_FD SG_ 727 VcMuteFdbk 1000;
BA_REL_ "GenSigTimeoutTime" BU_SG_REL_ FICM_FD SG_ 727 NotiMuteFdbk 1000;
BA_REL_ "GenSigTimeoutTime" BU_SG_REL_ FICM_FD SG_ 727 ChmMuteFdbk 1000;
BA_REL_ "GenSigTimeoutTime" BU_SG_REL_ FICM_FD SG_ 727 ChmSndVolmStepFdbk 1000;
BA_REL_ "GenSigTimeoutTime" BU_SG_REL_ FICM_FD SG_ 727 NotiSndVolmStepFdbk 1000;
BA_REL_ "GenSigTimeoutTime" BU_SG_REL_ FICM_FD SG_ 727 NaviSndVolmStepFdbk 1000;
BA_REL_ "GenSigTimeoutTime" BU_SG_REL_ FICM_FD SG_ 727 MdaSndVolmStepFdbk 1000;
BA_REL_ "GenSigTimeoutTime" BU_SG_REL_ FICM_FD SG_ 727 PhnCallSndVolmStepFdbk 1000;
BA_REL_ "GenSigTimeoutTime" BU_SG_REL_ FICM_FD SG_ 727 VcItatnSndVolmStepFdbk 1000;
BA_REL_ "GenSigTimeoutTime" BU_SG_REL_ FICM_FD SG_ 727 FdrSetngFdbk 1000;
BA_REL_ "GenSigTimeoutTime" BU_SG_REL_ FICM_FD SG_ 728 BalcSetngFdbk 1000;
BA_REL_ "GenSigTimeoutTime" BU_SG_REL_ FICM_FD SG_ 728 AmbcSetngFdbk 1000;
BA_REL_ "GenSigTimeoutTime" BU_SG_REL_ FICM_FD SG_ 728 ThreeDimnSndFldFdbk 1000;
BA_REL_ "GenSigTimeoutTime" BU_SG_REL_ FICM_FD SG_ 728 SpdDpntAutocVolmFdbk 1000;
BA_REL_ "GenSigTimeoutTime" BU_SG_REL_ FICM_FD SG_ 728 AMP_Temp_STS 1000;
BA_REL_ "GenSigTimeoutTime" BU_SG_REL_ FICM_FD SG_ 728 CustzEqlzrPreSetFdbk 1000;
BA_REL_ "GenSigTimeoutTime" BU_SG_REL_ FICM_FD SG_ 728 ChmOutSpkFdbk 1000;
BA_REL_ "GenSigTimeoutTime" BU_SG_REL_ FICM_FD SG_ 728 AMPTurnOnRdyStsFdbk 1000;
BA_REL_ "GenSigTimeoutTime" BU_SG_REL_ FICM_FD SG_ 728 AMPPwrRdySts 1000;
BA_REL_ "GenSigTimeoutTime" BU_SG_REL_ FICM_FD SG_ 728 VirtualSbwfrOnOffReqFdbk 1000;
BA_REL_ "GenSigTimeoutTime" BU_SG_REL_ FICM_FD SG_ 728 LdnsSetngFdbk 1000;
BA_REL_ "GenSigTimeoutTime" BU_SG_REL_ FICM_FD SG_ 728 ANCFunSwFdbk 1000;
BA_REL_ "GenSigTimeoutTime" BU_SG_REL_ FICM_FD SG_ 728 AMP_DTC_INFO 1000;
BA_REL_ "GenSigTimeoutTime" BU_SG_REL_ FICM_FD SG_ 728 ANCWorkInfoFdbk 1000;
BA_REL_ "GenSigTimeoutTime" BU_SG_REL_ FICM_FD SG_ 729 AMPVersionInfo 1000;
BA_REL_ "GenSigTimeoutTime" BU_SG_REL_ FICM_FD SG_ 729 ANCFWVersion 1000;
BA_REL_ "GenSigTimeoutTime" BU_SG_REL_ FICM_FD SG_ 729 RngSndVolmStepFdbk 1000;
BA_REL_ "GenSigTimeoutTime" BU_SG_REL_ FICM_FD SG_ 730 AMPSoundDB 1000;
BA_REL_ "GenSigTimeoutTime" BU_SG_REL_ FICM_FD SG_ 731 CustzEqlzrBand1Dsp 1000;
BA_REL_ "GenSigTimeoutTime" BU_SG_REL_ FICM_FD SG_ 731 CustzEqlzrBand2Dsp 1000;
BA_REL_ "GenSigTimeoutTime" BU_SG_REL_ FICM_FD SG_ 731 CustzEqlzrBand3Dsp 1000;
BA_REL_ "GenSigTimeoutTime" BU_SG_REL_ FICM_FD SG_ 731 CustzEqlzrBand4Dsp 1000;
BA_REL_ "GenSigTimeoutTime" BU_SG_REL_ FICM_FD SG_ 731 CustzEqlzrBand5Dsp 1000;
BA_REL_ "GenSigTimeoutTime" BU_SG_REL_ FICM_FD SG_ 731 CustzEqlzrBand6Dsp 1000;
BA_REL_ "GenSigTimeoutTime" BU_SG_REL_ FICM_FD SG_ 731 CustzEqlzrBand7Dsp 1000;
BA_REL_ "GenSigTimeoutTime" BU_SG_REL_ FICM_FD SG_ 731 CustzEqlzrBand8Dsp 1000;
BA_REL_ "GenSigTimeoutTime" BU_SG_REL_ FICM_FD SG_ 737 VehOdo 1000;
BA_REL_ "GenSigTimeoutTime" BU_SG_REL_ FICM_FD SG_ 737 VehOdoV 1000;
BA_REL_ "GenSigTimeoutTime" BU_SG_REL_ FICM_FD SG_ 739 RemnDstcDsplyTp 1000;
BA_REL_ "GenSigTimeoutTime" BU_SG_REL_ FICM_FD SG_ 739 IPKOverSpdFnSts 1000;
BA_REL_ "GenSigTimeoutTime" BU_SG_REL_ FICM_FD SG_ 739 DspMeasSys 1000;
BA_REL_ "GenSigTimeoutTime" BU_SG_REL_ FICM_FD SG_ 739 FuelLvlV 1000;
BA_REL_ "GenSigTimeoutTime" BU_SG_REL_ FICM_FD SG_ 739 IPKOverSpdThreshholdVal 1000;
BA_REL_ "GenSigTimeoutTime" BU_SG_REL_ FICM_FD SG_ 739 DispdVehSpd 1000;
BA_REL_ "GenSigTimeoutTime" BU_SG_REL_ FICM_FD SG_ 739 DispdFuelWrnng 1000;
BA_REL_ "GenSigTimeoutTime" BU_SG_REL_ FICM_FD SG_ 739 FuelLvlPcnt 1000;
BA_REL_ "GenSigTimeoutTime" BU_SG_REL_ FICM_FD SG_ 739 RemnDstcDsplyCyc 1000;
BA_REL_ "GenSigTimeoutTime" BU_SG_REL_ FICM_FD SG_ 739 ThemeSettingAdj_2fdbk 1000;
VAL_ 300 BMSPackSOCDspV 0 "Invalid" 1 "Valid" ;
VAL_ 300 BMSPackVolV 0 "Invalid" 1 "Valid" ;
VAL_ 300 BMSPackCrntV 0 "invalid" 1 "valid" ;
VAL_ 308 PropSysA 0 "FALSE" 1 "TRUE" ;
VAL_ 308 EnStsV 0 "Invalid" 1 "Valid" ;
VAL_ 308 EnSts 0 "Stop" 1 "Crank" 2 "Running" ;
VAL_ 308 ClBTopSw 0 "Clutch Top Switch Not Pressed" 1 "Clutch Top Switch Pressed" ;
VAL_ 308 ClPdlActuPosV 0 "Invalid" 1 "Valid" ;
VAL_ 322 BMSBscSta 0 "PowerUp" 1 "DriveReady" 2 "DrivePre-charging" 3 "DriveMode" 4 "On-boardChargeReady" 5 "Off-boardChargeReady" 6 "On-boardChargingMode" 7 "Off-boardChargingMode" 8 "OfflineBalance" 9 "Off-boardChargingDone" 10 "On-boardChargingDone" 12 "On-boardPre-charging" 13 "CollisionMode" 14 "Balancing" 15 "Fault" 16 "Off-boardPre-charging" 17 "WirelessChargeReady" 18 "WirelessChargingMode" 19 "WirelessChargingDone" 20 "WirelessPre-charging" ;
VAL_ 322 BMSOnbdChrgrPlugOn 0 "False" 1 "True" ;
VAL_ 322 BMSOfbdChrgrPlugOn 0 "False" 1 "True" ;
VAL_ 336 ADUOrFVCMFctryDeftSetFnsh 0 "No Request" 1 "Successed" 2 "Failed" 3 "Reserved" ;
VAL_ 336 FCMReminderFdbck 0 "Only Auditory" 1 "Auditory and Vibration" ;
VAL_ 336 FCM_AEBMainSwFdbck 1 "ON" 0 "OFF" ;
VAL_ 336 FCMMainSensitivityFdbck 3 "Reserved" 2 "High" 1 "Standard" 0 "Low" ;
VAL_ 338 ICA_ALCAMainSwFdbck 1 "ON" 0 "OFF" ;
VAL_ 342 PASoundInfo 0 "No Request" 1 "Please press the brake pedal and choose parking space" 2 "Find parking space and please stop vehicle if you need to park" 3 "Please press the brake pedal and choose start button" 4 "Parking in start, please pay attention to the surrounding environment " 5 "Parking in suspension " 6 "Parking in continues " 7 "Parking in completed " 8 "Parking in has exited" 9 "Parking out start, please pay attention to the surrounding environment " 10 "Parking out completed " 11 "Parking out suspension " 12 "Parking out continues " 13 "Parking out has exited" 14 "Parking forward,please pay attention to the surrounding environment " 15 "Parking backward,please pay attention to the surrounding environment " ;
VAL_ 342 PASoundCtrlSetReqFdbck 0 "OFF" 1 "ON" ;
VAL_ 342 APAFctryDeftSetFnsh 0 "No Request" 1 "Successed" 2 "Failed" 3 "Reserved" ;
VAL_ 342 APALanguageFdbck 0 "Chinese" 1 "English" ;
VAL_ 343 RPASts 0 "OFF" 1 "Standby " 2 "Enable" 3 "Active" 4 "Failed" 5 "Suspend" 6 "Abort" 7 "Finish" ;
VAL_ 343 APASts 0 "OFF" 1 "Standby " 2 "Enable" 3 "Active" 4 "Failed" 5 "Suspend" 6 "Abort" 7 "Finish" ;
VAL_ 345 AESMainSwFdbck 1 "ON" 0 "OFF" ;
VAL_ 347 LDWAccuracyFdbck 3 "Reserved" 2 "High" 1 "Standard" 0 "Low" ;
VAL_ 347 ELKMainSwFdbck 0 "OFF" 1 "ON" ;
VAL_ 347 LDWReminderFdbck 0 "Only Auditory" 1 "Only Vibration" 2 "Auditory and Vibration" 3 "OFF" ;
VAL_ 347 LDWSundWrnngFdbck 0 "Warning OFF" 1 "Warning ON" ;
VAL_ 347 LKA_LDW_ELKMainSwFdbck 1 "ON" 0 "OFF" ;
VAL_ 347 LKA_LDWMainSwFdbck 0 "OFF" 1 "LDW" 2 "LDW+LKA" ;
VAL_ 381 CampEPTRdy 0 "False" 1 "True" ;
VAL_ 381 HVReady 0 "Not Ready" 1 "Ready" ;
VAL_ 381 CampEPTRunAbotd 0 "False" 1 "True" ;
VAL_ 381 CampEPTCrkAbotd 0 "False" 1 "True" ;
VAL_ 381 CampEPTRunAbotdRsn 0 "No Aborted" 1 "Shifter NonPark" 2 "Vehicle Speed Limit" 3 "Mil Related Dtc" 4 "Lost Communication With Related Node" 5 "In Post Collision" 6 "Low Soc And Low Fuel Level" 7 "Power Mode None Run" 8 "Charging Request" 9 "Dcdc Fault" 10 "Beyond Drive Intended Max Time" 11 "Kl15 Low" 12 "FICM Camp Mode Req Off" 15 "Unknown Reason" ;
VAL_ 381 CampEPTCrkAbotdRsn 0 "No Aborted" 1 "Shifter None Park Or Transmission Crank Not Permit" 2 "Vehicle Speed Limit" 3 "Mil Related Dtc" 4 "Lost Communication With Related Node" 5 "In Post Collision" 6 "Low Soc Or Low Discharge Power" 7 "Power Mode None Off" 8 "In Charging" 9 "Dcdc Fault" 10 "Beyond Max Request Times" 11 "Kl15 Low" 15 "Unknown Reason" ;
VAL_ 393 VehSpdV 1 "Valid" 0 "Invalid" ;
VAL_ 393 VehSpd 32767 "Invalid" ;
VAL_ 402 StrgWhlAng 65535 "error mark" ;
VAL_ 402 StrgWhlAngSnsrFlt 1 "true" 0 "False" ;
VAL_ 402 StrgWhlAngSnsrInid 1 "true" 0 "False" ;
VAL_ 402 StrgWhlAngV 0 "invalid" 1 "Valid" ;
VAL_ 402 StrgWhlAngGrd 4095 "error mark" ;
VAL_ 402 StrgWhlAngSnsrCalSts 3 "unknow" 2 "Calibrated" 1 "Estimated" 0 "unknow" ;
VAL_ 403 EPSCurrMod 0 "DMC not configured" 1 "Normal/ECO" 2 "Sport" 3 "Advance" 4 "Comfort" 7 "Fault" ;
VAL_ 403 EPSFctryDfltSttngFnshd 0 "No Request" 1 "Successed" 2 "Failed" 3 "Reserved" ;
VAL_ 408 EPBSysDispMsgReq 0 "Message #0（Off）" 1 "Message #1 (Press Brake Pedal to Release Park Brake)" 2 "Message #2 (Service Park Brake)" 3 "Message #3 (Park Brake Set)" 4 "Message #4 (Park Brake Released)" 5 "Message #5（FastenSeatbelt and closed drive door）" 6 "Message #6（Open EPB by switch）" 7 "Message #7（Enter Maintenance Mode）" ;
VAL_ 408 EPBAppcnSts 0 "Undefined（未定义）" 1 "Released（卡钳处于释放状态）" 2 "Closed（卡钳处于夹紧状态）" 3 "Releasing（卡钳正处于释放过程中）" 4 "Locking（卡钳正处于夹紧过程中）" 5 "Dynamic（EPB动态驻车）" ;
VAL_ 408 EPBIgnoffAutoAppFnFdbck1 0 "Function off" 1 "Function on" ;
VAL_ 441 HUDEnbSetResp 0 "Disable" 1 "Enable" ;
VAL_ 441 HUDDmAdjResp 0 "0" 1 "1" 2 "2" 3 "3" 4 "4" 5 "5" 6 "6" 7 "7" 8 "8" 9 "9" 10 "10" 11 "11" 12 "12" 13 "13" 14 "14" 15 "15" 16 "16" 17 "17" 18 "18" 19 "19" 20 "20 " ;
VAL_ 441 HUDPctAlttdAdjResp 0 "0" 1 "1" 2 "2" 3 "3" 4 "4" 5 "5" 6 "6" 7 "7" 8 "8" 9 "9" 10 "10" 11 "11" 12 "12" 13 "13" 14 "14" 15 "15" 16 "16" 17 "17" 18 "18" 19 "19" 20 "20 " ;
VAL_ 441 HUDPctInclntAdjResp 0 "0" 1 "1" 2 "2" 3 "3" 4 "4" 5 "5" 6 "6" ;
VAL_ 444 ChmCmdSndLoctnFL 0 "False" 1 "True" ;
VAL_ 444 ChmCmdSndLoctnFR 0 "False" 1 "True" ;
VAL_ 444 ChmCmdSndLoctnRL 0 "False" 1 "True" ;
VAL_ 444 ChmCmdSndLoctnRR 0 "False" 1 "True" ;
VAL_ 444 ChmCmdSndTone 0 "Clack" 1 "Click" 2 "Beep (750 Hz)" 3 "Beep (2000 Hz)" 4 "Gong (750 Hz)" 5 "Gong (850 Hz)" 6 "Idle" ;
VAL_ 444 PgTrnUp 0 "No Request" 1 "Page Up" 2 "Error" 3 "Reserved" ;
VAL_ 444 PgTrnDw 0 "No Request" 1 "Page Down" 2 "Error" 3 "Reserved" ;
VAL_ 444 PgTrnRt 0 "No Request" 1 "Page Right" 2 "Error" 3 "Reserved" ;
VAL_ 444 PgTrnLf 0 "No Request" 1 "Page Left" 2 "Error" 3 "Reserved" ;
VAL_ 444 PgTrnOK 0 "No Request" 1 "Page OK" 2 "Error" 3 "Reserved" ;
VAL_ 444 IPKTabReq 0 "Trip-computer" 1 "Navigation" 2 "Media" 3 "Call" 4 "Warning Information Centre" 5 "Reserved" 6 "Active Safety" 7 "Reserved" ;
VAL_ 445 SysPwrMd 3 "CRANK" 2 "RUN" 1 "ACC" 0 "OFF" ;
VAL_ 445 SysPwrMdV 1 "Valid" 0 "Invalid" ;
VAL_ 445 TransMd 0 "Inactive（In Normal Mode）" 1 "Active（In Trans Mode）" 2 "Error" 3 "Manufacturing_Mode " ;
VAL_ 445 RVSReq 0 "False" 1 "True" ;
VAL_ 447 AVHSysDispMsgReq 0 "No Display" 1 "Message 1(AU HOLD cannot be activated. Close Door and Seat belt.)" 2 "Message 2(Press Brake Pedal to Release AUTO HOLD.)" 3 "Reserved" 4 "Message 4(AUTO HOLD to be deactivated. Press Brake Pedal)" ;
VAL_ 447 ESCFnOffFdbck 0 "ESC Function OFF" 1 "ESC Function ON" ;
VAL_ 447 AVHFnFdbck 0 "AVH Function OFF" 1 "AVH Function ON" ;
VAL_ 447 HDCFnFdbck 0 "HDC Function OFF" 1 "HDC Function ON" ;
VAL_ 447 DrvngMdDisp 0 "Standard" 1 "Sport" 2 "Snow" 3 "Mud" 4 "Sand" 5 "4L" 6 "Economic" 7 "Mode UnKnown" 8 "Auto" 9 "Wade " 10 "Off road " 11 "Rock " 12 "Reserved" 13 "Reserved" 14 "Failed " 15 "Invalid Value" ;
VAL_ 447 EPBIgnoffAutoAppFnFdbck 0 "Function off" 1 "Function on" ;
VAL_ 457 DMSSwFdbck 0 "ON State" 1 "OFF State" ;
VAL_ 457 FatigueMoniSwFdbck 0 "ON State" 1 "OFF State" ;
VAL_ 457 DistractionMoniSwFdbck 0 "ON State" 1 "OFF State" ;
VAL_ 474 IHCMainSwFdbck 1 "ON" 0 "OFF" ;
VAL_ 474 SLIFMainSwFdbck 0 "OFF" 1 "ON" ;
VAL_ 474 SLIFVsulWrnng 0 "No Warning" 1 "Yellow Display" 2 "Speed Value Continuously-Display" 3 "Speed Value Flash" 4 "Undefined" 5 "Continuously-Display" 6 "Intelligence Speed Assist Active" 7 "Cancel speed limit signs Display" ;
VAL_ 474 ISAMainSwFdbck 0 "OFF" 1 "ON" ;
VAL_ 474 SLIFSundWrnngFdbck 0 "Warning OFF" 1 "Warning ON" ;
VAL_ 474 SLIF_ISAMainSwFdbck 1 "ON" 0 "OFF" ;
VAL_ 476 RAEBSta 4 "Active" 3 "Active(no intervention)" 2 "Standby" 1 "Off" 0 "Unavaliable" ;
VAL_ 478 SRR_RFctryDeftSetFnshSlavetoMstr 0 "No Request" 1 "Successed" 2 "Failed" 3 "Reserved" ;
VAL_ 479 BSDMainSwFdbck 1 "ON" 0 "OFF" ;
VAL_ 479 SRR_R_MFctryDeftSetFnsh 0 "No Request" 1 "Successed" 2 "Failed" 3 "Reserved" ;
VAL_ 479 BSDLCAMainSwFdbck 1 "ON" 0 "OFF" ;
VAL_ 479 RCTAMainSwFdbck 1 "ON" 0 "OFF" ;
VAL_ 479 DOWMainSwFdbck 1 "ON" 0 "OFF" ;
VAL_ 485 UltraRdrSnsrSts_1 0 "NoFault" 1 "Falut" ;
VAL_ 485 UltraRdrSnsrObjWrnngZn_1 0 "No Object" 1 "Zone1" 2 "Zone2" 3 "Zone3" 4 "Zone4" 5 "Reserved" 6 "Reserved" 7 "Reserved" ;
VAL_ 485 UltraRdrSnsrSts_6 0 "NoFault" 1 "Falut" ;
VAL_ 485 UltraRdrSnsrObjWrnngZn_6 0 "No Object" 1 "Zone1" 2 "Zone2" 3 "Zone3" 4 "Zone4" 5 "Reserved" 6 "Reserved" 7 "Reserved" ;
VAL_ 485 UltraRdrSnsrSts_7 0 "NoFault" 1 "Falut" ;
VAL_ 485 UltraRdrSnsrObjWrnngZn_7 0 "No Object" 1 "Zone1" 2 "Zone2" 3 "Zone3" 4 "Zone4" 5 "Reserved" 6 "Reserved" 7 "Reserved" ;
VAL_ 485 UltraRdrSnsrSts_12 0 "NoFault" 1 "Falut" ;
VAL_ 485 UltraRdrSnsrObjWrnngZn_12 0 "No Object" 1 "Zone1" 2 "Zone2" 3 "Zone3" 4 "Zone4" 5 "Reserved" 6 "Reserved" 7 "Reserved" ;
VAL_ 485 UltraRdrSnsrDist_1 511 "Invalid" ;
VAL_ 485 UltraRdrSnsrDist_6 511 "Invalid" ;
VAL_ 485 UltraRdrSnsrDist_7 511 "Invalid" ;
VAL_ 485 UltraRdrSnsrDist_12 511 "Invalid" ;
VAL_ 486 UltraRdrSnsrSts_8 0 "NoFault" 1 "Falut" ;
VAL_ 486 UltraRdrSnsrObjWrnngZn_8 0 "No Object" 1 "Zone1" 2 "Zone2" 3 "Zone3" 4 "Zone4" 5 "Reserved" 6 "Reserved" 7 "Reserved" ;
VAL_ 486 UltraRdrSnsrSts_9 0 "NoFault" 1 "Falut" ;
VAL_ 486 UltraRdrSnsrObjWrnngZn_9 0 "No Object" 1 "Zone1" 2 "Zone2" 3 "Zone3" 4 "Zone4" 5 "Reserved" 6 "Reserved" 7 "Reserved" ;
VAL_ 486 UltraRdrSnsrSts_10 0 "NoFault" 1 "Falut" ;
VAL_ 486 UltraRdrSnsrObjWrnngZn_10 0 "No Object" 1 "Zone1" 2 "Zone2" 3 "Zone3" 4 "Zone4" 5 "Reserved" 6 "Reserved" 7 "Reserved" ;
VAL_ 486 UltraRdrSnsrSts_11 0 "NoFault" 1 "Falut" ;
VAL_ 486 UltraRdrSnsrObjWrnngZn_11 0 "No Object" 1 "Zone1" 2 "Zone2" 3 "Zone3" 4 "Zone4" 5 "Reserved" 6 "Reserved" 7 "Reserved" ;
VAL_ 486 UltraRdrSnsrDist_8 255 "Invalid" ;
VAL_ 486 UltraRdrSnsrDist_9 255 "Invalid" ;
VAL_ 486 UltraRdrSnsrDist_10 255 "Invalid" ;
VAL_ 486 UltraRdrSnsrDist_11 255 "Invalid" ;
VAL_ 486 PDCBeepOffReqFdbck_R 0 "Beep On" 1 "Beep Off" ;
VAL_ 487 UltraRdrSnsrSts_2 0 "NoFault" 1 "Falut" ;
VAL_ 487 UltraRdrSnsrObjWrnngZn_2 0 "No Object" 1 "Zone1" 2 "Zone2" 3 "Zone3" 4 "Zone4" 5 "Reserved" 6 "Reserved" 7 "Reserved" ;
VAL_ 487 UltraRdrSnsrSts_3 0 "NoFault" 1 "Falut" ;
VAL_ 487 UltraRdrSnsrObjWrnngZn_3 0 "No Object" 1 "Zone1" 2 "Zone2" 3 "Zone3" 4 "Zone4" 5 "Reserved" 6 "Reserved" 7 "Reserved" ;
VAL_ 487 UltraRdrSnsrSts_4 0 "NoFault" 1 "Falut" ;
VAL_ 487 UltraRdrSnsrObjWrnngZn_4 0 "No Object" 1 "Zone1" 2 "Zone2" 3 "Zone3" 4 "Zone4" 5 "Reserved" 6 "Reserved" 7 "Reserved" ;
VAL_ 487 UltraRdrSnsrSts_5 0 "NoFault" 1 "Falut" ;
VAL_ 487 UltraRdrSnsrObjWrnngZn_5 0 "No Object" 1 "Zone1" 2 "Zone2" 3 "Zone3" 4 "Zone4" 5 "Reserved" 6 "Reserved" 7 "Reserved" ;
VAL_ 487 UltraRdrSnsrDist_2 255 "Invalid" ;
VAL_ 487 UltraRdrSnsrDist_3 255 "Invalid" ;
VAL_ 487 UltraRdrSnsrDist_4 255 "Invalid" ;
VAL_ 487 UltraRdrSnsrDist_5 255 "Invalid" ;
VAL_ 487 PDCBeepOffReqFdbck_F 0 "Beep On" 1 "Beep Off" ;
VAL_ 487 PDCMainSWFdbck 0 "ON" 1 "OFF" 2 "ERROR" ;
VAL_ 490 AVMSts 0 "Shuting down" 1 "Starting" 2 "Show AVM" 3 "Calibration" 4 "Hide" 5 "Fault" 6 "Off road ecosphere" 7 "Reserved" ;
VAL_ 490 VideoReq 0 "No Request" 1 "Request" ;
VAL_ 490 VideoReqV 1 "Valid" 0 "Invalid" ;
VAL_ 490 SnsSldDrActnTypSetReqFdbck 0 "Step On" 1 "Kick Out" ;
VAL_ 490 SentryMdSetReqFdbck 0 "Sentry Mode Off" 1 "Sentry Mode On" ;
VAL_ 490 RmtAVMReqFdbck 0 "Not Active" 1 "Active" ;
VAL_ 490 SentryMdSensitivityFdbck 0 "Low" 1 "Standard" 2 "High" 3 "Reserved" ;
VAL_ 490 AVMFctryDeftSetFnsh 0 "No Request" 1 "Successed" 2 "Failed" 3 "Reserved" ;
VAL_ 493 SysBkupPwrMd 1 "RUN" 0 "OFF" ;
VAL_ 493 SysBkupPwrMdV 1 "Valid" 0 "Invalid" ;
VAL_ 493 SysBkupPwrMdEnbl 1 "Enable" 0 "Disable" ;
VAL_ 511 HMIPhCallReq 0 "No Request" 1 "Press" 2 "Error" 3 "Reserved" ;
VAL_ 511 HMIMtReq 0 "No Request" 1 "Press" 2 "Error" 3 "Reserved" ;
VAL_ 511 HMIVolUpAdjReq 0 "No Request" 1 "Turn Up" 2 "Error" 3 "Reserved" ;
VAL_ 511 HMIVolDownAdjReq 0 "No Request" 1 "Turn Down" 2 "Error" 3 "Reserved" ;
VAL_ 511 HMIMscNextAdjReq 0 "No Request" 1 "Next" 2 "Error" 3 "Reserved" ;
VAL_ 511 HMIMscPreAdjReq 0 "No Request" 1 "Press" 2 "Error" 3 "Reserved" ;
VAL_ 511 HMIVoiceReq 0 "No Request" 1 "Press" 2 "Error" 3 "Reserved" ;
VAL_ 511 HMITlmtcsReq 0 "No Request" 1 "Press" 2 "Error" 3 "Reserved" ;
VAL_ 511 HMISRCReq 0 "No Request" 1 "Turn Up" 2 "Error" 3 "Reserved" ;
VAL_ 557 BMSChrgrPlugCnctnIO 0 "LampOn" 1 "LampOff" ;
VAL_ 557 ChrgngRmnngTimeV 0 "invalid" 1 "valid" ;
VAL_ 557 BMSAvlblEnrgV 0 "Valid
" 1 "Invalid
" ;
VAL_ 557 CampChrgngRmnngTimeExtV 0 "Valid" 1 "Invalid" ;
VAL_ 557 ChrgngRmnngTimeExtV 0 "Valid" 1 "Invalid" ;
VAL_ 626 DpfWrnngInf 0 "No Warning " 1 "Dpf Warning Level 1 " 2 "Dpf Warning Level 2 " 3 "RGN onogoing" 4 "RGN finished" 5 "RGN inactive reason" 6 "Reserved" 7 "Reserved" ;
VAL_ 626 RGNinactivereason 0 "发动机不处于Normal运行模式" 1 "冷却液不处于许可的温度范围 " 2 "机油温度不处于许可的温度范围" 3 "大气压力不处于许可的压力范围" 4 "燃油温度不处于许可的温度范围" 5 "电池电压不充足" 6 "离合器踩下" 7 "不处于空挡" 8 "车速不等于零" 9 "发动机转速不处于许可范围" 10 "内部扭矩不处于许可范围" 11 "油门踏板不处于许可范围" 12 "DPF上游温度不处于许可范围1" 13 "DPF上游温度不处于许可范围2" 14 "DOC上游温度不处于许可范围1" 15 "DOC上游温度不处于许可范围2" 16 "DPF颗粒不高于设定限值" 17 "有DPF相关的故障" 18 "有发动机相关的故障" 19 "最大许可再生时间到了" 20 "DOC和DPF上游温度未在许可时间范围1内达到目标值" 21 "DOC和DPF上游温度未在许可时间范围2内达到目标值" 22 "超过DPF上游的最高许可温度1" 23 "超过DPF上游的最高许可温度2" 24 "超过DOC上游的最高许可温度1" 25 "超过DOC上游的最高许可温度2" 26 "服务站再生命令未发出" 27 "刹车踩下" ;
VAL_ 627 BatVolV 0 "InValid" 1 "Valid" ;
VAL_ 627 FuelModeFdbk 0 "False" 1 "True" ;
VAL_ 627 EnStrtactFdbk_V2L 0 "False" 1 "True" ;
VAL_ 646 FICMShowAVMReq 0 "No Request" 1 "360 Hide" 2 "Show AVM" 3 "Show Calibration" 4 "Show Off-road ecosphere" 5 "Off-road Hide" 6 "Reserved" 7 "Reserved" ;
VAL_ 646 FICMShowAPAReq 0 "No Request" 1 "Hide" 2 "Show " ;
VAL_ 646 FICMAVMSts 0 "Exit 360" 1 "Entre 360" 2 "Reserved" 3 "Reserved" ;
VAL_ 646 AVMTouchEvtTyp 0 "One finger down" 1 "One finger up " 2 "One finger single click" 3 "One finger double click " 4 "One finger long press" 5 "One finger moving " 6 "One finger swipe" 7 "Zoom in " 8 "Zoom out" 9 "Rotate " 10 "ParkingDrag" 11 "Narrow passage function button" 12 "Narrow lane parking space confirmation button" 13 "Target location" ;
VAL_ 676 OtsdAirTemCrValV 0 "Invalid" 1 "Valid" ;
VAL_ 677 HVACFrontAirVolume 15 "Invalid" 9 "auto blower level" 8 "8" 7 "7" 6 "6" 5 "5" 4 "4" 3 "3" 2 "2" 1 "1" 0 "0" ;
VAL_ 677 HVACFrontMode 15 "Invalid" 8 "auto air distribute mode" 7 "Face&Foot&Defrost" 6 "Foot&Defrost" 5 "Face&Defrost" 4 "Face&Foot" 3 "Defrost" 2 "Foot" 1 "Face" 0 "Default" ;
VAL_ 677 HVACLeftSetTemperature 255 "Invalid" ;
VAL_ 677 HVACRightSetTemperature 255 "Invalid" ;
VAL_ 677 HVACInCarTermperature 255 "Invalid" ;
VAL_ 677 HVACCycleMode 3 "Invalid" 2 "Auto Recirculation" 1 "ExteriorCirculation" 0 "InteriorCirculation" ;
VAL_ 677 HVACFrontDefrostStatus 0 "Off" 1 "On" ;
VAL_ 677 HVACRearDefrostStatus 0 "Off" 1 "On" ;
VAL_ 677 HVACAutoIndicationStatus 0 "Off" 1 "On" ;
VAL_ 677 HVACFrontPowerStatus 0 "Off" 1 "On" ;
VAL_ 677 HVACOnRequestIndication 0 "Off" 1 "On" ;
VAL_ 677 HVACSYNCDspCmd 1 "True" 0 "False" ;
VAL_ 677 PTC_WRK_LEVEL 3 "3 level" 2 "2 level" 1 "1 level" 0 "PTC Off" ;
VAL_ 677 HVACAtDefSts 0 "Off" 1 "On" ;
VAL_ 677 HVACQuietSetStatus 0 "Off" 1 "On" ;
VAL_ 677 HVACFrontACMaxStatus 0 "Off" 1 "On" ;
VAL_ 677 InsdAirPrtclMtrCDC 255 "error" 254 "reserved" 253 "Invalid" 252 "reminder on" 251 "reminder off" ;
VAL_ 679 HVACRearAirVolume 15 "Invalid" 9 "auto blower level" 8 "8" 7 "7" 6 "6" 5 "5" 4 "4" 3 "3" 2 "2" 1 "1" 0 "0" ;
VAL_ 679 HVACRearMode 15 "Invalid" 6 "auto air distribute mode" 5 "Defrost" 4 "Foot&Defrost" 3 "Foot" 2 "Face&Foot" 1 "Face" 0 "Default" ;
VAL_ 679 HVACRearSetTemperature 255 "Invalid" ;
VAL_ 679 HVACRearPowerStatus 1 "On" 0 "Off" ;
VAL_ 679 HVACRearAutoStatus 1 "On" 0 "Off" ;
VAL_ 679 HVACRearAirVolume2 15 "Invalid" 9 "auto blower level" 8 "8" 7 "7" 6 "6" 5 "5" 4 "4" 3 "3" 2 "2" 1 "1" 0 "0" ;
VAL_ 679 HVACOnRequestIndication_R 0 "Off" 1 "On" ;
VAL_ 680 LeftArVetLRSwingSts 0 "Closed" ;
VAL_ 680 LeftMidArVetLRSwingSts 0 "Closed" ;
VAL_ 680 RightMidArVetLRSwingSts 0 "Closed" ;
VAL_ 680 RightArVetSwingLRSts 0 "Closed" ;
VAL_ 680 LeftArVetUDSwingSts 0 "Default" ;
VAL_ 680 LeftMidArVetUDSwingSts 0 "Default" ;
VAL_ 680 RightMidArVetUDSwingSts 0 "Default" ;
VAL_ 680 RightArVetSwingUDSts 0 "Default" ;
VAL_ 680 LeftArVetFosSts 0 "Off" 1 "On" ;
VAL_ 680 RightArVetFosSts 0 "Off" 1 "On" ;
VAL_ 680 LeftArVetDistribSts 0 "Off" 1 "On" ;
VAL_ 680 RightArVetDistribSts 0 "Off" 1 "On" ;
VAL_ 680 LeftArVetSweepSts 0 "Off" 1 "On" ;
VAL_ 680 RightArVetSweepSts 0 "Off" 1 "On" ;
VAL_ 680 LeftArVetOnOffSts 0 "Off" 1 "On" ;
VAL_ 680 RightArVetOnOffSts 0 "Off" 1 "On" ;
VAL_ 680 HVACLeavVentSts 0 "Off" 1 "On" ;
VAL_ 681 HVACBloLimtSetSts 0 "Off" 1 "7档" 2 "6档" 3 "5档" ;
VAL_ 681 HVACAtCylTimSts 0 "Off" 1 "10 min" 2 "20 min" 3 "30 min" ;
VAL_ 681 HVACAIUOnOffDspCmd 0 "OFF" 1 "ON" ;
VAL_ 727 AllMuteFdbk 0 "Unmute" 1 "mute" ;
VAL_ 727 MdaMuteFdbk 0 "Unmute" 1 "mute" ;
VAL_ 727 PhnMuteFdbk 0 "Unmute" 1 "mute" ;
VAL_ 727 NaviMuteFdbk 0 "Unmute" 1 "mute" ;
VAL_ 727 VcMuteFdbk 0 "Unmute" 1 "mute" ;
VAL_ 727 NotiMuteFdbk 0 "Unmute" 1 "mute" ;
VAL_ 727 ChmMuteFdbk 0 "Unmute" 1 "mute" ;
VAL_ 727 ChmSndVolmStepFdbk 0 "VoL_Step0" 1 "VoL_Step1" 2 "VoL_Step2" 3 "VoL_Step3" 4 "VoL_Step4" 5 "VoL_Step5" 6 "VoL_Step6" 7 "VoL_Step7" 8 "VoL_Step8" 9 "VoL_Step9" 10 "VoL_Step10" 11 "VoL_Step11" 12 "VoL_Step12" 13 "VoL_Step13" 14 "VoL_Step14" 15 "VoL_Step15" 16 "VoL_Step16" 17 "VoL_Step17" 18 "VoL_Step18" 19 "VoL_Step19" 20 "VoL_Step20" 21 "VoL_Step21" 22 "VoL_Step22" 23 "VoL_Step23" 24 "VoL_Step24" 25 "VoL_Step25" 26 "VoL_Step26" 27 "VoL_Step27" 28 "VoL_Step28" 29 "VoL_Step29" 30 "VoL_Step30" 31 "VoL_Step31" 32 "VoL_Step32" ;
VAL_ 727 NotiSndVolmStepFdbk 0 "VoL_Step0" 1 "VoL_Step1" 2 "VoL_Step2" 3 "VoL_Step3" 4 "VoL_Step4" 5 "VoL_Step5" 6 "VoL_Step6" 7 "VoL_Step7" 8 "VoL_Step8" 9 "VoL_Step9" 10 "VoL_Step10" 11 "VoL_Step11" 12 "VoL_Step12" 13 "VoL_Step13" 14 "VoL_Step14" 15 "VoL_Step15" 16 "VoL_Step16" 17 "VoL_Step17" 18 "VoL_Step18" 19 "VoL_Step19" 20 "VoL_Step20" 21 "VoL_Step21" 22 "VoL_Step22" 23 "VoL_Step23" 24 "VoL_Step24" 25 "VoL_Step25" 26 "VoL_Step26" 27 "VoL_Step27" 28 "VoL_Step28" 29 "VoL_Step29" 30 "VoL_Step30" 31 "VoL_Step31" 32 "VoL_Step32" ;
VAL_ 727 NaviSndVolmStepFdbk 0 "VoL_Step0" 1 "VoL_Step1" 2 "VoL_Step2" 3 "VoL_Step3" 4 "VoL_Step4" 5 "VoL_Step5" 6 "VoL_Step6" 7 "VoL_Step7" 8 "VoL_Step8" 9 "VoL_Step9" 10 "VoL_Step10" 11 "VoL_Step11" 12 "VoL_Step12" 13 "VoL_Step13" 14 "VoL_Step14" 15 "VoL_Step15" 16 "VoL_Step16" 17 "VoL_Step17" 18 "VoL_Step18" 19 "VoL_Step19" 20 "VoL_Step20" 21 "VoL_Step21" 22 "VoL_Step22" 23 "VoL_Step23" 24 "VoL_Step24" 25 "VoL_Step25" 26 "VoL_Step26" 27 "VoL_Step27" 28 "VoL_Step28" 29 "VoL_Step29" 30 "VoL_Step30" 31 "VoL_Step31" 32 "VoL_Step32" ;
VAL_ 727 MdaSndVolmStepFdbk 0 "VoL_Step0" 1 "VoL_Step1" 2 "VoL_Step2" 3 "VoL_Step3" 4 "VoL_Step4" 5 "VoL_Step5" 6 "VoL_Step6" 7 "VoL_Step7" 8 "VoL_Step8" 9 "VoL_Step9" 10 "VoL_Step10" 11 "VoL_Step11" 12 "VoL_Step12" 13 "VoL_Step13" 14 "VoL_Step14" 15 "VoL_Step15" 16 "VoL_Step16" 17 "VoL_Step17" 18 "VoL_Step18" 19 "VoL_Step19" 20 "VoL_Step20" 21 "VoL_Step21" 22 "VoL_Step22" 23 "VoL_Step23" 24 "VoL_Step24" 25 "VoL_Step25" 26 "VoL_Step26" 27 "VoL_Step27" 28 "VoL_Step28" 29 "VoL_Step29" 30 "VoL_Step30" 31 "VoL_Step31" 32 "VoL_Step32" ;
VAL_ 727 PhnCallSndVolmStepFdbk 0 "VoL_Step0" 1 "VoL_Step1" 2 "VoL_Step2" 3 "VoL_Step3" 4 "VoL_Step4" 5 "VoL_Step5" 6 "VoL_Step6" 7 "VoL_Step7" 8 "VoL_Step8" 9 "VoL_Step9" 10 "VoL_Step10" 11 "VoL_Step11" 12 "VoL_Step12" 13 "VoL_Step13" 14 "VoL_Step14" 15 "VoL_Step15" 16 "VoL_Step16" 17 "VoL_Step17" 18 "VoL_Step18" 19 "VoL_Step19" 20 "VoL_Step20" 21 "VoL_Step21" 22 "VoL_Step22" 23 "VoL_Step23" 24 "VoL_Step24" 25 "VoL_Step25" 26 "VoL_Step26" 27 "VoL_Step27" 28 "VoL_Step28" 29 "VoL_Step29" 30 "VoL_Step30" 31 "VoL_Step31" 32 "VoL_Step32" ;
VAL_ 727 VcItatnSndVolmStepFdbk 0 "VoL_Step0" 1 "VoL_Step1" 2 "VoL_Step2" 3 "VoL_Step3" 4 "VoL_Step4" 5 "VoL_Step5" 6 "VoL_Step6" 7 "VoL_Step7" 8 "VoL_Step8" 9 "VoL_Step9" 10 "VoL_Step10" 11 "VoL_Step11" 12 "VoL_Step12" 13 "VoL_Step13" 14 "VoL_Step14" 15 "VoL_Step15" 16 "VoL_Step16" 17 "VoL_Step17" 18 "VoL_Step18" 19 "VoL_Step19" 20 "VoL_Step20" 21 "VoL_Step21" 22 "VoL_Step22" 23 "VoL_Step23" 24 "VoL_Step24" 25 "VoL_Step25" 26 "VoL_Step26" 27 "VoL_Step27" 28 "VoL_Step28" 29 "VoL_Step29" 30 "VoL_Step30" 31 "VoL_Step31" 32 "VoL_Step32" ;
VAL_ 727 FdrSetngFdbk 0 "FdrSetngFdbk__0_Level_7" 1 "FdrSetngFdbk__1_Level_6" 2 "FdrSetngFdbk__2_Level_5" 3 "FdrSetngFdbk__3_Level_4" 4 "FdrSetngFdbk__4_Level_3" 5 "FdrSetngFdbk__5_Level_2" 6 "FdrSetngFdbk__6_Level_1" 7 "FdrSetngFdbk__7_Level_0" 8 "FdrSetngFdbk__8_Level_1" 9 "FdrSetngFdbk__9_Level_2" 10 "FdrSetngFdbk__A_Level_3" 11 "FdrSetngFdbk__B_Level_4" 12 "FdrSetngFdbk__C_Level_5" 13 "FdrSetngFdbk__D_Level_6" 14 "FdrSetngFdbk__E_Level_7" ;
VAL_ 728 BalcSetngFdbk 0 "BalcSetngFdbk__0_Level_7" 1 "BalcSetngFdbk__1_Level_6" 2 "BalcSetngFdbk__2_Level_5" 3 "BalcSetngFdbk__3_Level_4" 4 "BalcSetngFdbk__4_Level_3" 5 "BalcSetngFdbk__5_Level_2" 6 "BalcSetngFdbk__6_Level_1" 7 "BalcSetngFdbk__7_Level_0" 8 "BalcSetngFdbk__8_Level_1" 9 "BalcSetngFdbk__9_Level_2" 10 "BalcSetngFdbk__A_Level_3" 11 "BalcSetngFdbk__B_Level_4" 12 "BalcSetngFdbk__C_Level_5" 13 "BalcSetngFdbk__D_Level_6" 14 "BalcSetngFdbk__E_Level_7" ;
VAL_ 728 AmbcSetngFdbk 0 "AmbcSetngFdbk_0_Off" 1 "AmbcSetngFdbk_1_AllEnjoy" 2 "AmbcSetngFdbk_2_RideAlone" 3 "AmbcSetngFdbk_3_Party" 4 "AmbcSetngFdbk_4_RoyalTheatre" 5 "AmbcSetngFdbk_5_PrivateCinema" ;
VAL_ 728 ThreeDimnSndFldFdbk 0 "ThreeDimnSndFldFdbk_0_Off" 1 "ThreeDimnSndFldFdbk_1_AllPassenger" 2 "ThreeDimnSndFldFdbk_2_Driver" 3 "ThreeDimnSndFldFdbk_3_VipRearSeat" 4 "ThreeDimnSndFldFdbk_4_CenterPoint" 5 "ThreeDimnSndFldFdbk_5_StereoSurrouding" ;
VAL_ 728 SpdDpntAutocVolmFdbk 0 "SpdDpntAutocVolmFdbk_0_Off" 1 "SpdDpntAutocVolmFdbk_1_Low" 2 "SpdDpntAutocVolmFdbk_2_Middle" 3 "SpdDpntAutocVolmFdbk_3_High" ;
VAL_ 728 AMP_Temp_STS 0 "no temperature error" 1 "temperature low/high error" 3 "Invalid" ;
VAL_ 728 CustzEqlzrPreSetFdbk 0 "CustomizeEqlzrchronizationPreSetFeedback_0_Off" 1 "CustomizeEqlzrchronizationPreSetFeedback_1_Preset1" 2 "CustomizeEqlzrchronizationPreSetFeedback_2_Preset2" 3 "CustomizeEqlzrchronizationPreSetFeedback_3_Preset3" 4 "CustomizeEqlzrchronizationPreSetFeedback_4_Preset4" 5 "CustomizeEqlzrchronizationPreSetFeedback_5_Preset5" ;
VAL_ 728 AMPTurnOnRdyStsFdbk 0 "AMPTurnOnRdyStsFdbk_0_TurnOnNotReady" 1 "AMPTurnOnRdyStsFdbk_1_TurnOnReady" ;
VAL_ 728 AMPPwrRdySts 0 "AMPPwrRdySts_0_PowerNotReady" 1 "AMPPwrRdySts_1_PowerReady" ;
VAL_ 728 VirtualSbwfrOnOffReqFdbk 0 "VirtualSbwfrOnOffReqFdbk_0_Off" 1 "VirtualSbwfrOnOffReqFdbk_1_On" ;
VAL_ 728 LdnsSetngFdbk 0 "LdnsSetngFdbk_0_Off" 1 "LdnsSetngFdbk_1_On" ;
VAL_ 728 ANCFunSwFdbk 0 "ANC ON" 1 "ANC OFF" 2 "Test1" 3 "Test2" 15 "Invalid" ;
VAL_ 728 AMP_DTC_INFO 0 "no error in this channel" 1 "short to ground/short to ACC/ open load error" ;
VAL_ 728 ANCWorkInfoFdbk 0 "Stop" 1 "Normal Work" 2 "Get Speed Error" 4 "ADC channel Error" 5 "detect window or sunroof or trunk or door ajar" 6 "Start up error" 255 "Invalid " ;
VAL_ 729 RngSndVolmStepFdbk 0 "VoL_Step0" 1 "VoL_Step1" 2 "VoL_Step2" 3 "VoL_Step3" 4 "VoL_Step4" 5 "VoL_Step5" 6 "VoL_Step6" 7 "VoL_Step7" 8 "VoL_Step8" 9 "VoL_Step9" 10 "VoL_Step10" 11 "VoL_Step11" 12 "VoL_Step12" 13 "VoL_Step13" 14 "VoL_Step14" 15 "VoL_Step15" 16 "VoL_Step16" 17 "VoL_Step17" 18 "VoL_Step18" 19 "VoL_Step19" 20 "VoL_Step20" 21 "VoL_Step21" 22 "VoL_Step22" 23 "VoL_Step23" 24 "VoL_Step24" 25 "VoL_Step25" 26 "VoL_Step26" 27 "VoL_Step27" 28 "VoL_Step28" 29 "VoL_Step29" 30 "VoL_Step30" 31 "VoL_Step31" 32 "VoL_Step32" ;
VAL_ 731 CustzEqlzrBand1Dsp 0 "CustzEqlzrBand1Dsp_0_12dB" 1 "CustzEqlzrBand1Dsp_1_11dB" 2 "CustzEqlzrBand1Dsp_2_10dB" 3 "CustzEqlzrBand1Dsp_3_9dB" 4 "CustzEqlzrBand1Dsp_4_8dB" 5 "CustzEqlzrBand1Dsp_5_7dB" 6 "CustzEqlzrBand1Dsp_6_6dB" 7 "CustzEqlzrBand1Dsp_7_5dB" 8 "CustzEqlzrBand1Dsp_8_4dB" 9 "CustzEqlzrBand1Dsp_9_3dB" 10 "CustzEqlzrBand1Dsp_A_2dB" 11 "CustzEqlzrBand1Dsp_B_1dB" 12 "CustzEqlzrBand1Dsp_C_0dB" 13 "CustzEqlzrBand1Dsp_D_1dB" 14 "CustzEqlzrBand1Dsp_E_2dB" 15 "CustzEqlzrBand1Dsp_F_3dB" 16 "CustzEqlzrBand1Dsp_10_4dB" 17 "CustzEqlzrBand1Dsp_11_5dB" 18 "CustzEqlzrBand1Dsp_12_6dB" 19 "CustzEqlzrBand1Dsp_13_7dB" 20 "CustzEqlzrBand1Dsp_14_8dB" 21 "CustzEqlzrBand1Dsp_15_9dB" 22 "CustzEqlzrBand1Dsp_16_10dB" 23 "CustzEqlzrBand1Dsp_17_11dB" 24 "CustzEqlzrBand1Dsp_18_12dB" ;
VAL_ 731 CustzEqlzrBand2Dsp 0 "CustzEqlzrBand1Dsp_0_12dB" 1 "CustzEqlzrBand1Dsp_1_11dB" 2 "CustzEqlzrBand1Dsp_2_10dB" 3 "CustzEqlzrBand1Dsp_3_9dB" 4 "CustzEqlzrBand1Dsp_4_8dB" 5 "CustzEqlzrBand1Dsp_5_7dB" 6 "CustzEqlzrBand1Dsp_6_6dB" 7 "CustzEqlzrBand1Dsp_7_5dB" 8 "CustzEqlzrBand1Dsp_8_4dB" 9 "CustzEqlzrBand1Dsp_9_3dB" 10 "CustzEqlzrBand1Dsp_A_2dB" 11 "CustzEqlzrBand1Dsp_B_1dB" 12 "CustzEqlzrBand1Dsp_C_0dB" 13 "CustzEqlzrBand1Dsp_D_1dB" 14 "CustzEqlzrBand1Dsp_E_2dB" 15 "CustzEqlzrBand1Dsp_F_3dB" 16 "CustzEqlzrBand1Dsp_10_4dB" 17 "CustzEqlzrBand1Dsp_11_5dB" 18 "CustzEqlzrBand1Dsp_12_6dB" 19 "CustzEqlzrBand1Dsp_13_7dB" 20 "CustzEqlzrBand1Dsp_14_8dB" 21 "CustzEqlzrBand1Dsp_15_9dB" 22 "CustzEqlzrBand1Dsp_16_10dB" 23 "CustzEqlzrBand1Dsp_17_11dB" 24 "CustzEqlzrBand1Dsp_18_12dB" ;
VAL_ 731 CustzEqlzrBand3Dsp 0 "CustzEqlzrBand1Dsp_0_12dB" 1 "CustzEqlzrBand1Dsp_1_11dB" 2 "CustzEqlzrBand1Dsp_2_10dB" 3 "CustzEqlzrBand1Dsp_3_9dB" 4 "CustzEqlzrBand1Dsp_4_8dB" 5 "CustzEqlzrBand1Dsp_5_7dB" 6 "CustzEqlzrBand1Dsp_6_6dB" 7 "CustzEqlzrBand1Dsp_7_5dB" 8 "CustzEqlzrBand1Dsp_8_4dB" 9 "CustzEqlzrBand1Dsp_9_3dB" 10 "CustzEqlzrBand1Dsp_A_2dB" 11 "CustzEqlzrBand1Dsp_B_1dB" 12 "CustzEqlzrBand1Dsp_C_0dB" 13 "CustzEqlzrBand1Dsp_D_1dB" 14 "CustzEqlzrBand1Dsp_E_2dB" 15 "CustzEqlzrBand1Dsp_F_3dB" 16 "CustzEqlzrBand1Dsp_10_4dB" 17 "CustzEqlzrBand1Dsp_11_5dB" 18 "CustzEqlzrBand1Dsp_12_6dB" 19 "CustzEqlzrBand1Dsp_13_7dB" 20 "CustzEqlzrBand1Dsp_14_8dB" 21 "CustzEqlzrBand1Dsp_15_9dB" 22 "CustzEqlzrBand1Dsp_16_10dB" 23 "CustzEqlzrBand1Dsp_17_11dB" 24 "CustzEqlzrBand1Dsp_18_12dB" ;
VAL_ 731 CustzEqlzrBand4Dsp 0 "CustzEqlzrBand1Dsp_0_12dB" 1 "CustzEqlzrBand1Dsp_1_11dB" 2 "CustzEqlzrBand1Dsp_2_10dB" 3 "CustzEqlzrBand1Dsp_3_9dB" 4 "CustzEqlzrBand1Dsp_4_8dB" 5 "CustzEqlzrBand1Dsp_5_7dB" 6 "CustzEqlzrBand1Dsp_6_6dB" 7 "CustzEqlzrBand1Dsp_7_5dB" 8 "CustzEqlzrBand1Dsp_8_4dB" 9 "CustzEqlzrBand1Dsp_9_3dB" 10 "CustzEqlzrBand1Dsp_A_2dB" 11 "CustzEqlzrBand1Dsp_B_1dB" 12 "CustzEqlzrBand1Dsp_C_0dB" 13 "CustzEqlzrBand1Dsp_D_1dB" 14 "CustzEqlzrBand1Dsp_E_2dB" 15 "CustzEqlzrBand1Dsp_F_3dB" 16 "CustzEqlzrBand1Dsp_10_4dB" 17 "CustzEqlzrBand1Dsp_11_5dB" 18 "CustzEqlzrBand1Dsp_12_6dB" 19 "CustzEqlzrBand1Dsp_13_7dB" 20 "CustzEqlzrBand1Dsp_14_8dB" 21 "CustzEqlzrBand1Dsp_15_9dB" 22 "CustzEqlzrBand1Dsp_16_10dB" 23 "CustzEqlzrBand1Dsp_17_11dB" 24 "CustzEqlzrBand1Dsp_18_12dB" ;
VAL_ 731 CustzEqlzrBand5Dsp 0 "CustzEqlzrBand1Dsp_0_12dB" 1 "CustzEqlzrBand1Dsp_1_11dB" 2 "CustzEqlzrBand1Dsp_2_10dB" 3 "CustzEqlzrBand1Dsp_3_9dB" 4 "CustzEqlzrBand1Dsp_4_8dB" 5 "CustzEqlzrBand1Dsp_5_7dB" 6 "CustzEqlzrBand1Dsp_6_6dB" 7 "CustzEqlzrBand1Dsp_7_5dB" 8 "CustzEqlzrBand1Dsp_8_4dB" 9 "CustzEqlzrBand1Dsp_9_3dB" 10 "CustzEqlzrBand1Dsp_A_2dB" 11 "CustzEqlzrBand1Dsp_B_1dB" 12 "CustzEqlzrBand1Dsp_C_0dB" 13 "CustzEqlzrBand1Dsp_D_1dB" 14 "CustzEqlzrBand1Dsp_E_2dB" 15 "CustzEqlzrBand1Dsp_F_3dB" 16 "CustzEqlzrBand1Dsp_10_4dB" 17 "CustzEqlzrBand1Dsp_11_5dB" 18 "CustzEqlzrBand1Dsp_12_6dB" 19 "CustzEqlzrBand1Dsp_13_7dB" 20 "CustzEqlzrBand1Dsp_14_8dB" 21 "CustzEqlzrBand1Dsp_15_9dB" 22 "CustzEqlzrBand1Dsp_16_10dB" 23 "CustzEqlzrBand1Dsp_17_11dB" 24 "CustzEqlzrBand1Dsp_18_12dB" ;
VAL_ 731 CustzEqlzrBand6Dsp 0 "CustzEqlzrBand1Dsp_0_12dB" 1 "CustzEqlzrBand1Dsp_1_11dB" 2 "CustzEqlzrBand1Dsp_2_10dB" 3 "CustzEqlzrBand1Dsp_3_9dB" 4 "CustzEqlzrBand1Dsp_4_8dB" 5 "CustzEqlzrBand1Dsp_5_7dB" 6 "CustzEqlzrBand1Dsp_6_6dB" 7 "CustzEqlzrBand1Dsp_7_5dB" 8 "CustzEqlzrBand1Dsp_8_4dB" 9 "CustzEqlzrBand1Dsp_9_3dB" 10 "CustzEqlzrBand1Dsp_A_2dB" 11 "CustzEqlzrBand1Dsp_B_1dB" 12 "CustzEqlzrBand1Dsp_C_0dB" 13 "CustzEqlzrBand1Dsp_D_1dB" 14 "CustzEqlzrBand1Dsp_E_2dB" 15 "CustzEqlzrBand1Dsp_F_3dB" 16 "CustzEqlzrBand1Dsp_10_4dB" 17 "CustzEqlzrBand1Dsp_11_5dB" 18 "CustzEqlzrBand1Dsp_12_6dB" 19 "CustzEqlzrBand1Dsp_13_7dB" 20 "CustzEqlzrBand1Dsp_14_8dB" 21 "CustzEqlzrBand1Dsp_15_9dB" 22 "CustzEqlzrBand1Dsp_16_10dB" 23 "CustzEqlzrBand1Dsp_17_11dB" 24 "CustzEqlzrBand1Dsp_18_12dB" ;
VAL_ 731 CustzEqlzrBand7Dsp 0 "CustzEqlzrBand1Dsp_0_12dB" 1 "CustzEqlzrBand1Dsp_1_11dB" 2 "CustzEqlzrBand1Dsp_2_10dB" 3 "CustzEqlzrBand1Dsp_3_9dB" 4 "CustzEqlzrBand1Dsp_4_8dB" 5 "CustzEqlzrBand1Dsp_5_7dB" 6 "CustzEqlzrBand1Dsp_6_6dB" 7 "CustzEqlzrBand1Dsp_7_5dB" 8 "CustzEqlzrBand1Dsp_8_4dB" 9 "CustzEqlzrBand1Dsp_9_3dB" 10 "CustzEqlzrBand1Dsp_A_2dB" 11 "CustzEqlzrBand1Dsp_B_1dB" 12 "CustzEqlzrBand1Dsp_C_0dB" 13 "CustzEqlzrBand1Dsp_D_1dB" 14 "CustzEqlzrBand1Dsp_E_2dB" 15 "CustzEqlzrBand1Dsp_F_3dB" 16 "CustzEqlzrBand1Dsp_10_4dB" 17 "CustzEqlzrBand1Dsp_11_5dB" 18 "CustzEqlzrBand1Dsp_12_6dB" 19 "CustzEqlzrBand1Dsp_13_7dB" 20 "CustzEqlzrBand1Dsp_14_8dB" 21 "CustzEqlzrBand1Dsp_15_9dB" 22 "CustzEqlzrBand1Dsp_16_10dB" 23 "CustzEqlzrBand1Dsp_17_11dB" 24 "CustzEqlzrBand1Dsp_18_12dB" ;
VAL_ 731 CustzEqlzrBand8Dsp 0 "CustzEqlzrBand1Dsp_0_12dB" 1 "CustzEqlzrBand1Dsp_1_11dB" 2 "CustzEqlzrBand1Dsp_2_10dB" 3 "CustzEqlzrBand1Dsp_3_9dB" 4 "CustzEqlzrBand1Dsp_4_8dB" 5 "CustzEqlzrBand1Dsp_5_7dB" 6 "CustzEqlzrBand1Dsp_6_6dB" 7 "CustzEqlzrBand1Dsp_7_5dB" 8 "CustzEqlzrBand1Dsp_8_4dB" 9 "CustzEqlzrBand1Dsp_9_3dB" 10 "CustzEqlzrBand1Dsp_A_2dB" 11 "CustzEqlzrBand1Dsp_B_1dB" 12 "CustzEqlzrBand1Dsp_C_0dB" 13 "CustzEqlzrBand1Dsp_D_1dB" 14 "CustzEqlzrBand1Dsp_E_2dB" 15 "CustzEqlzrBand1Dsp_F_3dB" 16 "CustzEqlzrBand1Dsp_10_4dB" 17 "CustzEqlzrBand1Dsp_11_5dB" 18 "CustzEqlzrBand1Dsp_12_6dB" 19 "CustzEqlzrBand1Dsp_13_7dB" 20 "CustzEqlzrBand1Dsp_14_8dB" 21 "CustzEqlzrBand1Dsp_15_9dB" 22 "CustzEqlzrBand1Dsp_16_10dB" 23 "CustzEqlzrBand1Dsp_17_11dB" 24 "CustzEqlzrBand1Dsp_18_12dB" ;
VAL_ 732 AllMuteReq 0 "Unmute" 1 "mute" ;
VAL_ 732 MdaMuteReq 0 "Unmute" 1 "mute" ;
VAL_ 732 PhnMuteReq 0 "Unmute" 1 "mute" ;
VAL_ 732 NaviMuteReq 0 "Unmute" 1 "mute" ;
VAL_ 732 VcMuteReq 0 "Unmute" 1 "mute" ;
VAL_ 732 NotiMuteReq 0 "Unmute" 1 "mute" ;
VAL_ 732 ChmMuteReq 0 "Unmute" 1 "mute" ;
VAL_ 732 FICMAMPStatus 1 "Enable" 0 "Disable" ;
VAL_ 732 ChmSndVolmStepReqV 0 "Valid" 1 "Invalid" ;
VAL_ 732 ChmSndVolmStepReq 0 "VoL_Step0" 1 "VoL_Step1" 2 "VoL_Step2" 3 "VoL_Step3" 4 "VoL_Step4" 5 "VoL_Step5" 6 "VoL_Step6" 7 "VoL_Step7" 8 "VoL_Step8" 9 "VoL_Step9" 10 "VoL_Step10" 11 "VoL_Step11" 12 "VoL_Step12" 13 "VoL_Step13" 14 "VoL_Step14" 15 "VoL_Step15" 16 "VoL_Step16" 17 "VoL_Step17" 18 "VoL_Step18" 19 "VoL_Step19" 20 "VoL_Step20" 21 "VoL_Step21" 22 "VoL_Step22" 23 "VoL_Step23" 24 "VoL_Step24" 25 "VoL_Step25" 26 "VoL_Step26" 27 "VoL_Step27" 28 "VoL_Step28" 29 "VoL_Step29" 30 "VoL_Step30" 31 "VoL_Step31" 32 "VoL_Step32" ;
VAL_ 732 FICMAvlblSts 0 "False" 1 "True" ;
VAL_ 732 NotiSndVolmStepReqV 0 "Valid" 1 "Invalid" ;
VAL_ 732 NotiSndVolmStepReq 0 "VoL_Step0" 1 "VoL_Step1" 2 "VoL_Step2" 3 "VoL_Step3" 4 "VoL_Step4" 5 "VoL_Step5" 6 "VoL_Step6" 7 "VoL_Step7" 8 "VoL_Step8" 9 "VoL_Step9" 10 "VoL_Step10" 11 "VoL_Step11" 12 "VoL_Step12" 13 "VoL_Step13" 14 "VoL_Step14" 15 "VoL_Step15" 16 "VoL_Step16" 17 "VoL_Step17" 18 "VoL_Step18" 19 "VoL_Step19" 20 "VoL_Step20" 21 "VoL_Step21" 22 "VoL_Step22" 23 "VoL_Step23" 24 "VoL_Step24" 25 "VoL_Step25" 26 "VoL_Step26" 27 "VoL_Step27" 28 "VoL_Step28" 29 "VoL_Step29" 30 "VoL_Step30" 31 "VoL_Step31" 32 "VoL_Step32" ;
VAL_ 732 LVDSMdaReady 0 "Not Ready" 1 "Ready" ;
VAL_ 732 MdaSndVolmStepReqV 0 "Valid" 1 "Invalid" ;
VAL_ 732 MdaSndVolmStepReq 0 "VoL_Step0" 1 "VoL_Step1" 2 "VoL_Step2" 3 "VoL_Step3" 4 "VoL_Step4" 5 "VoL_Step5" 6 "VoL_Step6" 7 "VoL_Step7" 8 "VoL_Step8" 9 "VoL_Step9" 10 "VoL_Step10" 11 "VoL_Step11" 12 "VoL_Step12" 13 "VoL_Step13" 14 "VoL_Step14" 15 "VoL_Step15" 16 "VoL_Step16" 17 "VoL_Step17" 18 "VoL_Step18" 19 "VoL_Step19" 20 "VoL_Step20" 21 "VoL_Step21" 22 "VoL_Step22" 23 "VoL_Step23" 24 "VoL_Step24" 25 "VoL_Step25" 26 "VoL_Step26" 27 "VoL_Step27" 28 "VoL_Step28" 29 "VoL_Step29" 30 "VoL_Step30" 31 "VoL_Step31" 32 "VoL_Step32" ;
VAL_ 732 LVDSNavReady 0 "Not Ready" 1 "Ready" ;
VAL_ 732 NaviSndVolmStepReqV 0 "Valid" 1 "Invalid" ;
VAL_ 732 NaviSndVolmStepReq 0 "VoL_Step0" 1 "VoL_Step1" 2 "VoL_Step2" 3 "VoL_Step3" 4 "VoL_Step4" 5 "VoL_Step5" 6 "VoL_Step6" 7 "VoL_Step7" 8 "VoL_Step8" 9 "VoL_Step9" 10 "VoL_Step10" 11 "VoL_Step11" 12 "VoL_Step12" 13 "VoL_Step13" 14 "VoL_Step14" 15 "VoL_Step15" 16 "VoL_Step16" 17 "VoL_Step17" 18 "VoL_Step18" 19 "VoL_Step19" 20 "VoL_Step20" 21 "VoL_Step21" 22 "VoL_Step22" 23 "VoL_Step23" 24 "VoL_Step24" 25 "VoL_Step25" 26 "VoL_Step26" 27 "VoL_Step27" 28 "VoL_Step28" 29 "VoL_Step29" 30 "VoL_Step30" 31 "VoL_Step31" 32 "VoL_Step32" ;
VAL_ 732 LVDSPhReady 0 "Not Ready" 1 "Ready" ;
VAL_ 732 PhnCallSndVolmStepReqV 0 "Valid" 1 "Invalid" ;
VAL_ 732 PhnCallSndVolmStepReq 0 "VoL_Step0" 1 "VoL_Step1" 2 "VoL_Step2" 3 "VoL_Step3" 4 "VoL_Step4" 5 "VoL_Step5" 6 "VoL_Step6" 7 "VoL_Step7" 8 "VoL_Step8" 9 "VoL_Step9" 10 "VoL_Step10" 11 "VoL_Step11" 12 "VoL_Step12" 13 "VoL_Step13" 14 "VoL_Step14" 15 "VoL_Step15" 16 "VoL_Step16" 17 "VoL_Step17" 18 "VoL_Step18" 19 "VoL_Step19" 20 "VoL_Step20" 21 "VoL_Step21" 22 "VoL_Step22" 23 "VoL_Step23" 24 "VoL_Step24" 25 "VoL_Step25" 26 "VoL_Step26" 27 "VoL_Step27" 28 "VoL_Step28" 29 "VoL_Step29" 30 "VoL_Step30" 31 "VoL_Step31" 32 "VoL_Step32" ;
VAL_ 732 VcItatnSndVolmStepReqV 0 "Valid" 1 "Invalid" ;
VAL_ 732 VcItatnSndVolmStepReq 0 "VoL_Step0" 1 "VoL_Step1" 2 "VoL_Step2" 3 "VoL_Step3" 4 "VoL_Step4" 5 "VoL_Step5" 6 "VoL_Step6" 7 "VoL_Step7" 8 "VoL_Step8" 9 "VoL_Step9" 10 "VoL_Step10" 11 "VoL_Step11" 12 "VoL_Step12" 13 "VoL_Step13" 14 "VoL_Step14" 15 "VoL_Step15" 16 "VoL_Step16" 17 "VoL_Step17" 18 "VoL_Step18" 19 "VoL_Step19" 20 "VoL_Step20" 21 "VoL_Step21" 22 "VoL_Step22" 23 "VoL_Step23" 24 "VoL_Step24" 25 "VoL_Step25" 26 "VoL_Step26" 27 "VoL_Step27" 28 "VoL_Step28" 29 "VoL_Step29" 30 "VoL_Step30" 31 "VoL_Step31" 32 "VoL_Step32" ;
VAL_ 732 FdrSetngReqV 0 "Valid" 1 "Invalid" ;
VAL_ 732 FdrSetngReq 0 "FdrSetngReq_0_Level_7" 1 "FdrSetngReq_1_Level_6" 2 "FdrSetngReq_2_Level_5" 3 "FdrSetngReq_3_Level_4" 4 "FdrSetngReq_4_Level_3" 5 "FdrSetngReq_5_Level_2" 6 "FdrSetngReq_6_Level_1" 7 "FdrSetngReq_7_Level_0" 8 "FdrSetngReq_8_Level_1" 9 "FdrSetngReq_9_Level_2" 10 "FdrSetngReq_A_Level_3" 11 "FdrSetngReq_B_Level_4" 12 "FdrSetngReq_C_Level_5" 13 "FdrSetngReq_D_Level_6" 14 "FdrSetngReq_E_Level_7" ;
VAL_ 733 BalcSetngReqV 0 "Valid" 1 "Invalid" ;
VAL_ 733 BalcSetngReq 0 "BalcSetngReq_0_Level_7" 1 "BalcSetngReq_1_Level_6" 2 "BalcSetngReq_2_Level_5" 3 "BalcSetngReq_3_Level_4" 4 "BalcSetngReq_4_Level_3" 5 "BalcSetngReq_5_Level_2" 6 "BalcSetngReq_6_Level_1" 7 "BalcSetngReq_7_Level_0" 8 "BalcSetngReq_8_Level_1" 9 "BalcSetngReq_9_Level_2" 10 "BalcSetngReq_A_Level_3" 11 "BalcSetngReq_B_Level_4" 12 "BalcSetngReq_C_Level_5" 13 "BalcSetngReq_D_Level_6" 14 "BalcSetngReq_E_Level_7" ;
VAL_ 733 AmbcSetngReqV 0 "Valid" 1 "Invalid" ;
VAL_ 733 AmbcSetngReq 0 "AmbcSetngReq_0_Off" 1 "AmbcSetngReq_1_AllEnjoy" 2 "AmbcSetngReq_2_RideAlone" 3 "AmbcSetngReq_3_Party" 4 "AmbcSetngReq_4_RoyalTheatre" 5 "AmbcSetngReq_5_PrivateCinema" ;
VAL_ 733 ThreeDimnSndFldSetngReqV 0 "Valid" 1 "Invalid" ;
VAL_ 733 ThreeDimnSndFldSetngReq 0 "ThreeDimnSndFldSetngReq_0_Off" 1 "ThreeDimnSndFldSetngReq_1_AllPassenger" 2 "ThreeDimnSndFldSetngReq_2_Driver" 3 "ThreeDimnSndFldSetngReq_3_VipRearSeat" 4 "ThreeDimnSndFldSetngReq_4_CenterPoint" 5 "ThreeDimnSndFldSetngReq_5_StereoSurrouding" ;
VAL_ 733 SpdDpntAutocVolmReqV 0 "Valid" 1 "Invalid" ;
VAL_ 733 SpdDpntAutocVolmReq 0 "SpdDpntAutocVolmReq_0_Off" 1 "SpdDpntAutocVolmReq_1_Low" 2 "SpdDpntAutocVolmReq_2_Middle" 3 "SpdDpntAutocVolmReq_3_High" ;
VAL_ 733 CustzEqlzrV 0 "Valid" 1 "Invalid" ;
VAL_ 733 CustzEqlzrPreSet 0 "CustomizeEqlzrchronizationPreSet_0_Off" 1 "CustomizeEqlzrchronizationPreSet_1_Preset1" 2 "CustomizeEqlzrchronizationPreSet_2_Preset2" 3 "CustomizeEqlzrchronizationPreSet_3_Preset3" 4 "CustomizeEqlzrchronizationPreSet_4_Preset4" 5 "CustomizeEqlzrchronizationPreSet_5_Preset5" ;
VAL_ 733 ICMTurnOnRdyStsX 0 "ICMTurnOnRdyStsX_0_TurnOnNotReady" 1 "ICMTurnOnRdyStsX_1_TurnOnReady" ;
VAL_ 733 VirtualSbwfrOnOffReq 0 "VirtualSbwfrOnOffReq_0_Off" 1 "VirtualSbwfrOnOffReq_1_On" ;
VAL_ 733 LdnsSetngSoftSw 0 "LdnsSetngSoftSw_0_Off" 1 "LdnsSetngSoftSw_1_On" ;
VAL_ 733 TelphoComLoctn 0 "TelphoComLoctn_0_Null" 1 "TelphoComLoctn_1_Driver" 2 "TelphoComLoctn_2_Passenger" 3 "TelphoComLoctn_3_RearLeft" 4 "TelphoComLoctn_4_RearRight" 5 "TelphoComLoctn_5_AllPassengers" ;
VAL_ 733 ANCFunSwV 0 "ANCFunSwV_0_Valid" 1 "ANCFunSwV_1_Invalid" ;
VAL_ 733 ANCFunSw 0 "ANC ON" 1 "ANC OFF" 2 "Test1" 3 "Test2" 15 "Invalid" ;
VAL_ 733 VcItatnSndLoctn 0 "VcItatnSndLoctn_0_Null" 1 "VcItatnSndLoctn_1_Driver" 2 "VcItatnSndLoctn_2_Passenger" 3 "VcItatnSndLoctn_3_RearLeft" 4 "VcItatnSndLoctn_4_RearRight" 5 "VcItatnSndLoctn_5_AllPassengers" ;
VAL_ 733 FICM_MusicPlaybackSts 0 "No Playback Status" 1 "Play" 2 "Pause" 3 "Reserved" ;
VAL_ 733 FICM_MdSts 0 "Null" 1 "Multi-media（FM/AM/DAB、USB、bluetooth、CP）" 2 "bluetooth phone" 3 "Reserved" 4 "Reserved" 5 "Reserved" 6 "Reserved" 7 "Reserved" ;
VAL_ 735 CustzEqlzrBand1 0 "CustzEqlzrBand1Dsp_0_12dB" 1 "CustzEqlzrBand1Dsp_1_11dB" 2 "CustzEqlzrBand1Dsp_2_10dB" 3 "CustzEqlzrBand1Dsp_3_9dB" 4 "CustzEqlzrBand1Dsp_4_8dB" 5 "CustzEqlzrBand1Dsp_5_7dB" 6 "CustzEqlzrBand1Dsp_6_6dB" 7 "CustzEqlzrBand1Dsp_7_5dB" 8 "CustzEqlzrBand1Dsp_8_4dB" 9 "CustzEqlzrBand1Dsp_9_3dB" 10 "CustzEqlzrBand1Dsp_A_2dB" 11 "CustzEqlzrBand1Dsp_B_1dB" 12 "CustzEqlzrBand1Dsp_C_0dB" 13 "CustzEqlzrBand1Dsp_D_1dB" 14 "CustzEqlzrBand1Dsp_E_2dB" 15 "CustzEqlzrBand1Dsp_F_3dB" 16 "CustzEqlzrBand1Dsp_10_4dB" 17 "CustzEqlzrBand1Dsp_11_5dB" 18 "CustzEqlzrBand1Dsp_12_6dB" 19 "CustzEqlzrBand1Dsp_13_7dB" 20 "CustzEqlzrBand1Dsp_14_8dB" 21 "CustzEqlzrBand1Dsp_15_9dB" 22 "CustzEqlzrBand1Dsp_16_10dB" 23 "CustzEqlzrBand1Dsp_17_11dB" 24 "CustzEqlzrBand1Dsp_18_12dB" ;
VAL_ 735 CustzEqlzrBand2 0 "CustzEqlzrBand1Dsp_0_12dB" 1 "CustzEqlzrBand1Dsp_1_11dB" 2 "CustzEqlzrBand1Dsp_2_10dB" 3 "CustzEqlzrBand1Dsp_3_9dB" 4 "CustzEqlzrBand1Dsp_4_8dB" 5 "CustzEqlzrBand1Dsp_5_7dB" 6 "CustzEqlzrBand1Dsp_6_6dB" 7 "CustzEqlzrBand1Dsp_7_5dB" 8 "CustzEqlzrBand1Dsp_8_4dB" 9 "CustzEqlzrBand1Dsp_9_3dB" 10 "CustzEqlzrBand1Dsp_A_2dB" 11 "CustzEqlzrBand1Dsp_B_1dB" 12 "CustzEqlzrBand1Dsp_C_0dB" 13 "CustzEqlzrBand1Dsp_D_1dB" 14 "CustzEqlzrBand1Dsp_E_2dB" 15 "CustzEqlzrBand1Dsp_F_3dB" 16 "CustzEqlzrBand1Dsp_10_4dB" 17 "CustzEqlzrBand1Dsp_11_5dB" 18 "CustzEqlzrBand1Dsp_12_6dB" 19 "CustzEqlzrBand1Dsp_13_7dB" 20 "CustzEqlzrBand1Dsp_14_8dB" 21 "CustzEqlzrBand1Dsp_15_9dB" 22 "CustzEqlzrBand1Dsp_16_10dB" 23 "CustzEqlzrBand1Dsp_17_11dB" 24 "CustzEqlzrBand1Dsp_18_12dB" ;
VAL_ 735 CustzEqlzrBand3 0 "CustzEqlzrBand1Dsp_0_12dB" 1 "CustzEqlzrBand1Dsp_1_11dB" 2 "CustzEqlzrBand1Dsp_2_10dB" 3 "CustzEqlzrBand1Dsp_3_9dB" 4 "CustzEqlzrBand1Dsp_4_8dB" 5 "CustzEqlzrBand1Dsp_5_7dB" 6 "CustzEqlzrBand1Dsp_6_6dB" 7 "CustzEqlzrBand1Dsp_7_5dB" 8 "CustzEqlzrBand1Dsp_8_4dB" 9 "CustzEqlzrBand1Dsp_9_3dB" 10 "CustzEqlzrBand1Dsp_A_2dB" 11 "CustzEqlzrBand1Dsp_B_1dB" 12 "CustzEqlzrBand1Dsp_C_0dB" 13 "CustzEqlzrBand1Dsp_D_1dB" 14 "CustzEqlzrBand1Dsp_E_2dB" 15 "CustzEqlzrBand1Dsp_F_3dB" 16 "CustzEqlzrBand1Dsp_10_4dB" 17 "CustzEqlzrBand1Dsp_11_5dB" 18 "CustzEqlzrBand1Dsp_12_6dB" 19 "CustzEqlzrBand1Dsp_13_7dB" 20 "CustzEqlzrBand1Dsp_14_8dB" 21 "CustzEqlzrBand1Dsp_15_9dB" 22 "CustzEqlzrBand1Dsp_16_10dB" 23 "CustzEqlzrBand1Dsp_17_11dB" 24 "CustzEqlzrBand1Dsp_18_12dB" ;
VAL_ 735 CustzEqlzrBand4 0 "CustzEqlzrBand1Dsp_0_12dB" 1 "CustzEqlzrBand1Dsp_1_11dB" 2 "CustzEqlzrBand1Dsp_2_10dB" 3 "CustzEqlzrBand1Dsp_3_9dB" 4 "CustzEqlzrBand1Dsp_4_8dB" 5 "CustzEqlzrBand1Dsp_5_7dB" 6 "CustzEqlzrBand1Dsp_6_6dB" 7 "CustzEqlzrBand1Dsp_7_5dB" 8 "CustzEqlzrBand1Dsp_8_4dB" 9 "CustzEqlzrBand1Dsp_9_3dB" 10 "CustzEqlzrBand1Dsp_A_2dB" 11 "CustzEqlzrBand1Dsp_B_1dB" 12 "CustzEqlzrBand1Dsp_C_0dB" 13 "CustzEqlzrBand1Dsp_D_1dB" 14 "CustzEqlzrBand1Dsp_E_2dB" 15 "CustzEqlzrBand1Dsp_F_3dB" 16 "CustzEqlzrBand1Dsp_10_4dB" 17 "CustzEqlzrBand1Dsp_11_5dB" 18 "CustzEqlzrBand1Dsp_12_6dB" 19 "CustzEqlzrBand1Dsp_13_7dB" 20 "CustzEqlzrBand1Dsp_14_8dB" 21 "CustzEqlzrBand1Dsp_15_9dB" 22 "CustzEqlzrBand1Dsp_16_10dB" 23 "CustzEqlzrBand1Dsp_17_11dB" 24 "CustzEqlzrBand1Dsp_18_12dB" ;
VAL_ 735 CustzEqlzrBand5 0 "CustzEqlzrBand1Dsp_0_12dB" 1 "CustzEqlzrBand1Dsp_1_11dB" 2 "CustzEqlzrBand1Dsp_2_10dB" 3 "CustzEqlzrBand1Dsp_3_9dB" 4 "CustzEqlzrBand1Dsp_4_8dB" 5 "CustzEqlzrBand1Dsp_5_7dB" 6 "CustzEqlzrBand1Dsp_6_6dB" 7 "CustzEqlzrBand1Dsp_7_5dB" 8 "CustzEqlzrBand1Dsp_8_4dB" 9 "CustzEqlzrBand1Dsp_9_3dB" 10 "CustzEqlzrBand1Dsp_A_2dB" 11 "CustzEqlzrBand1Dsp_B_1dB" 12 "CustzEqlzrBand1Dsp_C_0dB" 13 "CustzEqlzrBand1Dsp_D_1dB" 14 "CustzEqlzrBand1Dsp_E_2dB" 15 "CustzEqlzrBand1Dsp_F_3dB" 16 "CustzEqlzrBand1Dsp_10_4dB" 17 "CustzEqlzrBand1Dsp_11_5dB" 18 "CustzEqlzrBand1Dsp_12_6dB" 19 "CustzEqlzrBand1Dsp_13_7dB" 20 "CustzEqlzrBand1Dsp_14_8dB" 21 "CustzEqlzrBand1Dsp_15_9dB" 22 "CustzEqlzrBand1Dsp_16_10dB" 23 "CustzEqlzrBand1Dsp_17_11dB" 24 "CustzEqlzrBand1Dsp_18_12dB" ;
VAL_ 735 CustzEqlzrBand6 0 "CustzEqlzrBand1Dsp_0_12dB" 1 "CustzEqlzrBand1Dsp_1_11dB" 2 "CustzEqlzrBand1Dsp_2_10dB" 3 "CustzEqlzrBand1Dsp_3_9dB" 4 "CustzEqlzrBand1Dsp_4_8dB" 5 "CustzEqlzrBand1Dsp_5_7dB" 6 "CustzEqlzrBand1Dsp_6_6dB" 7 "CustzEqlzrBand1Dsp_7_5dB" 8 "CustzEqlzrBand1Dsp_8_4dB" 9 "CustzEqlzrBand1Dsp_9_3dB" 10 "CustzEqlzrBand1Dsp_A_2dB" 11 "CustzEqlzrBand1Dsp_B_1dB" 12 "CustzEqlzrBand1Dsp_C_0dB" 13 "CustzEqlzrBand1Dsp_D_1dB" 14 "CustzEqlzrBand1Dsp_E_2dB" 15 "CustzEqlzrBand1Dsp_F_3dB" 16 "CustzEqlzrBand1Dsp_10_4dB" 17 "CustzEqlzrBand1Dsp_11_5dB" 18 "CustzEqlzrBand1Dsp_12_6dB" 19 "CustzEqlzrBand1Dsp_13_7dB" 20 "CustzEqlzrBand1Dsp_14_8dB" 21 "CustzEqlzrBand1Dsp_15_9dB" 22 "CustzEqlzrBand1Dsp_16_10dB" 23 "CustzEqlzrBand1Dsp_17_11dB" 24 "CustzEqlzrBand1Dsp_18_12dB" ;
VAL_ 735 CustzEqlzrBand7 0 "CustzEqlzrBand1Dsp_0_12dB" 1 "CustzEqlzrBand1Dsp_1_11dB" 2 "CustzEqlzrBand1Dsp_2_10dB" 3 "CustzEqlzrBand1Dsp_3_9dB" 4 "CustzEqlzrBand1Dsp_4_8dB" 5 "CustzEqlzrBand1Dsp_5_7dB" 6 "CustzEqlzrBand1Dsp_6_6dB" 7 "CustzEqlzrBand1Dsp_7_5dB" 8 "CustzEqlzrBand1Dsp_8_4dB" 9 "CustzEqlzrBand1Dsp_9_3dB" 10 "CustzEqlzrBand1Dsp_A_2dB" 11 "CustzEqlzrBand1Dsp_B_1dB" 12 "CustzEqlzrBand1Dsp_C_0dB" 13 "CustzEqlzrBand1Dsp_D_1dB" 14 "CustzEqlzrBand1Dsp_E_2dB" 15 "CustzEqlzrBand1Dsp_F_3dB" 16 "CustzEqlzrBand1Dsp_10_4dB" 17 "CustzEqlzrBand1Dsp_11_5dB" 18 "CustzEqlzrBand1Dsp_12_6dB" 19 "CustzEqlzrBand1Dsp_13_7dB" 20 "CustzEqlzrBand1Dsp_14_8dB" 21 "CustzEqlzrBand1Dsp_15_9dB" 22 "CustzEqlzrBand1Dsp_16_10dB" 23 "CustzEqlzrBand1Dsp_17_11dB" 24 "CustzEqlzrBand1Dsp_18_12dB" ;
VAL_ 735 CustzEqlzrBand8 0 "CustzEqlzrBand1Dsp_0_12dB" 1 "CustzEqlzrBand1Dsp_1_11dB" 2 "CustzEqlzrBand1Dsp_2_10dB" 3 "CustzEqlzrBand1Dsp_3_9dB" 4 "CustzEqlzrBand1Dsp_4_8dB" 5 "CustzEqlzrBand1Dsp_5_7dB" 6 "CustzEqlzrBand1Dsp_6_6dB" 7 "CustzEqlzrBand1Dsp_7_5dB" 8 "CustzEqlzrBand1Dsp_8_4dB" 9 "CustzEqlzrBand1Dsp_9_3dB" 10 "CustzEqlzrBand1Dsp_A_2dB" 11 "CustzEqlzrBand1Dsp_B_1dB" 12 "CustzEqlzrBand1Dsp_C_0dB" 13 "CustzEqlzrBand1Dsp_D_1dB" 14 "CustzEqlzrBand1Dsp_E_2dB" 15 "CustzEqlzrBand1Dsp_F_3dB" 16 "CustzEqlzrBand1Dsp_10_4dB" 17 "CustzEqlzrBand1Dsp_11_5dB" 18 "CustzEqlzrBand1Dsp_12_6dB" 19 "CustzEqlzrBand1Dsp_13_7dB" 20 "CustzEqlzrBand1Dsp_14_8dB" 21 "CustzEqlzrBand1Dsp_15_9dB" 22 "CustzEqlzrBand1Dsp_16_10dB" 23 "CustzEqlzrBand1Dsp_17_11dB" 24 "CustzEqlzrBand1Dsp_18_12dB" ;
VAL_ 737 VehOdoV 0 "Invalid" 1 "Valid" ;
VAL_ 739 RemnDstcDsplyTp 0 "Dynamic" 1 "Standard" ;
VAL_ 739 IPKOverSpdFnSts 0 "OFF" 1 "ON" ;
VAL_ 739 DspMeasSys 0 "kph" 1 "MPH" ;
VAL_ 739 FuelLvlV 0 "Invalid" 1 "Valid" ;
VAL_ 739 DispdVehSpd 255 "Invalid" ;
VAL_ 739 DispdFuelWrnng 0 "No Warning" 1 "Warning" ;
VAL_ 739 FuelLvlPcnt 255 "Invalid" ;
VAL_ 739 RemnDstcDsplyCyc 0 "CLTC" 1 "WLTC" ;
VAL_ 739 ThemeSettingAdj_2fdbk 0 "theme1" 1 "theme2" 2 "reserved" 3 "reserved" ;
